VERSION "HINBNNNYYNNNYYNNNNNNNNNNNNYNNNYYYNNYNNNNNN/4//%%/4/'%**4NNN///"

NS_ :

BS_:

BU_: VirtualNMTMaster Sensor_3_ID28 Sensor_2_ID27 Sensor_1_ID23 Display_ID10

BO_ 1546 CSDO_010: 8 Vector__XXX
 SG_ ExpectedConfigurationTime11_0002 m117 : 32|32@1+ (1,0) [0|4294967295] ""  Display_ID10
 SG_ ExpectedConfigurationTime11_0003 m116 : 32|32@1+ (1,0) [0|4294967295] ""  Display_ID10
 SG_ ExpectedConfigurationTime11_0004 m115 : 32|32@1+ (1,0) [0|4294967295] ""  Display_ID10
 SG_ ExpectedConfigurationTime11_0005 m114 : 32|32@1+ (1,0) [0|4294967295] ""  Display_ID10
 SG_ ExpectedConfigurationTime11_0006 m113 : 32|32@1+ (1,0) [0|4294967295] ""  Display_ID10
 SG_ ExpectedConfigurationTime11_0007 m112 : 32|32@1+ (1,0) [0|4294967295] ""  Display_ID10
 SG_ ExpectedConfigurationTime11_0008 m111 : 32|32@1+ (1,0) [0|4294967295] ""  Display_ID10
 SG_ ExpectedConfigurationTime11_0009 m110 : 32|32@1+ (1,0) [0|4294967295] ""  Display_ID10
 SG_ ExpectedConfigurationTime10_0000 m109 : 32|32@1+ (1,0) [0|4294967295] ""  Display_ID10
 SG_ ExpectedConfigurationTime10_0001 m108 : 32|32@1+ (1,0) [0|4294967295] ""  Display_ID10
 SG_ ExpectedConfigurationTime10_0002 m107 : 32|32@1+ (1,0) [0|4294967295] ""  Display_ID10
 SG_ ExpectedConfigurationTime10_0003 m106 : 32|32@1+ (1,0) [0|4294967295] ""  Display_ID10
 SG_ ExpectedConfigurationTime10_0004 m105 : 32|32@1+ (1,0) [0|4294967295] ""  Display_ID10
 SG_ ExpectedConfigurationTime10_0005 m104 : 32|32@1+ (1,0) [0|4294967295] ""  Display_ID10
 SG_ ExpectedConfigurationTime10_0006 m103 : 32|32@1+ (1,0) [0|4294967295] ""  Display_ID10
 SG_ ExpectedConfigurationTime10_0007 m102 : 32|32@1+ (1,0) [0|4294967295] ""  Display_ID10
 SG_ ExpectedConfigurationTime10_0008 m101 : 32|32@1+ (1,0) [0|4294967295] ""  Display_ID10
 SG_ ExpectedConfigurationTime10_0009 m100 : 32|32@1+ (1,0) [0|4294967295] ""  Display_ID10
 SG_ ExpectedConfigurationTime99_0000 m99 : 32|32@1+ (1,0) [0|4294967295] ""  Display_ID10
 SG_ ExpectedConfigurationTime98_0000 m98 : 32|32@1+ (1,0) [0|4294967295] ""  Display_ID10
 SG_ ExpectedConfigurationTime97_0000 m97 : 32|32@1+ (1,0) [0|4294967295] ""  Display_ID10
 SG_ ExpectedConfigurationTime96_0000 m96 : 32|32@1+ (1,0) [0|4294967295] ""  Display_ID10
 SG_ ExpectedConfigurationTime95_0000 m95 : 32|32@1+ (1,0) [0|4294967295] ""  Display_ID10
 SG_ ExpectedConfigurationTime94_0000 m94 : 32|32@1+ (1,0) [0|4294967295] ""  Display_ID10
 SG_ ExpectedConfigurationTime93_0000 m93 : 32|32@1+ (1,0) [0|4294967295] ""  Display_ID10
 SG_ ExpectedConfigurationTime92_0000 m92 : 32|32@1+ (1,0) [0|4294967295] ""  Display_ID10
 SG_ ExpectedConfigurationTime91_0000 m91 : 32|32@1+ (1,0) [0|4294967295] ""  Display_ID10
 SG_ ExpectedConfigurationTime90_0000 m90 : 32|32@1+ (1,0) [0|4294967295] ""  Display_ID10
 SG_ ExpectedConfigurationTime89_0000 m89 : 32|32@1+ (1,0) [0|4294967295] ""  Display_ID10
 SG_ ExpectedConfigurationTime88_0000 m88 : 32|32@1+ (1,0) [0|4294967295] ""  Display_ID10
 SG_ ExpectedConfigurationTime87_0000 m87 : 32|32@1+ (1,0) [0|4294967295] ""  Display_ID10
 SG_ ExpectedConfigurationTime86_0000 m86 : 32|32@1+ (1,0) [0|4294967295] ""  Display_ID10
 SG_ ExpectedConfigurationTime85_0000 m85 : 32|32@1+ (1,0) [0|4294967295] ""  Display_ID10
 SG_ ExpectedConfigurationTime84_0000 m84 : 32|32@1+ (1,0) [0|4294967295] ""  Display_ID10
 SG_ ExpectedConfigurationTime83_0000 m83 : 32|32@1+ (1,0) [0|4294967295] ""  Display_ID10
 SG_ ExpectedConfigurationTime82_0000 m82 : 32|32@1+ (1,0) [0|4294967295] ""  Display_ID10
 SG_ ExpectedConfigurationTime81_0000 m81 : 32|32@1+ (1,0) [0|4294967295] ""  Display_ID10
 SG_ ExpectedConfigurationTime80_0000 m80 : 32|32@1+ (1,0) [0|4294967295] ""  Display_ID10
 SG_ ExpectedConfigurationTime79_0000 m79 : 32|32@1+ (1,0) [0|4294967295] ""  Display_ID10
 SG_ ExpectedConfigurationTime78_0000 m78 : 32|32@1+ (1,0) [0|4294967295] ""  Display_ID10
 SG_ ExpectedConfigurationTime77_0000 m77 : 32|32@1+ (1,0) [0|4294967295] ""  Display_ID10
 SG_ ExpectedConfigurationTime76_0000 m76 : 32|32@1+ (1,0) [0|4294967295] ""  Display_ID10
 SG_ ExpectedConfigurationTime75_0000 m75 : 32|32@1+ (1,0) [0|4294967295] ""  Display_ID10
 SG_ ExpectedConfigurationTime74_0000 m74 : 32|32@1+ (1,0) [0|4294967295] ""  Display_ID10
 SG_ ExpectedConfigurationTime73_0000 m73 : 32|32@1+ (1,0) [0|4294967295] ""  Display_ID10
 SG_ ExpectedConfigurationTime72_0000 m72 : 32|32@1+ (1,0) [0|4294967295] ""  Display_ID10
 SG_ ExpectedConfigurationTime71_0000 m71 : 32|32@1+ (1,0) [0|4294967295] ""  Display_ID10
 SG_ ExpectedConfigurationTime70_0000 m70 : 32|32@1+ (1,0) [0|4294967295] ""  Display_ID10
 SG_ ExpectedConfigurationTime69_0000 m69 : 32|32@1+ (1,0) [0|4294967295] ""  Display_ID10
 SG_ ExpectedConfigurationTime68_0000 m68 : 32|32@1+ (1,0) [0|4294967295] ""  Display_ID10
 SG_ ExpectedConfigurationTime67_0000 m67 : 32|32@1+ (1,0) [0|4294967295] ""  Display_ID10
 SG_ ExpectedConfigurationTime66_0000 m66 : 32|32@1+ (1,0) [0|4294967295] ""  Display_ID10
 SG_ ExpectedConfigurationTime65_0000 m65 : 32|32@1+ (1,0) [0|4294967295] ""  Display_ID10
 SG_ ExpectedConfigurationTime64_0000 m64 : 32|32@1+ (1,0) [0|4294967295] ""  Display_ID10
 SG_ ExpectedConfigurationTime63_0000 m63 : 32|32@1+ (1,0) [0|4294967295] ""  Display_ID10
 SG_ ExpectedConfigurationTime62_0000 m62 : 32|32@1+ (1,0) [0|4294967295] ""  Display_ID10
 SG_ ExpectedConfigurationTime61_0000 m61 : 32|32@1+ (1,0) [0|4294967295] ""  Display_ID10
 SG_ ExpectedConfigurationTime60_0000 m60 : 32|32@1+ (1,0) [0|4294967295] ""  Display_ID10
 SG_ ExpectedConfigurationTime59_0000 m59 : 32|32@1+ (1,0) [0|4294967295] ""  Display_ID10
 SG_ ExpectedConfigurationTime58_0000 m58 : 32|32@1+ (1,0) [0|4294967295] ""  Display_ID10
 SG_ ExpectedConfigurationTime57_0000 m57 : 32|32@1+ (1,0) [0|4294967295] ""  Display_ID10
 SG_ ExpectedConfigurationTime56_0000 m56 : 32|32@1+ (1,0) [0|4294967295] ""  Display_ID10
 SG_ ExpectedConfigurationTime55_0000 m55 : 32|32@1+ (1,0) [0|4294967295] ""  Display_ID10
 SG_ ExpectedConfigurationTime54_0000 m54 : 32|32@1+ (1,0) [0|4294967295] ""  Display_ID10
 SG_ ExpectedConfigurationTime53_0000 m53 : 32|32@1+ (1,0) [0|4294967295] ""  Display_ID10
 SG_ ExpectedConfigurationTime52_0000 m52 : 32|32@1+ (1,0) [0|4294967295] ""  Display_ID10
 SG_ ExpectedConfigurationTime51_0000 m51 : 32|32@1+ (1,0) [0|4294967295] ""  Display_ID10
 SG_ ExpectedConfigurationTime50_0000 m50 : 32|32@1+ (1,0) [0|4294967295] ""  Display_ID10
 SG_ ExpectedConfigurationTime49_0000 m49 : 32|32@1+ (1,0) [0|4294967295] ""  Display_ID10
 SG_ ExpectedConfigurationTime48_0000 m48 : 32|32@1+ (1,0) [0|4294967295] ""  Display_ID10
 SG_ ExpectedConfigurationTime47_0000 m47 : 32|32@1+ (1,0) [0|4294967295] ""  Display_ID10
 SG_ ExpectedConfigurationTime46_0000 m46 : 32|32@1+ (1,0) [0|4294967295] ""  Display_ID10
 SG_ ExpectedConfigurationTime45_0000 m45 : 32|32@1+ (1,0) [0|4294967295] ""  Display_ID10
 SG_ ExpectedConfigurationTime44_0000 m44 : 32|32@1+ (1,0) [0|4294967295] ""  Display_ID10
 SG_ ExpectedConfigurationTime43_0000 m43 : 32|32@1+ (1,0) [0|4294967295] ""  Display_ID10
 SG_ ExpectedConfigurationTime42_0000 m42 : 32|32@1+ (1,0) [0|4294967295] ""  Display_ID10
 SG_ ExpectedConfigurationTime41_0000 m41 : 32|32@1+ (1,0) [0|4294967295] ""  Display_ID10
 SG_ ExpectedConfigurationTime40_0000 m40 : 32|32@1+ (1,0) [0|4294967295] ""  Display_ID10
 SG_ ExpectedConfigurationTime39_0000 m39 : 32|32@1+ (1,0) [0|4294967295] ""  Display_ID10
 SG_ ExpectedConfigurationTime38_0000 m38 : 32|32@1+ (1,0) [0|4294967295] ""  Display_ID10
 SG_ ExpectedConfigurationTime37_0000 m37 : 32|32@1+ (1,0) [0|4294967295] ""  Display_ID10
 SG_ ExpectedConfigurationTime36_0000 m36 : 32|32@1+ (1,0) [0|4294967295] ""  Display_ID10
 SG_ ExpectedConfigurationTime35_0000 m35 : 32|32@1+ (1,0) [0|4294967295] ""  Display_ID10
 SG_ ExpectedConfigurationTime34_0000 m34 : 32|32@1+ (1,0) [0|4294967295] ""  Display_ID10
 SG_ ExpectedConfigurationTime33_0000 m33 : 32|32@1+ (1,0) [0|4294967295] ""  Display_ID10
 SG_ ExpectedConfigurationTime32_0000 m32 : 32|32@1+ (1,0) [0|4294967295] ""  Display_ID10
 SG_ ExpectedConfigurationTime31_0000 m31 : 32|32@1+ (1,0) [0|4294967295] ""  Display_ID10
 SG_ ExpectedConfigurationTime30_0000 m30 : 32|32@1+ (1,0) [0|4294967295] ""  Display_ID10
 SG_ ExpectedConfigurationTime29_0000 m29 : 32|32@1+ (1,0) [0|4294967295] ""  Display_ID10
 SG_ ExpectedConfigurationTime28_0000 m28 : 32|32@1+ (1,0) [0|4294967295] ""  Display_ID10
 SG_ ExpectedConfigurationTime27_0000 m27 : 32|32@1+ (1,0) [0|4294967295] ""  Display_ID10
 SG_ ExpectedConfigurationTime26_0000 m26 : 32|32@1+ (1,0) [0|4294967295] ""  Display_ID10
 SG_ ExpectedConfigurationTime25_0000 m25 : 32|32@1+ (1,0) [0|4294967295] ""  Display_ID10
 SG_ ExpectedConfigurationTime24_0000 m24 : 32|32@1+ (1,0) [0|4294967295] ""  Display_ID10
 SG_ ExpectedConfigurationTime23_0000 m23 : 32|32@1+ (1,0) [0|4294967295] ""  Display_ID10
 SG_ ExpectedConfigurationTime22_0000 m22 : 32|32@1+ (1,0) [0|4294967295] ""  Display_ID10
 SG_ ExpectedConfigurationTime21_0000 m21 : 32|32@1+ (1,0) [0|4294967295] ""  Display_ID10
 SG_ ExpectedConfigurationTime20_0000 m20 : 32|32@1+ (1,0) [0|4294967295] ""  Display_ID10
 SG_ ExpectedConfigurationTime19_0000 m19 : 32|32@1+ (1,0) [0|4294967295] ""  Display_ID10
 SG_ ExpectedConfigurationTime18_0000 m18 : 32|32@1+ (1,0) [0|4294967295] ""  Display_ID10
 SG_ ExpectedConfigurationTime17_0000 m17 : 32|32@1+ (1,0) [0|4294967295] ""  Display_ID10
 SG_ ExpectedConfigurationTime16_0000 m16 : 32|32@1+ (1,0) [0|4294967295] ""  Display_ID10
 SG_ ExpectedConfigurationTime15_0000 m15 : 32|32@1+ (1,0) [0|4294967295] ""  Display_ID10
 SG_ ExpectedConfigurationTime14_0000 m14 : 32|32@1+ (1,0) [0|4294967295] ""  Display_ID10
 SG_ ExpectedConfigurationTime13_0000 m13 : 32|32@1+ (1,0) [0|4294967295] ""  Display_ID10
 SG_ ExpectedConfigurationTime12_0008 m12 : 32|32@1+ (1,0) [0|4294967295] ""  Display_ID10
 SG_ ExpectedConfigurationTime11_0010 m11 : 32|32@1+ (1,0) [0|4294967295] ""  Display_ID10
 SG_ ExpectedConfigurationTime10_0010 m10 : 32|32@1+ (1,0) [0|4294967295] ""  Display_ID10
 SG_ ExpectedConfigurationTime9__0000 m9 : 32|32@1+ (1,0) [0|4294967295] ""  Display_ID10
 SG_ ExpectedConfigurationTime8__0000 m8 : 32|32@1+ (1,0) [0|4294967295] ""  Display_ID10
 SG_ ExpectedConfigurationTime7__0000 m7 : 32|32@1+ (1,0) [0|4294967295] ""  Display_ID10
 SG_ ExpectedConfigurationTime6__0000 m6 : 32|32@1+ (1,0) [0|4294967295] ""  Display_ID10
 SG_ ExpectedConfigurationTime5__0000 m5 : 32|32@1+ (1,0) [0|4294967295] ""  Display_ID10
 SG_ ExpectedConfigurationTime4__0000 m4 : 32|32@1+ (1,0) [0|4294967295] ""  Display_ID10
 SG_ ExpectedConfigurationTime3__0000 m3 : 32|32@1+ (1,0) [0|4294967295] ""  Display_ID10
 SG_ ExpectedConfigurationTime2__0000 m2 : 32|32@1+ (1,0) [0|4294967295] ""  Display_ID10
 SG_ ExpectedConfigurationTime1__0000 m1 : 32|32@1+ (1,0) [0|4294967295] ""  Display_ID10
 SG_ NrOfObjects_1F27_00 m0 : 32|8@1+ (1,0) [0|255] ""  Display_ID10
 SG_ SubIndex_1F27 m7975M : 24|8@1+ (1,0) [0|127] ""  Display_ID10
 SG_ ExpectedConfigurationDate12_0000 m127 : 32|32@1+ (1,0) [0|4294967295] ""  Display_ID10
 SG_ ExpectedConfigurationDate12_0001 m126 : 32|32@1+ (1,0) [0|4294967295] ""  Display_ID10
 SG_ ExpectedConfigurationDate12_0002 m125 : 32|32@1+ (1,0) [0|4294967295] ""  Display_ID10
 SG_ ExpectedConfigurationDate12_0003 m124 : 32|32@1+ (1,0) [0|4294967295] ""  Display_ID10
 SG_ ExpectedConfigurationDate12_0004 m123 : 32|32@1+ (1,0) [0|4294967295] ""  Display_ID10
 SG_ ExpectedConfigurationDate12_0005 m122 : 32|32@1+ (1,0) [0|4294967295] ""  Display_ID10
 SG_ ExpectedConfigurationDate12_0006 m121 : 32|32@1+ (1,0) [0|4294967295] ""  Display_ID10
 SG_ ExpectedConfigurationDate12_0007 m120 : 32|32@1+ (1,0) [0|4294967295] ""  Display_ID10
 SG_ ExpectedConfigurationDate11_0000 m119 : 32|32@1+ (1,0) [0|4294967295] ""  Display_ID10
 SG_ ExpectedConfigurationDate11_0001 m118 : 32|32@1+ (1,0) [0|4294967295] ""  Display_ID10
 SG_ ExpectedConfigurationDate11_0002 m117 : 32|32@1+ (1,0) [0|4294967295] ""  Display_ID10
 SG_ ExpectedConfigurationDate11_0003 m116 : 32|32@1+ (1,0) [0|4294967295] ""  Display_ID10
 SG_ ExpectedConfigurationDate11_0004 m115 : 32|32@1+ (1,0) [0|4294967295] ""  Display_ID10
 SG_ ExpectedConfigurationDate11_0005 m114 : 32|32@1+ (1,0) [0|4294967295] ""  Display_ID10
 SG_ ExpectedConfigurationDate11_0006 m113 : 32|32@1+ (1,0) [0|4294967295] ""  Display_ID10
 SG_ ExpectedConfigurationDate11_0007 m112 : 32|32@1+ (1,0) [0|4294967295] ""  Display_ID10
 SG_ ExpectedConfigurationDate11_0008 m111 : 32|32@1+ (1,0) [0|4294967295] ""  Display_ID10
 SG_ ExpectedConfigurationDate11_0009 m110 : 32|32@1+ (1,0) [0|4294967295] ""  Display_ID10
 SG_ ExpectedConfigurationDate10_0000 m109 : 32|32@1+ (1,0) [0|4294967295] ""  Display_ID10
 SG_ ExpectedConfigurationDate10_0001 m108 : 32|32@1+ (1,0) [0|4294967295] ""  Display_ID10
 SG_ ExpectedConfigurationDate10_0002 m107 : 32|32@1+ (1,0) [0|4294967295] ""  Display_ID10
 SG_ ExpectedConfigurationDate10_0003 m106 : 32|32@1+ (1,0) [0|4294967295] ""  Display_ID10
 SG_ ExpectedConfigurationDate10_0004 m105 : 32|32@1+ (1,0) [0|4294967295] ""  Display_ID10
 SG_ ExpectedConfigurationDate10_0005 m104 : 32|32@1+ (1,0) [0|4294967295] ""  Display_ID10
 SG_ ExpectedConfigurationDate10_0006 m103 : 32|32@1+ (1,0) [0|4294967295] ""  Display_ID10
 SG_ ExpectedConfigurationDate10_0007 m102 : 32|32@1+ (1,0) [0|4294967295] ""  Display_ID10
 SG_ ExpectedConfigurationDate10_0008 m101 : 32|32@1+ (1,0) [0|4294967295] ""  Display_ID10
 SG_ ExpectedConfigurationDate10_0009 m100 : 32|32@1+ (1,0) [0|4294967295] ""  Display_ID10
 SG_ ExpectedConfigurationDate99_0000 m99 : 32|32@1+ (1,0) [0|4294967295] ""  Display_ID10
 SG_ ExpectedConfigurationDate98_0000 m98 : 32|32@1+ (1,0) [0|4294967295] ""  Display_ID10
 SG_ ExpectedConfigurationDate97_0000 m97 : 32|32@1+ (1,0) [0|4294967295] ""  Display_ID10
 SG_ ExpectedConfigurationDate96_0000 m96 : 32|32@1+ (1,0) [0|4294967295] ""  Display_ID10
 SG_ ExpectedConfigurationDate95_0000 m95 : 32|32@1+ (1,0) [0|4294967295] ""  Display_ID10
 SG_ ExpectedConfigurationDate94_0000 m94 : 32|32@1+ (1,0) [0|4294967295] ""  Display_ID10
 SG_ ExpectedConfigurationDate93_0000 m93 : 32|32@1+ (1,0) [0|4294967295] ""  Display_ID10
 SG_ ExpectedConfigurationDate92_0000 m92 : 32|32@1+ (1,0) [0|4294967295] ""  Display_ID10
 SG_ ExpectedConfigurationDate91_0000 m91 : 32|32@1+ (1,0) [0|4294967295] ""  Display_ID10
 SG_ ExpectedConfigurationDate90_0000 m90 : 32|32@1+ (1,0) [0|4294967295] ""  Display_ID10
 SG_ ExpectedConfigurationDate89_0000 m89 : 32|32@1+ (1,0) [0|4294967295] ""  Display_ID10
 SG_ ExpectedConfigurationDate88_0000 m88 : 32|32@1+ (1,0) [0|4294967295] ""  Display_ID10
 SG_ ExpectedConfigurationDate87_0000 m87 : 32|32@1+ (1,0) [0|4294967295] ""  Display_ID10
 SG_ ExpectedConfigurationDate86_0000 m86 : 32|32@1+ (1,0) [0|4294967295] ""  Display_ID10
 SG_ ExpectedConfigurationDate85_0000 m85 : 32|32@1+ (1,0) [0|4294967295] ""  Display_ID10
 SG_ ExpectedConfigurationDate84_0000 m84 : 32|32@1+ (1,0) [0|4294967295] ""  Display_ID10
 SG_ ExpectedConfigurationDate83_0000 m83 : 32|32@1+ (1,0) [0|4294967295] ""  Display_ID10
 SG_ ExpectedConfigurationDate82_0000 m82 : 32|32@1+ (1,0) [0|4294967295] ""  Display_ID10
 SG_ ExpectedConfigurationDate81_0000 m81 : 32|32@1+ (1,0) [0|4294967295] ""  Display_ID10
 SG_ ExpectedConfigurationDate80_0000 m80 : 32|32@1+ (1,0) [0|4294967295] ""  Display_ID10
 SG_ ExpectedConfigurationDate79_0000 m79 : 32|32@1+ (1,0) [0|4294967295] ""  Display_ID10
 SG_ ExpectedConfigurationDate78_0000 m78 : 32|32@1+ (1,0) [0|4294967295] ""  Display_ID10
 SG_ ExpectedConfigurationDate77_0000 m77 : 32|32@1+ (1,0) [0|4294967295] ""  Display_ID10
 SG_ ExpectedConfigurationDate76_0000 m76 : 32|32@1+ (1,0) [0|4294967295] ""  Display_ID10
 SG_ ExpectedConfigurationDate75_0000 m75 : 32|32@1+ (1,0) [0|4294967295] ""  Display_ID10
 SG_ ExpectedConfigurationDate74_0000 m74 : 32|32@1+ (1,0) [0|4294967295] ""  Display_ID10
 SG_ ExpectedConfigurationDate73_0000 m73 : 32|32@1+ (1,0) [0|4294967295] ""  Display_ID10
 SG_ ExpectedConfigurationDate72_0000 m72 : 32|32@1+ (1,0) [0|4294967295] ""  Display_ID10
 SG_ ExpectedConfigurationDate71_0000 m71 : 32|32@1+ (1,0) [0|4294967295] ""  Display_ID10
 SG_ ExpectedConfigurationDate70_0000 m70 : 32|32@1+ (1,0) [0|4294967295] ""  Display_ID10
 SG_ ExpectedConfigurationDate69_0000 m69 : 32|32@1+ (1,0) [0|4294967295] ""  Display_ID10
 SG_ ExpectedConfigurationDate68_0000 m68 : 32|32@1+ (1,0) [0|4294967295] ""  Display_ID10
 SG_ ExpectedConfigurationDate67_0000 m67 : 32|32@1+ (1,0) [0|4294967295] ""  Display_ID10
 SG_ ExpectedConfigurationDate66_0000 m66 : 32|32@1+ (1,0) [0|4294967295] ""  Display_ID10
 SG_ ExpectedConfigurationDate65_0000 m65 : 32|32@1+ (1,0) [0|4294967295] ""  Display_ID10
 SG_ ExpectedConfigurationDate64_0000 m64 : 32|32@1+ (1,0) [0|4294967295] ""  Display_ID10
 SG_ ExpectedConfigurationDate63_0000 m63 : 32|32@1+ (1,0) [0|4294967295] ""  Display_ID10
 SG_ ExpectedConfigurationDate62_0000 m62 : 32|32@1+ (1,0) [0|4294967295] ""  Display_ID10
 SG_ ExpectedConfigurationDate61_0000 m61 : 32|32@1+ (1,0) [0|4294967295] ""  Display_ID10
 SG_ ExpectedConfigurationDate60_0000 m60 : 32|32@1+ (1,0) [0|4294967295] ""  Display_ID10
 SG_ ExpectedConfigurationDate59_0000 m59 : 32|32@1+ (1,0) [0|4294967295] ""  Display_ID10
 SG_ ExpectedConfigurationDate58_0000 m58 : 32|32@1+ (1,0) [0|4294967295] ""  Display_ID10
 SG_ ExpectedConfigurationDate57_0000 m57 : 32|32@1+ (1,0) [0|4294967295] ""  Display_ID10
 SG_ ExpectedConfigurationDate56_0000 m56 : 32|32@1+ (1,0) [0|4294967295] ""  Display_ID10
 SG_ ExpectedConfigurationDate55_0000 m55 : 32|32@1+ (1,0) [0|4294967295] ""  Display_ID10
 SG_ ExpectedConfigurationDate54_0000 m54 : 32|32@1+ (1,0) [0|4294967295] ""  Display_ID10
 SG_ ExpectedConfigurationDate53_0000 m53 : 32|32@1+ (1,0) [0|4294967295] ""  Display_ID10
 SG_ ExpectedConfigurationDate52_0000 m52 : 32|32@1+ (1,0) [0|4294967295] ""  Display_ID10
 SG_ ExpectedConfigurationDate51_0000 m51 : 32|32@1+ (1,0) [0|4294967295] ""  Display_ID10
 SG_ ExpectedConfigurationDate50_0000 m50 : 32|32@1+ (1,0) [0|4294967295] ""  Display_ID10
 SG_ ExpectedConfigurationDate49_0000 m49 : 32|32@1+ (1,0) [0|4294967295] ""  Display_ID10
 SG_ ExpectedConfigurationDate48_0000 m48 : 32|32@1+ (1,0) [0|4294967295] ""  Display_ID10
 SG_ ExpectedConfigurationDate47_0000 m47 : 32|32@1+ (1,0) [0|4294967295] ""  Display_ID10
 SG_ ExpectedConfigurationDate46_0000 m46 : 32|32@1+ (1,0) [0|4294967295] ""  Display_ID10
 SG_ ExpectedConfigurationDate45_0000 m45 : 32|32@1+ (1,0) [0|4294967295] ""  Display_ID10
 SG_ ExpectedConfigurationDate44_0000 m44 : 32|32@1+ (1,0) [0|4294967295] ""  Display_ID10
 SG_ ExpectedConfigurationDate43_0000 m43 : 32|32@1+ (1,0) [0|4294967295] ""  Display_ID10
 SG_ ExpectedConfigurationDate42_0000 m42 : 32|32@1+ (1,0) [0|4294967295] ""  Display_ID10
 SG_ ExpectedConfigurationDate41_0000 m41 : 32|32@1+ (1,0) [0|4294967295] ""  Display_ID10
 SG_ ExpectedConfigurationDate40_0000 m40 : 32|32@1+ (1,0) [0|4294967295] ""  Display_ID10
 SG_ ExpectedConfigurationDate39_0000 m39 : 32|32@1+ (1,0) [0|4294967295] ""  Display_ID10
 SG_ ExpectedConfigurationDate38_0000 m38 : 32|32@1+ (1,0) [0|4294967295] ""  Display_ID10
 SG_ ExpectedConfigurationDate37_0000 m37 : 32|32@1+ (1,0) [0|4294967295] ""  Display_ID10
 SG_ ExpectedConfigurationDate36_0000 m36 : 32|32@1+ (1,0) [0|4294967295] ""  Display_ID10
 SG_ ExpectedConfigurationDate35_0000 m35 : 32|32@1+ (1,0) [0|4294967295] ""  Display_ID10
 SG_ ExpectedConfigurationDate34_0000 m34 : 32|32@1+ (1,0) [0|4294967295] ""  Display_ID10
 SG_ ExpectedConfigurationDate33_0000 m33 : 32|32@1+ (1,0) [0|4294967295] ""  Display_ID10
 SG_ ExpectedConfigurationDate32_0000 m32 : 32|32@1+ (1,0) [0|4294967295] ""  Display_ID10
 SG_ ExpectedConfigurationDate31_0000 m31 : 32|32@1+ (1,0) [0|4294967295] ""  Display_ID10
 SG_ ExpectedConfigurationDate30_0000 m30 : 32|32@1+ (1,0) [0|4294967295] ""  Display_ID10
 SG_ ExpectedConfigurationDate29_0000 m29 : 32|32@1+ (1,0) [0|4294967295] ""  Display_ID10
 SG_ ExpectedConfigurationDate28_0000 m28 : 32|32@1+ (1,0) [0|4294967295] ""  Display_ID10
 SG_ ExpectedConfigurationDate27_0000 m27 : 32|32@1+ (1,0) [0|4294967295] ""  Display_ID10
 SG_ ExpectedConfigurationDate26_0000 m26 : 32|32@1+ (1,0) [0|4294967295] ""  Display_ID10
 SG_ ExpectedConfigurationDate25_0000 m25 : 32|32@1+ (1,0) [0|4294967295] ""  Display_ID10
 SG_ ExpectedConfigurationDate24_0000 m24 : 32|32@1+ (1,0) [0|4294967295] ""  Display_ID10
 SG_ ExpectedConfigurationDate23_0000 m23 : 32|32@1+ (1,0) [0|4294967295] ""  Display_ID10
 SG_ ExpectedConfigurationDate22_0000 m22 : 32|32@1+ (1,0) [0|4294967295] ""  Display_ID10
 SG_ ExpectedConfigurationDate21_0000 m21 : 32|32@1+ (1,0) [0|4294967295] ""  Display_ID10
 SG_ ExpectedConfigurationDate20_0000 m20 : 32|32@1+ (1,0) [0|4294967295] ""  Display_ID10
 SG_ ExpectedConfigurationDate19_0000 m19 : 32|32@1+ (1,0) [0|4294967295] ""  Display_ID10
 SG_ ExpectedConfigurationDate18_0000 m18 : 32|32@1+ (1,0) [0|4294967295] ""  Display_ID10
 SG_ ExpectedConfigurationDate17_0000 m17 : 32|32@1+ (1,0) [0|4294967295] ""  Display_ID10
 SG_ ExpectedConfigurationDate16_0000 m16 : 32|32@1+ (1,0) [0|4294967295] ""  Display_ID10
 SG_ ExpectedConfigurationDate15_0000 m15 : 32|32@1+ (1,0) [0|4294967295] ""  Display_ID10
 SG_ ExpectedConfigurationDate14_0000 m14 : 32|32@1+ (1,0) [0|4294967295] ""  Display_ID10
 SG_ ExpectedConfigurationDate13_0000 m13 : 32|32@1+ (1,0) [0|4294967295] ""  Display_ID10
 SG_ ExpectedConfigurationDate12_0008 m12 : 32|32@1+ (1,0) [0|4294967295] ""  Display_ID10
 SG_ ExpectedConfigurationDate11_0010 m11 : 32|32@1+ (1,0) [0|4294967295] ""  Display_ID10
 SG_ ExpectedConfigurationDate10_0010 m10 : 32|32@1+ (1,0) [0|4294967295] ""  Display_ID10
 SG_ ExpectedConfigurationDate9__0000 m9 : 32|32@1+ (1,0) [0|4294967295] ""  Display_ID10
 SG_ ExpectedConfigurationDate8__0000 m8 : 32|32@1+ (1,0) [0|4294967295] ""  Display_ID10
 SG_ ExpectedConfigurationDate7__0000 m7 : 32|32@1+ (1,0) [0|4294967295] ""  Display_ID10
 SG_ ExpectedConfigurationDate6__0000 m6 : 32|32@1+ (1,0) [0|4294967295] ""  Display_ID10
 SG_ ExpectedConfigurationDate5__0000 m5 : 32|32@1+ (1,0) [0|4294967295] ""  Display_ID10
 SG_ ExpectedConfigurationDate4__0000 m4 : 32|32@1+ (1,0) [0|4294967295] ""  Display_ID10
 SG_ ExpectedConfigurationDate3__0000 m3 : 32|32@1+ (1,0) [0|4294967295] ""  Display_ID10
 SG_ ExpectedConfigurationDate2__0000 m2 : 32|32@1+ (1,0) [0|4294967295] ""  Display_ID10
 SG_ ExpectedConfigurationDate1__0000 m1 : 32|32@1+ (1,0) [0|4294967295] ""  Display_ID10
 SG_ NrOfObjects_1F26_00 m0 : 32|8@1+ (1,0) [0|255] ""  Display_ID10
 SG_ SubIndex_1F26 m7974M : 24|8@1+ (1,0) [0|127] ""  Display_ID10
 SG_ Configure_Slaves128_1F25_80 m128 : 32|32@1+ (1,0) [0|4294967295] ""  Display_ID10
 SG_ Configure_Slaves127_1F25_7F m127 : 32|32@1+ (1,0) [0|4294967295] ""  Display_ID10
 SG_ Configure_Slaves126_1F25_7E m126 : 32|32@1+ (1,0) [0|4294967295] ""  Display_ID10
 SG_ Configure_Slaves125_1F25_7D m125 : 32|32@1+ (1,0) [0|4294967295] ""  Display_ID10
 SG_ Configure_Slaves124_1F25_7C m124 : 32|32@1+ (1,0) [0|4294967295] ""  Display_ID10
 SG_ Configure_Slaves123_1F25_7B m123 : 32|32@1+ (1,0) [0|4294967295] ""  Display_ID10
 SG_ Configure_Slaves122_1F25_7A m122 : 32|32@1+ (1,0) [0|4294967295] ""  Display_ID10
 SG_ Configure_Slaves121_1F25_79 m121 : 32|32@1+ (1,0) [0|4294967295] ""  Display_ID10
 SG_ Configure_Slaves120_1F25_78 m120 : 32|32@1+ (1,0) [0|4294967295] ""  Display_ID10
 SG_ Configure_Slaves119_1F25_77 m119 : 32|32@1+ (1,0) [0|4294967295] ""  Display_ID10
 SG_ Configure_Slaves118_1F25_76 m118 : 32|32@1+ (1,0) [0|4294967295] ""  Display_ID10
 SG_ Configure_Slaves117_1F25_75 m117 : 32|32@1+ (1,0) [0|4294967295] ""  Display_ID10
 SG_ Configure_Slaves116_1F25_74 m116 : 32|32@1+ (1,0) [0|4294967295] ""  Display_ID10
 SG_ Configure_Slaves115_1F25_73 m115 : 32|32@1+ (1,0) [0|4294967295] ""  Display_ID10
 SG_ Configure_Slaves114_1F25_72 m114 : 32|32@1+ (1,0) [0|4294967295] ""  Display_ID10
 SG_ Configure_Slaves113_1F25_71 m113 : 32|32@1+ (1,0) [0|4294967295] ""  Display_ID10
 SG_ Configure_Slaves112_1F25_70 m112 : 32|32@1+ (1,0) [0|4294967295] ""  Display_ID10
 SG_ Configure_Slaves111_1F25_6F m111 : 32|32@1+ (1,0) [0|4294967295] ""  Display_ID10
 SG_ Configure_Slaves110_1F25_6E m110 : 32|32@1+ (1,0) [0|4294967295] ""  Display_ID10
 SG_ Configure_Slaves109_1F25_6D m109 : 32|32@1+ (1,0) [0|4294967295] ""  Display_ID10
 SG_ Configure_Slaves108_1F25_6C m108 : 32|32@1+ (1,0) [0|4294967295] ""  Display_ID10
 SG_ Configure_Slaves107_1F25_6B m107 : 32|32@1+ (1,0) [0|4294967295] ""  Display_ID10
 SG_ Configure_Slaves106_1F25_6A m106 : 32|32@1+ (1,0) [0|4294967295] ""  Display_ID10
 SG_ Configure_Slaves105_1F25_69 m105 : 32|32@1+ (1,0) [0|4294967295] ""  Display_ID10
 SG_ Configure_Slaves104_1F25_68 m104 : 32|32@1+ (1,0) [0|4294967295] ""  Display_ID10
 SG_ Configure_Slaves103_1F25_67 m103 : 32|32@1+ (1,0) [0|4294967295] ""  Display_ID10
 SG_ Configure_Slaves102_1F25_66 m102 : 32|32@1+ (1,0) [0|4294967295] ""  Display_ID10
 SG_ Configure_Slaves101_1F25_65 m101 : 32|32@1+ (1,0) [0|4294967295] ""  Display_ID10
 SG_ Configure_Slaves100_1F25_64 m100 : 32|32@1+ (1,0) [0|4294967295] ""  Display_ID10
 SG_ Configure_Slaves99_1F25_63 m99 : 32|32@1+ (1,0) [0|4294967295] ""  Display_ID10
 SG_ Configure_Slaves98_1F25_62 m98 : 32|32@1+ (1,0) [0|4294967295] ""  Display_ID10
 SG_ Configure_Slaves97_1F25_61 m97 : 32|32@1+ (1,0) [0|4294967295] ""  Display_ID10
 SG_ Configure_Slaves96_1F25_60 m96 : 32|32@1+ (1,0) [0|4294967295] ""  Display_ID10
 SG_ Configure_Slaves95_1F25_5F m95 : 32|32@1+ (1,0) [0|4294967295] ""  Display_ID10
 SG_ Configure_Slaves94_1F25_5E m94 : 32|32@1+ (1,0) [0|4294967295] ""  Display_ID10
 SG_ Configure_Slaves93_1F25_5D m93 : 32|32@1+ (1,0) [0|4294967295] ""  Display_ID10
 SG_ Configure_Slaves92_1F25_5C m92 : 32|32@1+ (1,0) [0|4294967295] ""  Display_ID10
 SG_ Configure_Slaves91_1F25_5B m91 : 32|32@1+ (1,0) [0|4294967295] ""  Display_ID10
 SG_ Configure_Slaves90_1F25_5A m90 : 32|32@1+ (1,0) [0|4294967295] ""  Display_ID10
 SG_ Configure_Slaves89_1F25_59 m89 : 32|32@1+ (1,0) [0|4294967295] ""  Display_ID10
 SG_ Configure_Slaves88_1F25_58 m88 : 32|32@1+ (1,0) [0|4294967295] ""  Display_ID10
 SG_ Configure_Slaves87_1F25_57 m87 : 32|32@1+ (1,0) [0|4294967295] ""  Display_ID10
 SG_ Configure_Slaves86_1F25_56 m86 : 32|32@1+ (1,0) [0|4294967295] ""  Display_ID10
 SG_ Configure_Slaves85_1F25_55 m85 : 32|32@1+ (1,0) [0|4294967295] ""  Display_ID10
 SG_ Configure_Slaves84_1F25_54 m84 : 32|32@1+ (1,0) [0|4294967295] ""  Display_ID10
 SG_ Configure_Slaves83_1F25_53 m83 : 32|32@1+ (1,0) [0|4294967295] ""  Display_ID10
 SG_ Configure_Slaves82_1F25_52 m82 : 32|32@1+ (1,0) [0|4294967295] ""  Display_ID10
 SG_ Configure_Slaves81_1F25_51 m81 : 32|32@1+ (1,0) [0|4294967295] ""  Display_ID10
 SG_ Configure_Slaves80_1F25_50 m80 : 32|32@1+ (1,0) [0|4294967295] ""  Display_ID10
 SG_ Configure_Slaves79_1F25_4F m79 : 32|32@1+ (1,0) [0|4294967295] ""  Display_ID10
 SG_ Configure_Slaves78_1F25_4E m78 : 32|32@1+ (1,0) [0|4294967295] ""  Display_ID10
 SG_ Configure_Slaves77_1F25_4D m77 : 32|32@1+ (1,0) [0|4294967295] ""  Display_ID10
 SG_ Configure_Slaves76_1F25_4C m76 : 32|32@1+ (1,0) [0|4294967295] ""  Display_ID10
 SG_ Configure_Slaves75_1F25_4B m75 : 32|32@1+ (1,0) [0|4294967295] ""  Display_ID10
 SG_ Configure_Slaves74_1F25_4A m74 : 32|32@1+ (1,0) [0|4294967295] ""  Display_ID10
 SG_ Configure_Slaves73_1F25_49 m73 : 32|32@1+ (1,0) [0|4294967295] ""  Display_ID10
 SG_ Configure_Slaves72_1F25_48 m72 : 32|32@1+ (1,0) [0|4294967295] ""  Display_ID10
 SG_ Configure_Slaves71_1F25_47 m71 : 32|32@1+ (1,0) [0|4294967295] ""  Display_ID10
 SG_ Configure_Slaves70_1F25_46 m70 : 32|32@1+ (1,0) [0|4294967295] ""  Display_ID10
 SG_ Configure_Slaves69_1F25_45 m69 : 32|32@1+ (1,0) [0|4294967295] ""  Display_ID10
 SG_ Configure_Slaves68_1F25_44 m68 : 32|32@1+ (1,0) [0|4294967295] ""  Display_ID10
 SG_ Configure_Slaves67_1F25_43 m67 : 32|32@1+ (1,0) [0|4294967295] ""  Display_ID10
 SG_ Configure_Slaves66_1F25_42 m66 : 32|32@1+ (1,0) [0|4294967295] ""  Display_ID10
 SG_ Configure_Slaves65_1F25_41 m65 : 32|32@1+ (1,0) [0|4294967295] ""  Display_ID10
 SG_ Configure_Slaves64_1F25_40 m64 : 32|32@1+ (1,0) [0|4294967295] ""  Display_ID10
 SG_ Configure_Slaves63_1F25_3F m63 : 32|32@1+ (1,0) [0|4294967295] ""  Display_ID10
 SG_ Configure_Slaves62_1F25_3E m62 : 32|32@1+ (1,0) [0|4294967295] ""  Display_ID10
 SG_ Configure_Slaves61_1F25_3D m61 : 32|32@1+ (1,0) [0|4294967295] ""  Display_ID10
 SG_ Configure_Slaves60_1F25_3C m60 : 32|32@1+ (1,0) [0|4294967295] ""  Display_ID10
 SG_ Configure_Slaves59_1F25_3B m59 : 32|32@1+ (1,0) [0|4294967295] ""  Display_ID10
 SG_ Configure_Slaves58_1F25_3A m58 : 32|32@1+ (1,0) [0|4294967295] ""  Display_ID10
 SG_ Configure_Slaves57_1F25_39 m57 : 32|32@1+ (1,0) [0|4294967295] ""  Display_ID10
 SG_ Configure_Slaves56_1F25_38 m56 : 32|32@1+ (1,0) [0|4294967295] ""  Display_ID10
 SG_ Configure_Slaves55_1F25_37 m55 : 32|32@1+ (1,0) [0|4294967295] ""  Display_ID10
 SG_ Configure_Slaves54_1F25_36 m54 : 32|32@1+ (1,0) [0|4294967295] ""  Display_ID10
 SG_ Configure_Slaves53_1F25_35 m53 : 32|32@1+ (1,0) [0|4294967295] ""  Display_ID10
 SG_ Configure_Slaves52_1F25_34 m52 : 32|32@1+ (1,0) [0|4294967295] ""  Display_ID10
 SG_ Configure_Slaves51_1F25_33 m51 : 32|32@1+ (1,0) [0|4294967295] ""  Display_ID10
 SG_ Configure_Slaves50_1F25_32 m50 : 32|32@1+ (1,0) [0|4294967295] ""  Display_ID10
 SG_ Configure_Slaves49_1F25_31 m49 : 32|32@1+ (1,0) [0|4294967295] ""  Display_ID10
 SG_ Configure_Slaves48_1F25_30 m48 : 32|32@1+ (1,0) [0|4294967295] ""  Display_ID10
 SG_ Configure_Slaves47_1F25_2F m47 : 32|32@1+ (1,0) [0|4294967295] ""  Display_ID10
 SG_ Configure_Slaves46_1F25_2E m46 : 32|32@1+ (1,0) [0|4294967295] ""  Display_ID10
 SG_ Configure_Slaves45_1F25_2D m45 : 32|32@1+ (1,0) [0|4294967295] ""  Display_ID10
 SG_ Configure_Slaves44_1F25_2C m44 : 32|32@1+ (1,0) [0|4294967295] ""  Display_ID10
 SG_ Configure_Slaves43_1F25_2B m43 : 32|32@1+ (1,0) [0|4294967295] ""  Display_ID10
 SG_ Configure_Slaves42_1F25_2A m42 : 32|32@1+ (1,0) [0|4294967295] ""  Display_ID10
 SG_ Configure_Slaves41_1F25_29 m41 : 32|32@1+ (1,0) [0|4294967295] ""  Display_ID10
 SG_ Configure_Slaves40_1F25_28 m40 : 32|32@1+ (1,0) [0|4294967295] ""  Display_ID10
 SG_ Configure_Slaves39_1F25_27 m39 : 32|32@1+ (1,0) [0|4294967295] ""  Display_ID10
 SG_ Configure_Slaves38_1F25_26 m38 : 32|32@1+ (1,0) [0|4294967295] ""  Display_ID10
 SG_ Configure_Slaves37_1F25_25 m37 : 32|32@1+ (1,0) [0|4294967295] ""  Display_ID10
 SG_ Configure_Slaves36_1F25_24 m36 : 32|32@1+ (1,0) [0|4294967295] ""  Display_ID10
 SG_ Configure_Slaves35_1F25_23 m35 : 32|32@1+ (1,0) [0|4294967295] ""  Display_ID10
 SG_ Configure_Slaves34_1F25_22 m34 : 32|32@1+ (1,0) [0|4294967295] ""  Display_ID10
 SG_ Configure_Slaves33_1F25_21 m33 : 32|32@1+ (1,0) [0|4294967295] ""  Display_ID10
 SG_ Configure_Slaves32_1F25_20 m32 : 32|32@1+ (1,0) [0|4294967295] ""  Display_ID10
 SG_ Configure_Slaves31_1F25_1F m31 : 32|32@1+ (1,0) [0|4294967295] ""  Display_ID10
 SG_ Configure_Slaves30_1F25_1E m30 : 32|32@1+ (1,0) [0|4294967295] ""  Display_ID10
 SG_ Configure_Slaves29_1F25_1D m29 : 32|32@1+ (1,0) [0|4294967295] ""  Display_ID10
 SG_ Configure_Slaves28_1F25_1C m28 : 32|32@1+ (1,0) [0|4294967295] ""  Display_ID10
 SG_ Configure_Slaves27_1F25_1B m27 : 32|32@1+ (1,0) [0|4294967295] ""  Display_ID10
 SG_ Configure_Slaves26_1F25_1A m26 : 32|32@1+ (1,0) [0|4294967295] ""  Display_ID10
 SG_ Configure_Slaves25_1F25_19 m25 : 32|32@1+ (1,0) [0|4294967295] ""  Display_ID10
 SG_ Configure_Slaves24_1F25_18 m24 : 32|32@1+ (1,0) [0|4294967295] ""  Display_ID10
 SG_ Configure_Slaves23_1F25_17 m23 : 32|32@1+ (1,0) [0|4294967295] ""  Display_ID10
 SG_ Configure_Slaves22_1F25_16 m22 : 32|32@1+ (1,0) [0|4294967295] ""  Display_ID10
 SG_ Configure_Slaves21_1F25_15 m21 : 32|32@1+ (1,0) [0|4294967295] ""  Display_ID10
 SG_ Configure_Slaves20_1F25_14 m20 : 32|32@1+ (1,0) [0|4294967295] ""  Display_ID10
 SG_ Configure_Slaves19_1F25_13 m19 : 32|32@1+ (1,0) [0|4294967295] ""  Display_ID10
 SG_ Configure_Slaves18_1F25_12 m18 : 32|32@1+ (1,0) [0|4294967295] ""  Display_ID10
 SG_ Configure_Slaves17_1F25_11 m17 : 32|32@1+ (1,0) [0|4294967295] ""  Display_ID10
 SG_ Configure_Slaves16_1F25_10 m16 : 32|32@1+ (1,0) [0|4294967295] ""  Display_ID10
 SG_ Configure_Slaves15_1F25_0F m15 : 32|32@1+ (1,0) [0|4294967295] ""  Display_ID10
 SG_ Configure_Slaves14_1F25_0E m14 : 32|32@1+ (1,0) [0|4294967295] ""  Display_ID10
 SG_ Configure_Slaves13_1F25_0D m13 : 32|32@1+ (1,0) [0|4294967295] ""  Display_ID10
 SG_ Configure_Slaves12_1F25_0C m12 : 32|32@1+ (1,0) [0|4294967295] ""  Display_ID10
 SG_ Configure_Slaves11_1F25_0B m11 : 32|32@1+ (1,0) [0|4294967295] ""  Display_ID10
 SG_ Configure_Slaves10_1F25_0A m10 : 32|32@1+ (1,0) [0|4294967295] ""  Display_ID10
 SG_ Configure_Slaves9_1F25_09 m9 : 32|32@1+ (1,0) [0|4294967295] ""  Display_ID10
 SG_ Configure_Slaves8_1F25_08 m8 : 32|32@1+ (1,0) [0|4294967295] ""  Display_ID10
 SG_ Configure_Slaves7_1F25_07 m7 : 32|32@1+ (1,0) [0|4294967295] ""  Display_ID10
 SG_ Configure_Slaves6_1F25_06 m6 : 32|32@1+ (1,0) [0|4294967295] ""  Display_ID10
 SG_ Configure_Slaves5_1F25_05 m5 : 32|32@1+ (1,0) [0|4294967295] ""  Display_ID10
 SG_ Configure_Slaves4_1F25_04 m4 : 32|32@1+ (1,0) [0|4294967295] ""  Display_ID10
 SG_ Configure_Slaves3_1F25_03 m3 : 32|32@1+ (1,0) [0|4294967295] ""  Display_ID10
 SG_ Configure_Slaves2_1F25_02 m2 : 32|32@1+ (1,0) [0|4294967295] ""  Display_ID10
 SG_ Configure_Slaves1_1F25_01 m1 : 32|32@1+ (1,0) [0|4294967295] ""  Display_ID10
 SG_ NrOfObjects_1F25_00 m0 : 32|8@1+ (1,0) [0|255] ""  Display_ID10
 SG_ SubIndex_1F25 m7973M : 24|8@1+ (1,0) [0|128] ""  Display_ID10
 SG_ NrOfObjects_1F22_00 m0 : 32|8@1+ (1,0) [0|255] ""  Display_ID10
 SG_ SubIndex_1F22 m7970M : 24|8@1+ (1,0) [0|127] ""  Display_ID10
 SG_ Safety_configuration_checks_0001 m3 : 32|32@1+ (1,0) [0|4294967295] ""  Display_ID10
 SG_ Safety_configuration_checks_0002 m2 : 32|32@1+ (1,0) [0|4294967295] ""  Display_ID10
 SG_ Safety_Checksum_13FF_01 m1 : 32|16@1+ (1,0) [0|65535] ""  Display_ID10
 SG_ Safety_checksum_Number_of_e_0006 m0 : 32|8@1+ (1,0) [0|255] ""  Display_ID10
 SG_ SubIndex_13FF m5119M : 24|8@1+ (1,0) [0|3] ""  Display_ID10
 SG_ Configuration_valid_13FE m0 : 32|8@1+ (1,0) [0|255] ""  Display_ID10
 SG_ SubIndex_13FE m5118M : 24|8@1+ (1,0) [0|0] ""  Display_ID10
 SG_ SRDO3_mapping_inv_Byte1_1383_02 m2 : 32|32@1+ (1,0) [0|4294967295] ""  Display_ID10
 SG_ SRDO3_mapping_Byte1_1383_01 m1 : 32|32@1+ (1,0) [0|4294967295] ""  Display_ID10
 SG_ SRDO3_Number_of_mapped_obje_0000 m0 : 32|8@1+ (1,0) [0|255] ""  Display_ID10
 SG_ SubIndex_1383 m4995M : 24|8@1+ (1,0) [0|2] ""  Display_ID10
 SG_ SRDO2_mapping_inv_Byte1_1382_02 m2 : 32|32@1+ (1,0) [0|4294967295] ""  Display_ID10
 SG_ SRDO2_mapping_Byte1_1382_01 m1 : 32|32@1+ (1,0) [0|4294967295] ""  Display_ID10
 SG_ SRDO2_Number_of_mapped_obje_0000 m0 : 32|8@1+ (1,0) [0|255] ""  Display_ID10
 SG_ SubIndex_1382 m4994M : 24|8@1+ (1,0) [0|2] ""  Display_ID10
 SG_ SRDO1_mapping_inv_Byte1_1381_02 m2 : 32|32@1+ (1,0) [0|4294967295] ""  Display_ID10
 SG_ SRDO1_mapping_Byte1_1381_01 m1 : 32|32@1+ (1,0) [0|4294967295] ""  Display_ID10
 SG_ SRDO1_Number_of_mapped_obje_0006 m0 : 32|8@1+ (1,0) [0|255] ""  Display_ID10
 SG_ SubIndex_1381 m4993M : 24|8@1+ (1,0) [0|2] ""  Display_ID10
 SG_ SRDO3_communication_par_COB_0000 m6 : 32|32@1+ (1,0) [0|4294967295] ""  Display_ID10
 SG_ SRDO3_communication_par_COB_0001 m5 : 32|32@1+ (1,0) [0|4294967295] ""  Display_ID10
 SG_ SRDO3_communication_par_Tra_0000 m4 : 32|8@1+ (1,0) [254|254] ""  Display_ID10
 SG_ SRDO3_communication_srvt_ti_0000 m3 : 32|8@1+ (1,0) [0|255] ""  Display_ID10
 SG_ SRDO3_communication_par_sct_0000 m2 : 32|16@1+ (1,0) [10|65535] ""  Display_ID10
 SG_ SRDO3_communication_par_Inf_0000 m1 : 32|8@1+ (1,0) [0|2] ""  Display_ID10
 SG_ Highest_sub_index_supported_0031 m0 : 32|8@1+ (1,0) [0|255] ""  Display_ID10
 SG_ SubIndex_1303 m4867M : 24|8@1+ (1,0) [0|6] ""  Display_ID10
 SG_ SRDO2_communication_par_COB_0000 m6 : 32|32@1+ (1,0) [0|4294967295] ""  Display_ID10
 SG_ SRDO2_communication_par_COB_0001 m5 : 32|32@1+ (1,0) [0|4294967295] ""  Display_ID10
 SG_ SRDO2_communication_par_Tra_0000 m4 : 32|8@1+ (1,0) [254|254] ""  Display_ID10
 SG_ SRDO2_communication_srvt_ti_0000 m3 : 32|8@1+ (1,0) [0|255] ""  Display_ID10
 SG_ SRDO2_communication_par_sct_0000 m2 : 32|16@1+ (1,0) [10|65535] ""  Display_ID10
 SG_ SRDO2_communication_par_Inf_0000 m1 : 32|8@1+ (1,0) [0|2] ""  Display_ID10
 SG_ Highest_sub_index_supported_0032 m0 : 32|8@1+ (1,0) [0|255] ""  Display_ID10
 SG_ SubIndex_1302 m4866M : 24|8@1+ (1,0) [0|6] ""  Display_ID10
 SG_ SRDO1_communication_par_COB_0012 m6 : 32|32@1+ (1,0) [0|4294967295] ""  Display_ID10
 SG_ SRDO1_communication_par_COB_0013 m5 : 32|32@1+ (1,0) [0|4294967295] ""  Display_ID10
 SG_ SRDO1_communication_par_Tra_0006 m4 : 32|8@1+ (1,0) [254|254] ""  Display_ID10
 SG_ SRDO1_communication_srvt_ti_0000 m3 : 32|8@1+ (1,0) [0|255] ""  Display_ID10
 SG_ SRDO1_communication_par_sct_0000 m2 : 32|16@1+ (1,0) [10|65535] ""  Display_ID10
 SG_ SRDO1_communication_par_Inf_0006 m1 : 32|8@1+ (1,0) [0|2] ""  Display_ID10
 SG_ Highest_sub_index_supported_0033 m0 : 32|8@1+ (1,0) [0|255] ""  Display_ID10
 SG_ SubIndex_1301 m4865M : 24|8@1+ (1,0) [0|6] ""  Display_ID10
 SG_ Serial_number_1018_04 m4 : 32|32@1+ (1,0) [0|4294967295] ""  Display_ID10
 SG_ Revision_number_1018_03 m3 : 32|32@1+ (1,0) [0|4294967295] ""  Display_ID10
 SG_ Product_Code_1018_02 m2 : 32|32@1+ (1,0) [0|4294967295] ""  Display_ID10
 SG_ Vendor_Id_1018_01 m1 : 32|32@1+ (1,0) [0|4294967295] ""  Display_ID10
 SG_ Highest_sub_index_supported_0034 m0 : 32|8@1+ (1,0) [1|4] ""  Display_ID10
 SG_ SubIndex_1018 m4120M : 24|8@1+ (1,0) [0|4] ""  Display_ID10
 SG_ Producer_Heartbeat_Time_1017 m0 : 32|16@1+ (1,0) [0|65535] ""  Display_ID10
 SG_ SubIndex_1017 m4119M : 24|8@1+ (1,0) [0|0] ""  Display_ID10
 SG_ Consumer_Heartbeat_Time127__0000 m127 : 32|32@1+ (1,0) [0|4294967295] ""  Display_ID10
 SG_ Consumer_Heartbeat_Time126__0000 m126 : 32|32@1+ (1,0) [0|4294967295] ""  Display_ID10
 SG_ Consumer_Heartbeat_Time125__0000 m125 : 32|32@1+ (1,0) [0|4294967295] ""  Display_ID10
 SG_ Consumer_Heartbeat_Time124__0000 m124 : 32|32@1+ (1,0) [0|4294967295] ""  Display_ID10
 SG_ Consumer_Heartbeat_Time123__0000 m123 : 32|32@1+ (1,0) [0|4294967295] ""  Display_ID10
 SG_ Consumer_Heartbeat_Time122__0000 m122 : 32|32@1+ (1,0) [0|4294967295] ""  Display_ID10
 SG_ Consumer_Heartbeat_Time121__0000 m121 : 32|32@1+ (1,0) [0|4294967295] ""  Display_ID10
 SG_ Consumer_Heartbeat_Time120__0000 m120 : 32|32@1+ (1,0) [0|4294967295] ""  Display_ID10
 SG_ Consumer_Heartbeat_Time119__0000 m119 : 32|32@1+ (1,0) [0|4294967295] ""  Display_ID10
 SG_ Consumer_Heartbeat_Time118__0000 m118 : 32|32@1+ (1,0) [0|4294967295] ""  Display_ID10
 SG_ Consumer_Heartbeat_Time117__0000 m117 : 32|32@1+ (1,0) [0|4294967295] ""  Display_ID10
 SG_ Consumer_Heartbeat_Time116__0000 m116 : 32|32@1+ (1,0) [0|4294967295] ""  Display_ID10
 SG_ Consumer_Heartbeat_Time115__0000 m115 : 32|32@1+ (1,0) [0|4294967295] ""  Display_ID10
 SG_ Consumer_Heartbeat_Time114__0000 m114 : 32|32@1+ (1,0) [0|4294967295] ""  Display_ID10
 SG_ Consumer_Heartbeat_Time113__0000 m113 : 32|32@1+ (1,0) [0|4294967295] ""  Display_ID10
 SG_ Consumer_Heartbeat_Time112__0000 m112 : 32|32@1+ (1,0) [0|4294967295] ""  Display_ID10
 SG_ Consumer_Heartbeat_Time111__0000 m111 : 32|32@1+ (1,0) [0|4294967295] ""  Display_ID10
 SG_ Consumer_Heartbeat_Time110__0000 m110 : 32|32@1+ (1,0) [0|4294967295] ""  Display_ID10
 SG_ Consumer_Heartbeat_Time109__0000 m109 : 32|32@1+ (1,0) [0|4294967295] ""  Display_ID10
 SG_ Consumer_Heartbeat_Time108__0000 m108 : 32|32@1+ (1,0) [0|4294967295] ""  Display_ID10
 SG_ Consumer_Heartbeat_Time107__0000 m107 : 32|32@1+ (1,0) [0|4294967295] ""  Display_ID10
 SG_ Consumer_Heartbeat_Time106__0000 m106 : 32|32@1+ (1,0) [0|4294967295] ""  Display_ID10
 SG_ Consumer_Heartbeat_Time105__0000 m105 : 32|32@1+ (1,0) [0|4294967295] ""  Display_ID10
 SG_ Consumer_Heartbeat_Time104__0000 m104 : 32|32@1+ (1,0) [0|4294967295] ""  Display_ID10
 SG_ Consumer_Heartbeat_Time103__0000 m103 : 32|32@1+ (1,0) [0|4294967295] ""  Display_ID10
 SG_ Consumer_Heartbeat_Time102__0000 m102 : 32|32@1+ (1,0) [0|4294967295] ""  Display_ID10
 SG_ Consumer_Heartbeat_Time101__0000 m101 : 32|32@1+ (1,0) [0|4294967295] ""  Display_ID10
 SG_ Consumer_Heartbeat_Time100__0000 m100 : 32|32@1+ (1,0) [0|4294967295] ""  Display_ID10
 SG_ Consumer_Heartbeat_Time99_1_0000 m99 : 32|32@1+ (1,0) [0|4294967295] ""  Display_ID10
 SG_ Consumer_Heartbeat_Time98_1_0000 m98 : 32|32@1+ (1,0) [0|4294967295] ""  Display_ID10
 SG_ Consumer_Heartbeat_Time97_1_0000 m97 : 32|32@1+ (1,0) [0|4294967295] ""  Display_ID10
 SG_ Consumer_Heartbeat_Time96_1_0000 m96 : 32|32@1+ (1,0) [0|4294967295] ""  Display_ID10
 SG_ Consumer_Heartbeat_Time95_1_0000 m95 : 32|32@1+ (1,0) [0|4294967295] ""  Display_ID10
 SG_ Consumer_Heartbeat_Time94_1_0000 m94 : 32|32@1+ (1,0) [0|4294967295] ""  Display_ID10
 SG_ Consumer_Heartbeat_Time93_1_0000 m93 : 32|32@1+ (1,0) [0|4294967295] ""  Display_ID10
 SG_ Consumer_Heartbeat_Time92_1_0000 m92 : 32|32@1+ (1,0) [0|4294967295] ""  Display_ID10
 SG_ Consumer_Heartbeat_Time91_1_0000 m91 : 32|32@1+ (1,0) [0|4294967295] ""  Display_ID10
 SG_ Consumer_Heartbeat_Time90_1_0000 m90 : 32|32@1+ (1,0) [0|4294967295] ""  Display_ID10
 SG_ Consumer_Heartbeat_Time89_1_0000 m89 : 32|32@1+ (1,0) [0|4294967295] ""  Display_ID10
 SG_ Consumer_Heartbeat_Time88_1_0000 m88 : 32|32@1+ (1,0) [0|4294967295] ""  Display_ID10
 SG_ Consumer_Heartbeat_Time87_1_0000 m87 : 32|32@1+ (1,0) [0|4294967295] ""  Display_ID10
 SG_ Consumer_Heartbeat_Time86_1_0000 m86 : 32|32@1+ (1,0) [0|4294967295] ""  Display_ID10
 SG_ Consumer_Heartbeat_Time85_1_0000 m85 : 32|32@1+ (1,0) [0|4294967295] ""  Display_ID10
 SG_ Consumer_Heartbeat_Time84_1_0000 m84 : 32|32@1+ (1,0) [0|4294967295] ""  Display_ID10
 SG_ Consumer_Heartbeat_Time83_1_0000 m83 : 32|32@1+ (1,0) [0|4294967295] ""  Display_ID10
 SG_ Consumer_Heartbeat_Time82_1_0000 m82 : 32|32@1+ (1,0) [0|4294967295] ""  Display_ID10
 SG_ Consumer_Heartbeat_Time81_1_0000 m81 : 32|32@1+ (1,0) [0|4294967295] ""  Display_ID10
 SG_ Consumer_Heartbeat_Time80_1_0000 m80 : 32|32@1+ (1,0) [0|4294967295] ""  Display_ID10
 SG_ Consumer_Heartbeat_Time79_1_0000 m79 : 32|32@1+ (1,0) [0|4294967295] ""  Display_ID10
 SG_ Consumer_Heartbeat_Time78_1_0000 m78 : 32|32@1+ (1,0) [0|4294967295] ""  Display_ID10
 SG_ Consumer_Heartbeat_Time77_1_0000 m77 : 32|32@1+ (1,0) [0|4294967295] ""  Display_ID10
 SG_ Consumer_Heartbeat_Time76_1_0000 m76 : 32|32@1+ (1,0) [0|4294967295] ""  Display_ID10
 SG_ Consumer_Heartbeat_Time75_1_0000 m75 : 32|32@1+ (1,0) [0|4294967295] ""  Display_ID10
 SG_ Consumer_Heartbeat_Time74_1_0000 m74 : 32|32@1+ (1,0) [0|4294967295] ""  Display_ID10
 SG_ Consumer_Heartbeat_Time73_1_0000 m73 : 32|32@1+ (1,0) [0|4294967295] ""  Display_ID10
 SG_ Consumer_Heartbeat_Time72_1_0000 m72 : 32|32@1+ (1,0) [0|4294967295] ""  Display_ID10
 SG_ Consumer_Heartbeat_Time71_1_0000 m71 : 32|32@1+ (1,0) [0|4294967295] ""  Display_ID10
 SG_ Consumer_Heartbeat_Time70_1_0000 m70 : 32|32@1+ (1,0) [0|4294967295] ""  Display_ID10
 SG_ Consumer_Heartbeat_Time69_1_0000 m69 : 32|32@1+ (1,0) [0|4294967295] ""  Display_ID10
 SG_ Consumer_Heartbeat_Time68_1_0000 m68 : 32|32@1+ (1,0) [0|4294967295] ""  Display_ID10
 SG_ Consumer_Heartbeat_Time67_1_0000 m67 : 32|32@1+ (1,0) [0|4294967295] ""  Display_ID10
 SG_ Consumer_Heartbeat_Time66_1_0000 m66 : 32|32@1+ (1,0) [0|4294967295] ""  Display_ID10
 SG_ Consumer_Heartbeat_Time65_1_0000 m65 : 32|32@1+ (1,0) [0|4294967295] ""  Display_ID10
 SG_ Consumer_Heartbeat_Time64_1_0000 m64 : 32|32@1+ (1,0) [0|4294967295] ""  Display_ID10
 SG_ Consumer_Heartbeat_Time63_1_0000 m63 : 32|32@1+ (1,0) [0|4294967295] ""  Display_ID10
 SG_ Consumer_Heartbeat_Time62_1_0000 m62 : 32|32@1+ (1,0) [0|4294967295] ""  Display_ID10
 SG_ Consumer_Heartbeat_Time61_1_0000 m61 : 32|32@1+ (1,0) [0|4294967295] ""  Display_ID10
 SG_ Consumer_Heartbeat_Time60_1_0000 m60 : 32|32@1+ (1,0) [0|4294967295] ""  Display_ID10
 SG_ Consumer_Heartbeat_Time59_1_0000 m59 : 32|32@1+ (1,0) [0|4294967295] ""  Display_ID10
 SG_ Consumer_Heartbeat_Time58_1_0000 m58 : 32|32@1+ (1,0) [0|4294967295] ""  Display_ID10
 SG_ Consumer_Heartbeat_Time57_1_0000 m57 : 32|32@1+ (1,0) [0|4294967295] ""  Display_ID10
 SG_ Consumer_Heartbeat_Time56_1_0000 m56 : 32|32@1+ (1,0) [0|4294967295] ""  Display_ID10
 SG_ Consumer_Heartbeat_Time55_1_0000 m55 : 32|32@1+ (1,0) [0|4294967295] ""  Display_ID10
 SG_ Consumer_Heartbeat_Time54_1_0000 m54 : 32|32@1+ (1,0) [0|4294967295] ""  Display_ID10
 SG_ Consumer_Heartbeat_Time53_1_0000 m53 : 32|32@1+ (1,0) [0|4294967295] ""  Display_ID10
 SG_ Consumer_Heartbeat_Time52_1_0000 m52 : 32|32@1+ (1,0) [0|4294967295] ""  Display_ID10
 SG_ Consumer_Heartbeat_Time51_1_0000 m51 : 32|32@1+ (1,0) [0|4294967295] ""  Display_ID10
 SG_ Consumer_Heartbeat_Time50_1_0000 m50 : 32|32@1+ (1,0) [0|4294967295] ""  Display_ID10
 SG_ Consumer_Heartbeat_Time49_1_0000 m49 : 32|32@1+ (1,0) [0|4294967295] ""  Display_ID10
 SG_ Consumer_Heartbeat_Time48_1_0000 m48 : 32|32@1+ (1,0) [0|4294967295] ""  Display_ID10
 SG_ Consumer_Heartbeat_Time47_1_0000 m47 : 32|32@1+ (1,0) [0|4294967295] ""  Display_ID10
 SG_ Consumer_Heartbeat_Time46_1_0000 m46 : 32|32@1+ (1,0) [0|4294967295] ""  Display_ID10
 SG_ Consumer_Heartbeat_Time45_1_0000 m45 : 32|32@1+ (1,0) [0|4294967295] ""  Display_ID10
 SG_ Consumer_Heartbeat_Time44_1_0000 m44 : 32|32@1+ (1,0) [0|4294967295] ""  Display_ID10
 SG_ Consumer_Heartbeat_Time43_1_0000 m43 : 32|32@1+ (1,0) [0|4294967295] ""  Display_ID10
 SG_ Consumer_Heartbeat_Time42_1_0000 m42 : 32|32@1+ (1,0) [0|4294967295] ""  Display_ID10
 SG_ Consumer_Heartbeat_Time41_1_0000 m41 : 32|32@1+ (1,0) [0|4294967295] ""  Display_ID10
 SG_ Consumer_Heartbeat_Time40_1_0000 m40 : 32|32@1+ (1,0) [0|4294967295] ""  Display_ID10
 SG_ Consumer_Heartbeat_Time39_1_0000 m39 : 32|32@1+ (1,0) [0|4294967295] ""  Display_ID10
 SG_ Consumer_Heartbeat_Time38_1_0000 m38 : 32|32@1+ (1,0) [0|4294967295] ""  Display_ID10
 SG_ Consumer_Heartbeat_Time37_1_0000 m37 : 32|32@1+ (1,0) [0|4294967295] ""  Display_ID10
 SG_ Consumer_Heartbeat_Time36_1_0000 m36 : 32|32@1+ (1,0) [0|4294967295] ""  Display_ID10
 SG_ Consumer_Heartbeat_Time35_1_0000 m35 : 32|32@1+ (1,0) [0|4294967295] ""  Display_ID10
 SG_ Consumer_Heartbeat_Time34_1_0000 m34 : 32|32@1+ (1,0) [0|4294967295] ""  Display_ID10
 SG_ Consumer_Heartbeat_Time33_1_0000 m33 : 32|32@1+ (1,0) [0|4294967295] ""  Display_ID10
 SG_ Consumer_Heartbeat_Time32_1_0000 m32 : 32|32@1+ (1,0) [0|4294967295] ""  Display_ID10
 SG_ Consumer_Heartbeat_Time31_1_0000 m31 : 32|32@1+ (1,0) [0|4294967295] ""  Display_ID10
 SG_ Consumer_Heartbeat_Time30_1_0000 m30 : 32|32@1+ (1,0) [0|4294967295] ""  Display_ID10
 SG_ Consumer_Heartbeat_Time29_1_0000 m29 : 32|32@1+ (1,0) [0|4294967295] ""  Display_ID10
 SG_ Consumer_Heartbeat_Time28_1_0000 m28 : 32|32@1+ (1,0) [0|4294967295] ""  Display_ID10
 SG_ Consumer_Heartbeat_Time27_1_0000 m27 : 32|32@1+ (1,0) [0|4294967295] ""  Display_ID10
 SG_ Consumer_Heartbeat_Time26_1_0000 m26 : 32|32@1+ (1,0) [0|4294967295] ""  Display_ID10
 SG_ Consumer_Heartbeat_Time25_1_0000 m25 : 32|32@1+ (1,0) [0|4294967295] ""  Display_ID10
 SG_ Consumer_Heartbeat_Time24_1_0000 m24 : 32|32@1+ (1,0) [0|4294967295] ""  Display_ID10
 SG_ Consumer_Heartbeat_Time23_1_0000 m23 : 32|32@1+ (1,0) [0|4294967295] ""  Display_ID10
 SG_ Consumer_Heartbeat_Time22_1_0000 m22 : 32|32@1+ (1,0) [0|4294967295] ""  Display_ID10
 SG_ Consumer_Heartbeat_Time21_1_0000 m21 : 32|32@1+ (1,0) [0|4294967295] ""  Display_ID10
 SG_ Consumer_Heartbeat_Time20_1_0000 m20 : 32|32@1+ (1,0) [0|4294967295] ""  Display_ID10
 SG_ Consumer_Heartbeat_Time19_1_0000 m19 : 32|32@1+ (1,0) [0|4294967295] ""  Display_ID10
 SG_ Consumer_Heartbeat_Time18_1_0000 m18 : 32|32@1+ (1,0) [0|4294967295] ""  Display_ID10
 SG_ Consumer_Heartbeat_Time17_1_0000 m17 : 32|32@1+ (1,0) [0|4294967295] ""  Display_ID10
 SG_ Consumer_Heartbeat_Time16_1_0006 m16 : 32|32@1+ (1,0) [0|4294967295] ""  Display_ID10
 SG_ Consumer_Heartbeat_Time15_1_0006 m15 : 32|32@1+ (1,0) [0|4294967295] ""  Display_ID10
 SG_ Consumer_Heartbeat_Time14_1_0006 m14 : 32|32@1+ (1,0) [0|4294967295] ""  Display_ID10
 SG_ Consumer_Heartbeat_Time13_1_0006 m13 : 32|32@1+ (1,0) [0|4294967295] ""  Display_ID10
 SG_ Consumer_Heartbeat_Time12_1_0006 m12 : 32|32@1+ (1,0) [0|4294967295] ""  Display_ID10
 SG_ Consumer_Heartbeat_Time11_1_0006 m11 : 32|32@1+ (1,0) [0|4294967295] ""  Display_ID10
 SG_ Consumer_Heartbeat_Time10_1_0006 m10 : 32|32@1+ (1,0) [0|4294967295] ""  Display_ID10
 SG_ Consumer_Heartbeat_Time9_1016_09 m9 : 32|32@1+ (1,0) [0|4294967295] ""  Display_ID10
 SG_ Consumer_Heartbeat_Time8_1016_08 m8 : 32|32@1+ (1,0) [0|4294967295] ""  Display_ID10
 SG_ Consumer_Heartbeat_Time7_1016_07 m7 : 32|32@1+ (1,0) [0|4294967295] ""  Display_ID10
 SG_ Consumer_Heartbeat_Time6_1016_06 m6 : 32|32@1+ (1,0) [0|4294967295] ""  Display_ID10
 SG_ Consumer_Heartbeat_Time5_1016_05 m5 : 32|32@1+ (1,0) [0|4294967295] ""  Display_ID10
 SG_ Consumer_Heartbeat_Time4_1016_04 m4 : 32|32@1+ (1,0) [0|4294967295] ""  Display_ID10
 SG_ Consumer_Heartbeat_Time3_1016_03 m3 : 32|32@1+ (1,0) [0|4294967295] ""  Display_ID10
 SG_ Consumer_Heartbeat_Time2_1016_02 m2 : 32|32@1+ (1,0) [0|4294967295] ""  Display_ID10
 SG_ Consumer_Heartbeat_Time1_1016_01 m1 : 32|32@1+ (1,0) [0|4294967295] ""  Display_ID10
 SG_ NrOfObjects_1016_00 m0 : 32|8@1+ (1,0) [0|255] ""  Display_ID10
 SG_ SubIndex_1016 m4118M : 24|8@1+ (1,0) [0|127] ""  Display_ID10
 SG_ Restore_all_Default_Paramet_0006 m1 : 32|32@1+ (1,0) [0|4294967295] ""  Display_ID10
 SG_ Highest_sub_index_supported_0035 m0 : 32|8@1+ (1,0) [0|255] ""  Display_ID10
 SG_ SubIndex_1011 m4113M : 24|8@1+ (1,0) [0|1] ""  Display_ID10
 SG_ Save_all_Parameters_1010_01 m1 : 32|32@1+ (1,0) [0|4294967295] ""  Display_ID10
 SG_ Highest_sub_index_supported_0036 m0 : 32|8@1+ (1,0) [0|255] ""  Display_ID10
 SG_ SubIndex_1010 m4112M : 24|8@1+ (1,0) [0|1] ""  Display_ID10
 SG_ Life_Time_Factor_100D m0 : 32|8@1+ (1,0) [0|255] ""  Display_ID10
 SG_ SubIndex_100D m4109M : 24|8@1+ (1,0) [0|0] ""  Display_ID10
 SG_ Guard_Time_100C m0 : 32|16@1+ (1,0) [0|65535] ""  Display_ID10
 SG_ SubIndex_100C m4108M : 24|8@1+ (1,0) [0|0] ""  Display_ID10
 SG_ Sync_Window_Length_1007 m0 : 32|32@1+ (1,0) [0|4294967295] ""  Display_ID10
 SG_ SubIndex_1007 m4103M : 24|8@1+ (1,0) [0|0] ""  Display_ID10
 SG_ Communication_Cycle_Period_1006 m0 : 32|32@1+ (1,0) [0|4294967295] ""  Display_ID10
 SG_ SubIndex_1006 m4102M : 24|8@1+ (1,0) [0|0] ""  Display_ID10
 SG_ COB_ID_SYNC_1005 m0 : 32|32@1+ (1,0) [128|4294967295] ""  Display_ID10
 SG_ SubIndex_1005 m4101M : 24|8@1+ (1,0) [0|0] ""  Display_ID10
 SG_ Standard_error_field_1003_10 m16 : 32|32@1+ (1,0) [0|4294967295] ""  Display_ID10
 SG_ Standard_error_field_1003_0F m15 : 32|32@1+ (1,0) [0|4294967295] ""  Display_ID10
 SG_ Standard_error_field_1003_0E m14 : 32|32@1+ (1,0) [0|4294967295] ""  Display_ID10
 SG_ Standard_error_field_1003_0D m13 : 32|32@1+ (1,0) [0|4294967295] ""  Display_ID10
 SG_ Standard_error_field_1003_0C m12 : 32|32@1+ (1,0) [0|4294967295] ""  Display_ID10
 SG_ Standard_error_field_1003_0B m11 : 32|32@1+ (1,0) [0|4294967295] ""  Display_ID10
 SG_ Standard_error_field_1003_0A m10 : 32|32@1+ (1,0) [0|4294967295] ""  Display_ID10
 SG_ Standard_error_field_1003_09 m9 : 32|32@1+ (1,0) [0|4294967295] ""  Display_ID10
 SG_ Standard_error_field_1003_08 m8 : 32|32@1+ (1,0) [0|4294967295] ""  Display_ID10
 SG_ Standard_error_field_1003_07 m7 : 32|32@1+ (1,0) [0|4294967295] ""  Display_ID10
 SG_ Standard_error_field_1003_06 m6 : 32|32@1+ (1,0) [0|4294967295] ""  Display_ID10
 SG_ Standard_error_field_1003_05 m5 : 32|32@1+ (1,0) [0|4294967295] ""  Display_ID10
 SG_ Standard_error_field_1003_04 m4 : 32|32@1+ (1,0) [0|4294967295] ""  Display_ID10
 SG_ Standard_error_field_1003_03 m3 : 32|32@1+ (1,0) [0|4294967295] ""  Display_ID10
 SG_ Standard_error_field_1003_02 m2 : 32|32@1+ (1,0) [0|4294967295] ""  Display_ID10
 SG_ Standard_error_field_1003_01 m1 : 32|32@1+ (1,0) [0|4294967295] ""  Display_ID10
 SG_ Number_of_Errors_1003_00 m0 : 32|8@1+ (1,0) [0|255] ""  Display_ID10
 SG_ SubIndex_1003 m4099M : 24|8@1+ (1,0) [0|16] ""  Display_ID10
 SG_ Error_Register_1001 m0 : 32|8@1+ (1,0) [0|255] ""  Display_ID10
 SG_ SubIndex_1001 m4097M : 24|8@1+ (1,0) [0|0] ""  Display_ID10
 SG_ Device_Type_1000 m0 : 32|32@1+ (1,0) [0|4294967295] ""  Display_ID10
 SG_ SubIndex_1000 m4096M : 24|8@1+ (1,0) [0|0] ""  Display_ID10
 SG_ Index m1M : 8|16@1+ (1,0) [4096|42563] ""  Display_ID10
 SG_ TransferType m1M : 1|1@1+ (1,0) [0|1] ""  Display_ID10
 SG_ NotUsedBytes m1 : 2|2@1+ (1,0) [0|3] ""  Display_ID10
 SG_ SizeIndicator m1 : 0|1@1+ (1,0) [0|1] ""  Display_ID10
 SG_ CCS M : 5|3@1+ (1,0) [0|6] ""  Display_ID10

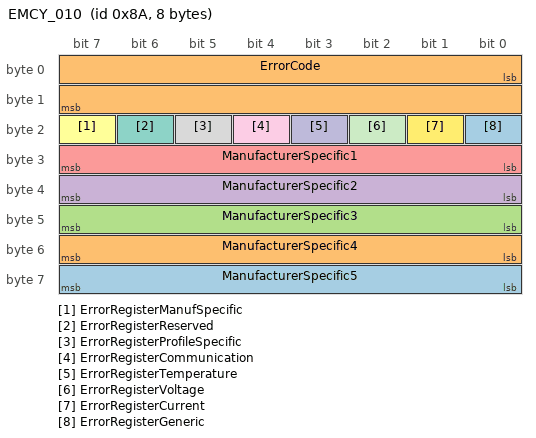
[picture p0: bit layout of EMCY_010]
BO_ 138 EMCY_010: 8 Display_ID10
 SG_ ManufacturerSpecific5 : 56|8@1+ (1,0) [0|0] "" Vector__XXX
 SG_ ManufacturerSpecific4 : 48|8@1+ (1,0) [0|0] "" Vector__XXX
 SG_ ManufacturerSpecific3 : 40|8@1+ (1,0) [0|0] "" Vector__XXX
 SG_ ManufacturerSpecific2 : 32|8@1+ (1,0) [0|0] "" Vector__XXX
 SG_ ManufacturerSpecific1 : 24|8@1+ (1,0) [0|0] "" Vector__XXX
 SG_ ErrorRegisterManufSpecific : 23|1@1+ (1,0) [0|0] "" Vector__XXX
 SG_ ErrorRegisterReserved : 22|1@1+ (1,0) [0|0] "" Vector__XXX
 SG_ ErrorRegisterProfileSpecific : 21|1@1+ (1,0) [0|0] "" Vector__XXX
 SG_ ErrorRegisterCommunication : 20|1@1+ (1,0) [0|0] "" Vector__XXX
 SG_ ErrorRegisterTemperature : 19|1@1+ (1,0) [0|0] "" Vector__XXX
 SG_ ErrorRegisterVoltage : 18|1@1+ (1,0) [0|0] "" Vector__XXX
 SG_ ErrorRegisterCurrent : 17|1@1+ (1,0) [0|0] "" Vector__XXX
 SG_ ErrorRegisterGeneric : 16|1@1+ (1,0) [0|0] "" Vector__XXX
 SG_ ErrorCode : 0|16@1+ (1,0) [0|0] "" Vector__XXX

BO_ 127 RED_IndicateActiveCANLine: 0 Vector__XXX

BO_ 118 FM_ForceReset: 0 Vector__XXX

BO_ 117 FM_ReqMasterCapable: 0 Vector__XXX

BO_ 116 FM_RspMasterCapable: 0 Vector__XXX

BO_ 115 FM_ReqPrioLevel: 0 Vector__XXX

BO_ 114 FM_TriggerTimeSlot: 0 Vector__XXX

BO_ 113 FM_MasterPrioLevel: 2 Vector__XXX
 SG_ FM_NodeID : 8|8@1+ (1,0) [0|0] "" Vector__XXX
 SG_ FM_PrioLevel : 0|8@1+ (1,0) [0|0] "" Vector__XXX

BO_ 256 TIME: 6 Vector__XXX
 SG_ days : 32|16@1+ (1,0) [0|65535] "days" Vector__XXX
 SG_ ms : 0|28@1+ (1,0) [0|86399999] "ms" Vector__XXX

BO_ 0 NMTZeroMsg: 2 VirtualNMTMaster
 SG_ Node_ID : 8|8@1+ (1,0) [0|0] "" Vector__XXX
 SG_ CS : 0|8@1+ (1,0) [0|0] "" Vector__XXX

BO_ 1760 DynSDOReq: 0 Vector__XXX

BO_ 2021 LSS_M: 8 Vector__XXX
 SG_ LSS_ID_Number m81 : 8|32@1+ (1,0) [0|0] "" Vector__XXX
 SG_ LSS_BitCheck m81 : 40|8@1+ (1,0) [0|0] "" Vector__XXX
 SG_ LSS_Sub m81 : 48|8@1+ (1,0) [0|0] "" Vector__XXX
 SG_ LSS_Next m81 : 56|8@1+ (1,0) [0|0] "" Vector__XXX
 SG_ LSS_SwitchDelay m21 : 8|16@1+ (1,0) [0|0] "" Vector__XXX
 SG_ LSS_CfgNodeID m17 : 8|8@1+ (1,0) [0|0] "" Vector__XXX
 SG_ LSS_IdentSerialHigh m75 : 8|32@1+ (1,0) [0|0] "" Vector__XXX
 SG_ LSS_IdentSerialLow m74 : 8|32@1+ (1,0) [0|0] "" Vector__XXX
 SG_ LSS_IdentRevisionHigh m73 : 8|32@1+ (1,0) [0|0] "" Vector__XXX
 SG_ LSS_IdentRevisionLow m72 : 8|32@1+ (1,0) [0|0] "" Vector__XXX
 SG_ LSS_IdentProductCode m71 : 8|32@1+ (1,0) [0|0] "" Vector__XXX
 SG_ LSS_IdentVendorId m70 : 8|32@1+ (1,0) [0|0] "" Vector__XXX
 SG_ LSS_TableIndex m19 : 16|8@1+ (1,0) [0|0] "" Vector__XXX
 SG_ LSS_TableSelector m19 : 8|8@1+ (1,0) [0|0] "" Vector__XXX
 SG_ LSS_SwitchSerial m67 : 8|32@1+ (1,0) [0|0] "" Vector__XXX
 SG_ LSS_SwitchRevision m66 : 8|32@1+ (1,0) [0|0] "" Vector__XXX
 SG_ LSS_SwitchProductCode m65 : 8|32@1+ (1,0) [0|0] "" Vector__XXX
 SG_ LSS_SwitchVendorId m64 : 8|32@1+ (1,0) [0|0] "" Vector__XXX
 SG_ LSS_Mode m4 : 8|8@1+ (1,0) [0|0] "" Vector__XXX
 SG_ LSS_M_CS M : 0|8@1+ (1,0) [0|0] "" Vector__XXX

BO_ 2020 LSS_S: 8 Vector__XXX
 SG_ LSS_NodeId m94 : 8|8@1+ (1,0) [0|0] "" Vector__XXX
 SG_ LSS_Serial m93 : 8|32@1+ (1,0) [0|0] "" Vector__XXX
 SG_ LSS_Revision m92 : 8|32@1+ (1,0) [0|0] "" Vector__XXX
 SG_ LSS_ProductId m91 : 8|32@1+ (1,0) [0|0] "" Vector__XXX
 SG_ LSS_VendorId m90 : 8|32@1+ (1,0) [0|0] "" Vector__XXX
 SG_ LSS_StoreCfg_SpecErr m23 : 16|8@1+ (1,0) [0|0] "" Vector__XXX
 SG_ LSS_StoreCfg_ErrCode m23 : 8|8@1+ (1,0) [0|0] "" Vector__XXX
 SG_ LSS_CfgBitTim_SpecErr m19 : 16|8@1+ (1,0) [0|0] "" Vector__XXX
 SG_ LSS_CfgBitTim_ErrCode m19 : 8|8@1+ (1,0) [0|0] "" Vector__XXX
 SG_ LSS_CfgNodeID_SpecErr m17 : 16|8@1+ (1,0) [0|0] "" Vector__XXX
 SG_ LSS_CfgNodeID_ErrCode m17 : 8|8@1+ (1,0) [0|0] "" Vector__XXX
 SG_ LSS_S_CS M : 0|8@1+ (1,0) [0|0] "" Vector__XXX

BO_ 1 GFC: 0 Vector__XXX

BA_DEF_ BO_  "GenMsgSendType" ENUM  "Cyclic","SendType1","SendType2","SendType3","SendType4","SendType5","SendType6","SendType7","SendType8","SendType9";
BA_DEF_ BO_  "GenMsgCycleTime" INT 0 0;
BA_DEF_ SG_  "GenSigStartValue" INT 0 0;
BA_DEF_ BO_  "CO_MsgCategory" INT 0 0;
BA_DEF_ SG_  "SystemSignalLongSymbol" STRING ;
BA_DEF_DEF_  "GenMsgSendType" "";
BA_DEF_DEF_  "GenMsgCycleTime" 0;
BA_DEF_DEF_  "GenSigStartValue" 0;
BA_DEF_DEF_  "CO_MsgCategory" 0;
BA_DEF_DEF_  "SystemSignalLongSymbol" "";
BA_ "CO_MsgCategory" BO_ 138 205;
BA_ "CO_MsgCategory" BO_ 256 115;
BA_ "CO_MsgCategory" BO_ 0 105;
BA_ "CO_MsgCategory" BO_ 2021 610;
BA_ "CO_MsgCategory" BO_ 2020 605;
BA_ "CO_MsgCategory" BO_ 1 705;
BA_ "SystemSignalLongSymbol" SG_ 1546 ExpectedConfigurationTime11_0002 "ExpectedConfigurationTime117_1F27_75";
BA_ "SystemSignalLongSymbol" SG_ 1546 ExpectedConfigurationTime11_0003 "ExpectedConfigurationTime116_1F27_74";
BA_ "SystemSignalLongSymbol" SG_ 1546 ExpectedConfigurationTime11_0004 "ExpectedConfigurationTime115_1F27_73";
BA_ "SystemSignalLongSymbol" SG_ 1546 ExpectedConfigurationTime11_0005 "ExpectedConfigurationTime114_1F27_72";
BA_ "SystemSignalLongSymbol" SG_ 1546 ExpectedConfigurationTime11_0006 "ExpectedConfigurationTime113_1F27_71";
BA_ "SystemSignalLongSymbol" SG_ 1546 ExpectedConfigurationTime11_0007 "ExpectedConfigurationTime112_1F27_70";
BA_ "SystemSignalLongSymbol" SG_ 1546 ExpectedConfigurationTime11_0008 "ExpectedConfigurationTime111_1F27_6F";
BA_ "SystemSignalLongSymbol" SG_ 1546 ExpectedConfigurationTime11_0009 "ExpectedConfigurationTime110_1F27_6E";
BA_ "SystemSignalLongSymbol" SG_ 1546 ExpectedConfigurationTime10_0000 "ExpectedConfigurationTime109_1F27_6D";
BA_ "SystemSignalLongSymbol" SG_ 1546 ExpectedConfigurationTime10_0001 "ExpectedConfigurationTime108_1F27_6C";
BA_ "SystemSignalLongSymbol" SG_ 1546 ExpectedConfigurationTime10_0002 "ExpectedConfigurationTime107_1F27_6B";
BA_ "SystemSignalLongSymbol" SG_ 1546 ExpectedConfigurationTime10_0003 "ExpectedConfigurationTime106_1F27_6A";
BA_ "SystemSignalLongSymbol" SG_ 1546 ExpectedConfigurationTime10_0004 "ExpectedConfigurationTime105_1F27_69";
BA_ "SystemSignalLongSymbol" SG_ 1546 ExpectedConfigurationTime10_0005 "ExpectedConfigurationTime104_1F27_68";
BA_ "SystemSignalLongSymbol" SG_ 1546 ExpectedConfigurationTime10_0006 "ExpectedConfigurationTime103_1F27_67";
BA_ "SystemSignalLongSymbol" SG_ 1546 ExpectedConfigurationTime10_0007 "ExpectedConfigurationTime102_1F27_66";
BA_ "SystemSignalLongSymbol" SG_ 1546 ExpectedConfigurationTime10_0008 "ExpectedConfigurationTime101_1F27_65";
BA_ "SystemSignalLongSymbol" SG_ 1546 ExpectedConfigurationTime10_0009 "ExpectedConfigurationTime100_1F27_64";
BA_ "SystemSignalLongSymbol" SG_ 1546 ExpectedConfigurationTime99_0000 "ExpectedConfigurationTime99_1F27_63";
BA_ "SystemSignalLongSymbol" SG_ 1546 ExpectedConfigurationTime98_0000 "ExpectedConfigurationTime98_1F27_62";
BA_ "SystemSignalLongSymbol" SG_ 1546 ExpectedConfigurationTime97_0000 "ExpectedConfigurationTime97_1F27_61";
BA_ "SystemSignalLongSymbol" SG_ 1546 ExpectedConfigurationTime96_0000 "ExpectedConfigurationTime96_1F27_60";
BA_ "SystemSignalLongSymbol" SG_ 1546 ExpectedConfigurationTime95_0000 "ExpectedConfigurationTime95_1F27_5F";
BA_ "SystemSignalLongSymbol" SG_ 1546 ExpectedConfigurationTime94_0000 "ExpectedConfigurationTime94_1F27_5E";
BA_ "SystemSignalLongSymbol" SG_ 1546 ExpectedConfigurationTime93_0000 "ExpectedConfigurationTime93_1F27_5D";
BA_ "SystemSignalLongSymbol" SG_ 1546 ExpectedConfigurationTime92_0000 "ExpectedConfigurationTime92_1F27_5C";
BA_ "SystemSignalLongSymbol" SG_ 1546 ExpectedConfigurationTime91_0000 "ExpectedConfigurationTime91_1F27_5B";
BA_ "SystemSignalLongSymbol" SG_ 1546 ExpectedConfigurationTime90_0000 "ExpectedConfigurationTime90_1F27_5A";
BA_ "SystemSignalLongSymbol" SG_ 1546 ExpectedConfigurationTime89_0000 "ExpectedConfigurationTime89_1F27_59";
BA_ "SystemSignalLongSymbol" SG_ 1546 ExpectedConfigurationTime88_0000 "ExpectedConfigurationTime88_1F27_58";
BA_ "SystemSignalLongSymbol" SG_ 1546 ExpectedConfigurationTime87_0000 "ExpectedConfigurationTime87_1F27_57";
BA_ "SystemSignalLongSymbol" SG_ 1546 ExpectedConfigurationTime86_0000 "ExpectedConfigurationTime86_1F27_56";
BA_ "SystemSignalLongSymbol" SG_ 1546 ExpectedConfigurationTime85_0000 "ExpectedConfigurationTime85_1F27_55";
BA_ "SystemSignalLongSymbol" SG_ 1546 ExpectedConfigurationTime84_0000 "ExpectedConfigurationTime84_1F27_54";
BA_ "SystemSignalLongSymbol" SG_ 1546 ExpectedConfigurationTime83_0000 "ExpectedConfigurationTime83_1F27_53";
BA_ "SystemSignalLongSymbol" SG_ 1546 ExpectedConfigurationTime82_0000 "ExpectedConfigurationTime82_1F27_52";
BA_ "SystemSignalLongSymbol" SG_ 1546 ExpectedConfigurationTime81_0000 "ExpectedConfigurationTime81_1F27_51";
BA_ "SystemSignalLongSymbol" SG_ 1546 ExpectedConfigurationTime80_0000 "ExpectedConfigurationTime80_1F27_50";
BA_ "SystemSignalLongSymbol" SG_ 1546 ExpectedConfigurationTime79_0000 "ExpectedConfigurationTime79_1F27_4F";
BA_ "SystemSignalLongSymbol" SG_ 1546 ExpectedConfigurationTime78_0000 "ExpectedConfigurationTime78_1F27_4E";
BA_ "SystemSignalLongSymbol" SG_ 1546 ExpectedConfigurationTime77_0000 "ExpectedConfigurationTime77_1F27_4D";
BA_ "SystemSignalLongSymbol" SG_ 1546 ExpectedConfigurationTime76_0000 "ExpectedConfigurationTime76_1F27_4C";
BA_ "SystemSignalLongSymbol" SG_ 1546 ExpectedConfigurationTime75_0000 "ExpectedConfigurationTime75_1F27_4B";
BA_ "SystemSignalLongSymbol" SG_ 1546 ExpectedConfigurationTime74_0000 "ExpectedConfigurationTime74_1F27_4A";
BA_ "SystemSignalLongSymbol" SG_ 1546 ExpectedConfigurationTime73_0000 "ExpectedConfigurationTime73_1F27_49";
BA_ "SystemSignalLongSymbol" SG_ 1546 ExpectedConfigurationTime72_0000 "ExpectedConfigurationTime72_1F27_48";
BA_ "SystemSignalLongSymbol" SG_ 1546 ExpectedConfigurationTime71_0000 "ExpectedConfigurationTime71_1F27_47";
BA_ "SystemSignalLongSymbol" SG_ 1546 ExpectedConfigurationTime70_0000 "ExpectedConfigurationTime70_1F27_46";
BA_ "SystemSignalLongSymbol" SG_ 1546 ExpectedConfigurationTime69_0000 "ExpectedConfigurationTime69_1F27_45";
BA_ "SystemSignalLongSymbol" SG_ 1546 ExpectedConfigurationTime68_0000 "ExpectedConfigurationTime68_1F27_44";
BA_ "SystemSignalLongSymbol" SG_ 1546 ExpectedConfigurationTime67_0000 "ExpectedConfigurationTime67_1F27_43";
BA_ "SystemSignalLongSymbol" SG_ 1546 ExpectedConfigurationTime66_0000 "ExpectedConfigurationTime66_1F27_42";
BA_ "SystemSignalLongSymbol" SG_ 1546 ExpectedConfigurationTime65_0000 "ExpectedConfigurationTime65_1F27_41";
BA_ "SystemSignalLongSymbol" SG_ 1546 ExpectedConfigurationTime64_0000 "ExpectedConfigurationTime64_1F27_40";
BA_ "SystemSignalLongSymbol" SG_ 1546 ExpectedConfigurationTime63_0000 "ExpectedConfigurationTime63_1F27_3F";
BA_ "SystemSignalLongSymbol" SG_ 1546 ExpectedConfigurationTime62_0000 "ExpectedConfigurationTime62_1F27_3E";
BA_ "SystemSignalLongSymbol" SG_ 1546 ExpectedConfigurationTime61_0000 "ExpectedConfigurationTime61_1F27_3D";
BA_ "SystemSignalLongSymbol" SG_ 1546 ExpectedConfigurationTime60_0000 "ExpectedConfigurationTime60_1F27_3C";
BA_ "SystemSignalLongSymbol" SG_ 1546 ExpectedConfigurationTime59_0000 "ExpectedConfigurationTime59_1F27_3B";
BA_ "SystemSignalLongSymbol" SG_ 1546 ExpectedConfigurationTime58_0000 "ExpectedConfigurationTime58_1F27_3A";
BA_ "SystemSignalLongSymbol" SG_ 1546 ExpectedConfigurationTime57_0000 "ExpectedConfigurationTime57_1F27_39";
BA_ "SystemSignalLongSymbol" SG_ 1546 ExpectedConfigurationTime56_0000 "ExpectedConfigurationTime56_1F27_38";
BA_ "SystemSignalLongSymbol" SG_ 1546 ExpectedConfigurationTime55_0000 "ExpectedConfigurationTime55_1F27_37";
BA_ "SystemSignalLongSymbol" SG_ 1546 ExpectedConfigurationTime54_0000 "ExpectedConfigurationTime54_1F27_36";
BA_ "SystemSignalLongSymbol" SG_ 1546 ExpectedConfigurationTime53_0000 "ExpectedConfigurationTime53_1F27_35";
BA_ "SystemSignalLongSymbol" SG_ 1546 ExpectedConfigurationTime52_0000 "ExpectedConfigurationTime52_1F27_34";
BA_ "SystemSignalLongSymbol" SG_ 1546 ExpectedConfigurationTime51_0000 "ExpectedConfigurationTime51_1F27_33";
BA_ "SystemSignalLongSymbol" SG_ 1546 ExpectedConfigurationTime50_0000 "ExpectedConfigurationTime50_1F27_32";
BA_ "SystemSignalLongSymbol" SG_ 1546 ExpectedConfigurationTime49_0000 "ExpectedConfigurationTime49_1F27_31";
BA_ "SystemSignalLongSymbol" SG_ 1546 ExpectedConfigurationTime48_0000 "ExpectedConfigurationTime48_1F27_30";
BA_ "SystemSignalLongSymbol" SG_ 1546 ExpectedConfigurationTime47_0000 "ExpectedConfigurationTime47_1F27_2F";
BA_ "SystemSignalLongSymbol" SG_ 1546 ExpectedConfigurationTime46_0000 "ExpectedConfigurationTime46_1F27_2E";
BA_ "SystemSignalLongSymbol" SG_ 1546 ExpectedConfigurationTime45_0000 "ExpectedConfigurationTime45_1F27_2D";
BA_ "SystemSignalLongSymbol" SG_ 1546 ExpectedConfigurationTime44_0000 "ExpectedConfigurationTime44_1F27_2C";
BA_ "SystemSignalLongSymbol" SG_ 1546 ExpectedConfigurationTime43_0000 "ExpectedConfigurationTime43_1F27_2B";
BA_ "SystemSignalLongSymbol" SG_ 1546 ExpectedConfigurationTime42_0000 "ExpectedConfigurationTime42_1F27_2A";
BA_ "SystemSignalLongSymbol" SG_ 1546 ExpectedConfigurationTime41_0000 "ExpectedConfigurationTime41_1F27_29";
BA_ "SystemSignalLongSymbol" SG_ 1546 ExpectedConfigurationTime40_0000 "ExpectedConfigurationTime40_1F27_28";
BA_ "SystemSignalLongSymbol" SG_ 1546 ExpectedConfigurationTime39_0000 "ExpectedConfigurationTime39_1F27_27";
BA_ "SystemSignalLongSymbol" SG_ 1546 ExpectedConfigurationTime38_0000 "ExpectedConfigurationTime38_1F27_26";
BA_ "SystemSignalLongSymbol" SG_ 1546 ExpectedConfigurationTime37_0000 "ExpectedConfigurationTime37_1F27_25";
BA_ "SystemSignalLongSymbol" SG_ 1546 ExpectedConfigurationTime36_0000 "ExpectedConfigurationTime36_1F27_24";
BA_ "SystemSignalLongSymbol" SG_ 1546 ExpectedConfigurationTime35_0000 "ExpectedConfigurationTime35_1F27_23";
BA_ "SystemSignalLongSymbol" SG_ 1546 ExpectedConfigurationTime34_0000 "ExpectedConfigurationTime34_1F27_22";
BA_ "SystemSignalLongSymbol" SG_ 1546 ExpectedConfigurationTime33_0000 "ExpectedConfigurationTime33_1F27_21";
BA_ "SystemSignalLongSymbol" SG_ 1546 ExpectedConfigurationTime32_0000 "ExpectedConfigurationTime32_1F27_20";
BA_ "SystemSignalLongSymbol" SG_ 1546 ExpectedConfigurationTime31_0000 "ExpectedConfigurationTime31_1F27_1F";
BA_ "SystemSignalLongSymbol" SG_ 1546 ExpectedConfigurationTime30_0000 "ExpectedConfigurationTime30_1F27_1E";
BA_ "SystemSignalLongSymbol" SG_ 1546 ExpectedConfigurationTime29_0000 "ExpectedConfigurationTime29_1F27_1D";
BA_ "SystemSignalLongSymbol" SG_ 1546 ExpectedConfigurationTime28_0000 "ExpectedConfigurationTime28_1F27_1C";
BA_ "SystemSignalLongSymbol" SG_ 1546 ExpectedConfigurationTime27_0000 "ExpectedConfigurationTime27_1F27_1B";
BA_ "SystemSignalLongSymbol" SG_ 1546 ExpectedConfigurationTime26_0000 "ExpectedConfigurationTime26_1F27_1A";
BA_ "SystemSignalLongSymbol" SG_ 1546 ExpectedConfigurationTime25_0000 "ExpectedConfigurationTime25_1F27_19";
BA_ "SystemSignalLongSymbol" SG_ 1546 ExpectedConfigurationTime24_0000 "ExpectedConfigurationTime24_1F27_18";
BA_ "SystemSignalLongSymbol" SG_ 1546 ExpectedConfigurationTime23_0000 "ExpectedConfigurationTime23_1F27_17";
BA_ "SystemSignalLongSymbol" SG_ 1546 ExpectedConfigurationTime22_0000 "ExpectedConfigurationTime22_1F27_16";
BA_ "SystemSignalLongSymbol" SG_ 1546 ExpectedConfigurationTime21_0000 "ExpectedConfigurationTime21_1F27_15";
BA_ "SystemSignalLongSymbol" SG_ 1546 ExpectedConfigurationTime20_0000 "ExpectedConfigurationTime20_1F27_14";
BA_ "SystemSignalLongSymbol" SG_ 1546 ExpectedConfigurationTime19_0000 "ExpectedConfigurationTime19_1F27_13";
BA_ "SystemSignalLongSymbol" SG_ 1546 ExpectedConfigurationTime18_0000 "ExpectedConfigurationTime18_1F27_12";
BA_ "SystemSignalLongSymbol" SG_ 1546 ExpectedConfigurationTime17_0000 "ExpectedConfigurationTime17_1F27_11";
BA_ "SystemSignalLongSymbol" SG_ 1546 ExpectedConfigurationTime16_0000 "ExpectedConfigurationTime16_1F27_10";
BA_ "SystemSignalLongSymbol" SG_ 1546 ExpectedConfigurationTime15_0000 "ExpectedConfigurationTime15_1F27_0F";
BA_ "SystemSignalLongSymbol" SG_ 1546 ExpectedConfigurationTime14_0000 "ExpectedConfigurationTime14_1F27_0E";
BA_ "SystemSignalLongSymbol" SG_ 1546 ExpectedConfigurationTime13_0000 "ExpectedConfigurationTime13_1F27_0D";
BA_ "SystemSignalLongSymbol" SG_ 1546 ExpectedConfigurationTime12_0008 "ExpectedConfigurationTime12_1F27_0C";
BA_ "SystemSignalLongSymbol" SG_ 1546 ExpectedConfigurationTime11_0010 "ExpectedConfigurationTime11_1F27_0B";
BA_ "SystemSignalLongSymbol" SG_ 1546 ExpectedConfigurationTime10_0010 "ExpectedConfigurationTime10_1F27_0A";
BA_ "SystemSignalLongSymbol" SG_ 1546 ExpectedConfigurationTime9__0000 "ExpectedConfigurationTime9_1F27_09";
BA_ "SystemSignalLongSymbol" SG_ 1546 ExpectedConfigurationTime8__0000 "ExpectedConfigurationTime8_1F27_08";
BA_ "SystemSignalLongSymbol" SG_ 1546 ExpectedConfigurationTime7__0000 "ExpectedConfigurationTime7_1F27_07";
BA_ "SystemSignalLongSymbol" SG_ 1546 ExpectedConfigurationTime6__0000 "ExpectedConfigurationTime6_1F27_06";
BA_ "SystemSignalLongSymbol" SG_ 1546 ExpectedConfigurationTime5__0000 "ExpectedConfigurationTime5_1F27_05";
BA_ "SystemSignalLongSymbol" SG_ 1546 ExpectedConfigurationTime4__0000 "ExpectedConfigurationTime4_1F27_04";
BA_ "SystemSignalLongSymbol" SG_ 1546 ExpectedConfigurationTime3__0000 "ExpectedConfigurationTime3_1F27_03";
BA_ "SystemSignalLongSymbol" SG_ 1546 ExpectedConfigurationTime2__0000 "ExpectedConfigurationTime2_1F27_02";
BA_ "SystemSignalLongSymbol" SG_ 1546 ExpectedConfigurationTime1__0000 "ExpectedConfigurationTime1_1F27_01";
BA_ "GenSigStartValue" SG_ 1546 NrOfObjects_1F27_00 127;
BA_ "SystemSignalLongSymbol" SG_ 1546 ExpectedConfigurationDate12_0000 "ExpectedConfigurationDate127_1F26_7F";
BA_ "SystemSignalLongSymbol" SG_ 1546 ExpectedConfigurationDate12_0001 "ExpectedConfigurationDate126_1F26_7E";
BA_ "SystemSignalLongSymbol" SG_ 1546 ExpectedConfigurationDate12_0002 "ExpectedConfigurationDate125_1F26_7D";
BA_ "SystemSignalLongSymbol" SG_ 1546 ExpectedConfigurationDate12_0003 "ExpectedConfigurationDate124_1F26_7C";
BA_ "SystemSignalLongSymbol" SG_ 1546 ExpectedConfigurationDate12_0004 "ExpectedConfigurationDate123_1F26_7B";
BA_ "SystemSignalLongSymbol" SG_ 1546 ExpectedConfigurationDate12_0005 "ExpectedConfigurationDate122_1F26_7A";
BA_ "SystemSignalLongSymbol" SG_ 1546 ExpectedConfigurationDate12_0006 "ExpectedConfigurationDate121_1F26_79";
BA_ "SystemSignalLongSymbol" SG_ 1546 ExpectedConfigurationDate12_0007 "ExpectedConfigurationDate120_1F26_78";
BA_ "SystemSignalLongSymbol" SG_ 1546 ExpectedConfigurationDate11_0000 "ExpectedConfigurationDate119_1F26_77";
BA_ "SystemSignalLongSymbol" SG_ 1546 ExpectedConfigurationDate11_0001 "ExpectedConfigurationDate118_1F26_76";
BA_ "SystemSignalLongSymbol" SG_ 1546 ExpectedConfigurationDate11_0002 "ExpectedConfigurationDate117_1F26_75";
BA_ "SystemSignalLongSymbol" SG_ 1546 ExpectedConfigurationDate11_0003 "ExpectedConfigurationDate116_1F26_74";
BA_ "SystemSignalLongSymbol" SG_ 1546 ExpectedConfigurationDate11_0004 "ExpectedConfigurationDate115_1F26_73";
BA_ "SystemSignalLongSymbol" SG_ 1546 ExpectedConfigurationDate11_0005 "ExpectedConfigurationDate114_1F26_72";
BA_ "SystemSignalLongSymbol" SG_ 1546 ExpectedConfigurationDate11_0006 "ExpectedConfigurationDate113_1F26_71";
BA_ "SystemSignalLongSymbol" SG_ 1546 ExpectedConfigurationDate11_0007 "ExpectedConfigurationDate112_1F26_70";
BA_ "SystemSignalLongSymbol" SG_ 1546 ExpectedConfigurationDate11_0008 "ExpectedConfigurationDate111_1F26_6F";
BA_ "SystemSignalLongSymbol" SG_ 1546 ExpectedConfigurationDate11_0009 "ExpectedConfigurationDate110_1F26_6E";
BA_ "SystemSignalLongSymbol" SG_ 1546 ExpectedConfigurationDate10_0000 "ExpectedConfigurationDate109_1F26_6D";
BA_ "SystemSignalLongSymbol" SG_ 1546 ExpectedConfigurationDate10_0001 "ExpectedConfigurationDate108_1F26_6C";
BA_ "SystemSignalLongSymbol" SG_ 1546 ExpectedConfigurationDate10_0002 "ExpectedConfigurationDate107_1F26_6B";
BA_ "SystemSignalLongSymbol" SG_ 1546 ExpectedConfigurationDate10_0003 "ExpectedConfigurationDate106_1F26_6A";
BA_ "SystemSignalLongSymbol" SG_ 1546 ExpectedConfigurationDate10_0004 "ExpectedConfigurationDate105_1F26_69";
BA_ "SystemSignalLongSymbol" SG_ 1546 ExpectedConfigurationDate10_0005 "ExpectedConfigurationDate104_1F26_68";
BA_ "SystemSignalLongSymbol" SG_ 1546 ExpectedConfigurationDate10_0006 "ExpectedConfigurationDate103_1F26_67";
BA_ "SystemSignalLongSymbol" SG_ 1546 ExpectedConfigurationDate10_0007 "ExpectedConfigurationDate102_1F26_66";
BA_ "SystemSignalLongSymbol" SG_ 1546 ExpectedConfigurationDate10_0008 "ExpectedConfigurationDate101_1F26_65";
BA_ "SystemSignalLongSymbol" SG_ 1546 ExpectedConfigurationDate10_0009 "ExpectedConfigurationDate100_1F26_64";
BA_ "SystemSignalLongSymbol" SG_ 1546 ExpectedConfigurationDate99_0000 "ExpectedConfigurationDate99_1F26_63";
BA_ "SystemSignalLongSymbol" SG_ 1546 ExpectedConfigurationDate98_0000 "ExpectedConfigurationDate98_1F26_62";
BA_ "SystemSignalLongSymbol" SG_ 1546 ExpectedConfigurationDate97_0000 "ExpectedConfigurationDate97_1F26_61";
BA_ "SystemSignalLongSymbol" SG_ 1546 ExpectedConfigurationDate96_0000 "ExpectedConfigurationDate96_1F26_60";
BA_ "SystemSignalLongSymbol" SG_ 1546 ExpectedConfigurationDate95_0000 "ExpectedConfigurationDate95_1F26_5F";
BA_ "SystemSignalLongSymbol" SG_ 1546 ExpectedConfigurationDate94_0000 "ExpectedConfigurationDate94_1F26_5E";
BA_ "SystemSignalLongSymbol" SG_ 1546 ExpectedConfigurationDate93_0000 "ExpectedConfigurationDate93_1F26_5D";
BA_ "SystemSignalLongSymbol" SG_ 1546 ExpectedConfigurationDate92_0000 "ExpectedConfigurationDate92_1F26_5C";
BA_ "SystemSignalLongSymbol" SG_ 1546 ExpectedConfigurationDate91_0000 "ExpectedConfigurationDate91_1F26_5B";
BA_ "SystemSignalLongSymbol" SG_ 1546 ExpectedConfigurationDate90_0000 "ExpectedConfigurationDate90_1F26_5A";
BA_ "SystemSignalLongSymbol" SG_ 1546 ExpectedConfigurationDate89_0000 "ExpectedConfigurationDate89_1F26_59";
BA_ "SystemSignalLongSymbol" SG_ 1546 ExpectedConfigurationDate88_0000 "ExpectedConfigurationDate88_1F26_58";
BA_ "SystemSignalLongSymbol" SG_ 1546 ExpectedConfigurationDate87_0000 "ExpectedConfigurationDate87_1F26_57";
BA_ "SystemSignalLongSymbol" SG_ 1546 ExpectedConfigurationDate86_0000 "ExpectedConfigurationDate86_1F26_56";
BA_ "SystemSignalLongSymbol" SG_ 1546 ExpectedConfigurationDate85_0000 "ExpectedConfigurationDate85_1F26_55";
BA_ "SystemSignalLongSymbol" SG_ 1546 ExpectedConfigurationDate84_0000 "ExpectedConfigurationDate84_1F26_54";
BA_ "SystemSignalLongSymbol" SG_ 1546 ExpectedConfigurationDate83_0000 "ExpectedConfigurationDate83_1F26_53";
BA_ "SystemSignalLongSymbol" SG_ 1546 ExpectedConfigurationDate82_0000 "ExpectedConfigurationDate82_1F26_52";
BA_ "SystemSignalLongSymbol" SG_ 1546 ExpectedConfigurationDate81_0000 "ExpectedConfigurationDate81_1F26_51";
BA_ "SystemSignalLongSymbol" SG_ 1546 ExpectedConfigurationDate80_0000 "ExpectedConfigurationDate80_1F26_50";
BA_ "SystemSignalLongSymbol" SG_ 1546 ExpectedConfigurationDate79_0000 "ExpectedConfigurationDate79_1F26_4F";
BA_ "SystemSignalLongSymbol" SG_ 1546 ExpectedConfigurationDate78_0000 "ExpectedConfigurationDate78_1F26_4E";
BA_ "SystemSignalLongSymbol" SG_ 1546 ExpectedConfigurationDate77_0000 "ExpectedConfigurationDate77_1F26_4D";
BA_ "SystemSignalLongSymbol" SG_ 1546 ExpectedConfigurationDate76_0000 "ExpectedConfigurationDate76_1F26_4C";
BA_ "SystemSignalLongSymbol" SG_ 1546 ExpectedConfigurationDate75_0000 "ExpectedConfigurationDate75_1F26_4B";
BA_ "SystemSignalLongSymbol" SG_ 1546 ExpectedConfigurationDate74_0000 "ExpectedConfigurationDate74_1F26_4A";
BA_ "SystemSignalLongSymbol" SG_ 1546 ExpectedConfigurationDate73_0000 "ExpectedConfigurationDate73_1F26_49";
BA_ "SystemSignalLongSymbol" SG_ 1546 ExpectedConfigurationDate72_0000 "ExpectedConfigurationDate72_1F26_48";
BA_ "SystemSignalLongSymbol" SG_ 1546 ExpectedConfigurationDate71_0000 "ExpectedConfigurationDate71_1F26_47";
BA_ "SystemSignalLongSymbol" SG_ 1546 ExpectedConfigurationDate70_0000 "ExpectedConfigurationDate70_1F26_46";
BA_ "SystemSignalLongSymbol" SG_ 1546 ExpectedConfigurationDate69_0000 "ExpectedConfigurationDate69_1F26_45";
BA_ "SystemSignalLongSymbol" SG_ 1546 ExpectedConfigurationDate68_0000 "ExpectedConfigurationDate68_1F26_44";
BA_ "SystemSignalLongSymbol" SG_ 1546 ExpectedConfigurationDate67_0000 "ExpectedConfigurationDate67_1F26_43";
BA_ "SystemSignalLongSymbol" SG_ 1546 ExpectedConfigurationDate66_0000 "ExpectedConfigurationDate66_1F26_42";
BA_ "SystemSignalLongSymbol" SG_ 1546 ExpectedConfigurationDate65_0000 "ExpectedConfigurationDate65_1F26_41";
BA_ "SystemSignalLongSymbol" SG_ 1546 ExpectedConfigurationDate64_0000 "ExpectedConfigurationDate64_1F26_40";
BA_ "SystemSignalLongSymbol" SG_ 1546 ExpectedConfigurationDate63_0000 "ExpectedConfigurationDate63_1F26_3F";
BA_ "SystemSignalLongSymbol" SG_ 1546 ExpectedConfigurationDate62_0000 "ExpectedConfigurationDate62_1F26_3E";
BA_ "SystemSignalLongSymbol" SG_ 1546 ExpectedConfigurationDate61_0000 "ExpectedConfigurationDate61_1F26_3D";
BA_ "SystemSignalLongSymbol" SG_ 1546 ExpectedConfigurationDate60_0000 "ExpectedConfigurationDate60_1F26_3C";
BA_ "SystemSignalLongSymbol" SG_ 1546 ExpectedConfigurationDate59_0000 "ExpectedConfigurationDate59_1F26_3B";
BA_ "SystemSignalLongSymbol" SG_ 1546 ExpectedConfigurationDate58_0000 "ExpectedConfigurationDate58_1F26_3A";
BA_ "SystemSignalLongSymbol" SG_ 1546 ExpectedConfigurationDate57_0000 "ExpectedConfigurationDate57_1F26_39";
BA_ "SystemSignalLongSymbol" SG_ 1546 ExpectedConfigurationDate56_0000 "ExpectedConfigurationDate56_1F26_38";
BA_ "SystemSignalLongSymbol" SG_ 1546 ExpectedConfigurationDate55_0000 "ExpectedConfigurationDate55_1F26_37";
BA_ "SystemSignalLongSymbol" SG_ 1546 ExpectedConfigurationDate54_0000 "ExpectedConfigurationDate54_1F26_36";
BA_ "SystemSignalLongSymbol" SG_ 1546 ExpectedConfigurationDate53_0000 "ExpectedConfigurationDate53_1F26_35";
BA_ "SystemSignalLongSymbol" SG_ 1546 ExpectedConfigurationDate52_0000 "ExpectedConfigurationDate52_1F26_34";
BA_ "SystemSignalLongSymbol" SG_ 1546 ExpectedConfigurationDate51_0000 "ExpectedConfigurationDate51_1F26_33";
BA_ "SystemSignalLongSymbol" SG_ 1546 ExpectedConfigurationDate50_0000 "ExpectedConfigurationDate50_1F26_32";
BA_ "SystemSignalLongSymbol" SG_ 1546 ExpectedConfigurationDate49_0000 "ExpectedConfigurationDate49_1F26_31";
BA_ "SystemSignalLongSymbol" SG_ 1546 ExpectedConfigurationDate48_0000 "ExpectedConfigurationDate48_1F26_30";
BA_ "SystemSignalLongSymbol" SG_ 1546 ExpectedConfigurationDate47_0000 "ExpectedConfigurationDate47_1F26_2F";
BA_ "SystemSignalLongSymbol" SG_ 1546 ExpectedConfigurationDate46_0000 "ExpectedConfigurationDate46_1F26_2E";
BA_ "SystemSignalLongSymbol" SG_ 1546 ExpectedConfigurationDate45_0000 "ExpectedConfigurationDate45_1F26_2D";
BA_ "SystemSignalLongSymbol" SG_ 1546 ExpectedConfigurationDate44_0000 "ExpectedConfigurationDate44_1F26_2C";
BA_ "SystemSignalLongSymbol" SG_ 1546 ExpectedConfigurationDate43_0000 "ExpectedConfigurationDate43_1F26_2B";
BA_ "SystemSignalLongSymbol" SG_ 1546 ExpectedConfigurationDate42_0000 "ExpectedConfigurationDate42_1F26_2A";
BA_ "SystemSignalLongSymbol" SG_ 1546 ExpectedConfigurationDate41_0000 "ExpectedConfigurationDate41_1F26_29";
BA_ "SystemSignalLongSymbol" SG_ 1546 ExpectedConfigurationDate40_0000 "ExpectedConfigurationDate40_1F26_28";
BA_ "SystemSignalLongSymbol" SG_ 1546 ExpectedConfigurationDate39_0000 "ExpectedConfigurationDate39_1F26_27";
BA_ "SystemSignalLongSymbol" SG_ 1546 ExpectedConfigurationDate38_0000 "ExpectedConfigurationDate38_1F26_26";
BA_ "SystemSignalLongSymbol" SG_ 1546 ExpectedConfigurationDate37_0000 "ExpectedConfigurationDate37_1F26_25";
BA_ "SystemSignalLongSymbol" SG_ 1546 ExpectedConfigurationDate36_0000 "ExpectedConfigurationDate36_1F26_24";
BA_ "SystemSignalLongSymbol" SG_ 1546 ExpectedConfigurationDate35_0000 "ExpectedConfigurationDate35_1F26_23";
BA_ "SystemSignalLongSymbol" SG_ 1546 ExpectedConfigurationDate34_0000 "ExpectedConfigurationDate34_1F26_22";
BA_ "SystemSignalLongSymbol" SG_ 1546 ExpectedConfigurationDate33_0000 "ExpectedConfigurationDate33_1F26_21";
BA_ "SystemSignalLongSymbol" SG_ 1546 ExpectedConfigurationDate32_0000 "ExpectedConfigurationDate32_1F26_20";
BA_ "SystemSignalLongSymbol" SG_ 1546 ExpectedConfigurationDate31_0000 "ExpectedConfigurationDate31_1F26_1F";
BA_ "SystemSignalLongSymbol" SG_ 1546 ExpectedConfigurationDate30_0000 "ExpectedConfigurationDate30_1F26_1E";
BA_ "SystemSignalLongSymbol" SG_ 1546 ExpectedConfigurationDate29_0000 "ExpectedConfigurationDate29_1F26_1D";
BA_ "SystemSignalLongSymbol" SG_ 1546 ExpectedConfigurationDate28_0000 "ExpectedConfigurationDate28_1F26_1C";
BA_ "SystemSignalLongSymbol" SG_ 1546 ExpectedConfigurationDate27_0000 "ExpectedConfigurationDate27_1F26_1B";
BA_ "SystemSignalLongSymbol" SG_ 1546 ExpectedConfigurationDate26_0000 "ExpectedConfigurationDate26_1F26_1A";
BA_ "SystemSignalLongSymbol" SG_ 1546 ExpectedConfigurationDate25_0000 "ExpectedConfigurationDate25_1F26_19";
BA_ "SystemSignalLongSymbol" SG_ 1546 ExpectedConfigurationDate24_0000 "ExpectedConfigurationDate24_1F26_18";
BA_ "SystemSignalLongSymbol" SG_ 1546 ExpectedConfigurationDate23_0000 "ExpectedConfigurationDate23_1F26_17";
BA_ "SystemSignalLongSymbol" SG_ 1546 ExpectedConfigurationDate22_0000 "ExpectedConfigurationDate22_1F26_16";
BA_ "SystemSignalLongSymbol" SG_ 1546 ExpectedConfigurationDate21_0000 "ExpectedConfigurationDate21_1F26_15";
BA_ "SystemSignalLongSymbol" SG_ 1546 ExpectedConfigurationDate20_0000 "ExpectedConfigurationDate20_1F26_14";
BA_ "SystemSignalLongSymbol" SG_ 1546 ExpectedConfigurationDate19_0000 "ExpectedConfigurationDate19_1F26_13";
BA_ "SystemSignalLongSymbol" SG_ 1546 ExpectedConfigurationDate18_0000 "ExpectedConfigurationDate18_1F26_12";
BA_ "SystemSignalLongSymbol" SG_ 1546 ExpectedConfigurationDate17_0000 "ExpectedConfigurationDate17_1F26_11";
BA_ "SystemSignalLongSymbol" SG_ 1546 ExpectedConfigurationDate16_0000 "ExpectedConfigurationDate16_1F26_10";
BA_ "SystemSignalLongSymbol" SG_ 1546 ExpectedConfigurationDate15_0000 "ExpectedConfigurationDate15_1F26_0F";
BA_ "SystemSignalLongSymbol" SG_ 1546 ExpectedConfigurationDate14_0000 "ExpectedConfigurationDate14_1F26_0E";
BA_ "SystemSignalLongSymbol" SG_ 1546 ExpectedConfigurationDate13_0000 "ExpectedConfigurationDate13_1F26_0D";
BA_ "SystemSignalLongSymbol" SG_ 1546 ExpectedConfigurationDate12_0008 "ExpectedConfigurationDate12_1F26_0C";
BA_ "SystemSignalLongSymbol" SG_ 1546 ExpectedConfigurationDate11_0010 "ExpectedConfigurationDate11_1F26_0B";
BA_ "SystemSignalLongSymbol" SG_ 1546 ExpectedConfigurationDate10_0010 "ExpectedConfigurationDate10_1F26_0A";
BA_ "SystemSignalLongSymbol" SG_ 1546 ExpectedConfigurationDate9__0000 "ExpectedConfigurationDate9_1F26_09";
BA_ "SystemSignalLongSymbol" SG_ 1546 ExpectedConfigurationDate8__0000 "ExpectedConfigurationDate8_1F26_08";
BA_ "SystemSignalLongSymbol" SG_ 1546 ExpectedConfigurationDate7__0000 "ExpectedConfigurationDate7_1F26_07";
BA_ "SystemSignalLongSymbol" SG_ 1546 ExpectedConfigurationDate6__0000 "ExpectedConfigurationDate6_1F26_06";
BA_ "SystemSignalLongSymbol" SG_ 1546 ExpectedConfigurationDate5__0000 "ExpectedConfigurationDate5_1F26_05";
BA_ "SystemSignalLongSymbol" SG_ 1546 ExpectedConfigurationDate4__0000 "ExpectedConfigurationDate4_1F26_04";
BA_ "SystemSignalLongSymbol" SG_ 1546 ExpectedConfigurationDate3__0000 "ExpectedConfigurationDate3_1F26_03";
BA_ "SystemSignalLongSymbol" SG_ 1546 ExpectedConfigurationDate2__0000 "ExpectedConfigurationDate2_1F26_02";
BA_ "SystemSignalLongSymbol" SG_ 1546 ExpectedConfigurationDate1__0000 "ExpectedConfigurationDate1_1F26_01";
BA_ "GenSigStartValue" SG_ 1546 NrOfObjects_1F26_00 127;
BA_ "GenSigStartValue" SG_ 1546 NrOfObjects_1F25_00 128;
BA_ "GenSigStartValue" SG_ 1546 NrOfObjects_1F22_00 127;
BA_ "GenSigStartValue" SG_ 1546 Safety_configuration_checks_0001 24831;
BA_ "SystemSignalLongSymbol" SG_ 1546 Safety_configuration_checks_0001 "Safety_configuration_checksum_sub3_13FF_03";
BA_ "GenSigStartValue" SG_ 1546 Safety_configuration_checks_0002 47557;
BA_ "SystemSignalLongSymbol" SG_ 1546 Safety_configuration_checks_0002 "Safety_configuration_checksum_sub2_13FF_02";
BA_ "GenSigStartValue" SG_ 1546 Safety_Checksum_13FF_01 21140;
BA_ "GenSigStartValue" SG_ 1546 Safety_checksum_Number_of_e_0006 3;
BA_ "SystemSignalLongSymbol" SG_ 1546 Safety_checksum_Number_of_e_0006 "Safety_checksum_Number_of_entries_13FF_00";
BA_ "GenSigStartValue" SG_ 1546 Configuration_valid_13FE 165;
BA_ "GenSigStartValue" SG_ 1546 SRDO3_mapping_inv_Byte1_1383_02 2789278496;
BA_ "GenSigStartValue" SG_ 1546 SRDO3_mapping_Byte1_1383_01 2789212960;
BA_ "GenSigStartValue" SG_ 1546 SRDO3_Number_of_mapped_obje_0000 2;
BA_ "SystemSignalLongSymbol" SG_ 1546 SRDO3_Number_of_mapped_obje_0000 "SRDO3_Number_of_mapped_objects_1383_00";
BA_ "GenSigStartValue" SG_ 1546 SRDO2_mapping_inv_Byte1_1382_02 2789278240;
BA_ "GenSigStartValue" SG_ 1546 SRDO2_mapping_Byte1_1382_01 2789212704;
BA_ "GenSigStartValue" SG_ 1546 SRDO2_Number_of_mapped_obje_0000 2;
BA_ "SystemSignalLongSymbol" SG_ 1546 SRDO2_Number_of_mapped_obje_0000 "SRDO2_Number_of_mapped_objects_1382_00";
BA_ "GenSigStartValue" SG_ 1546 SRDO1_mapping_inv_Byte1_1381_02 2789277984;
BA_ "GenSigStartValue" SG_ 1546 SRDO1_mapping_Byte1_1381_01 2789212448;
BA_ "GenSigStartValue" SG_ 1546 SRDO1_Number_of_mapped_obje_0006 2;
BA_ "SystemSignalLongSymbol" SG_ 1546 SRDO1_Number_of_mapped_obje_0006 "SRDO1_Number_of_mapped_objects_1381_00";
BA_ "GenSigStartValue" SG_ 1546 SRDO3_communication_par_COB_0000 262;
BA_ "SystemSignalLongSymbol" SG_ 1546 SRDO3_communication_par_COB_0000 "SRDO3_communication_par_COB_ID_2_1303_06";
BA_ "GenSigStartValue" SG_ 1546 SRDO3_communication_par_COB_0001 261;
BA_ "SystemSignalLongSymbol" SG_ 1546 SRDO3_communication_par_COB_0001 "SRDO3_communication_par_COB_ID_1_1303_05";
BA_ "GenSigStartValue" SG_ 1546 SRDO3_communication_par_Tra_0000 254;
BA_ "SystemSignalLongSymbol" SG_ 1546 SRDO3_communication_par_Tra_0000 "SRDO3_communication_par_Transmission_type_1303_04";
BA_ "GenSigStartValue" SG_ 1546 SRDO3_communication_srvt_ti_0000 20;
BA_ "SystemSignalLongSymbol" SG_ 1546 SRDO3_communication_srvt_ti_0000 "SRDO3_communication_srvt_time_1303_03";
BA_ "GenSigStartValue" SG_ 1546 SRDO3_communication_par_sct_0000 50;
BA_ "SystemSignalLongSymbol" SG_ 1546 SRDO3_communication_par_sct_0000 "SRDO3_communication_par_sct_time_1303_02";
BA_ "GenSigStartValue" SG_ 1546 SRDO3_communication_par_Inf_0000 2;
BA_ "SystemSignalLongSymbol" SG_ 1546 SRDO3_communication_par_Inf_0000 "SRDO3_communication_par_Information_direction_1303_01";
BA_ "GenSigStartValue" SG_ 1546 Highest_sub_index_supported_0031 6;
BA_ "SystemSignalLongSymbol" SG_ 1546 Highest_sub_index_supported_0031 "Highest_sub_index_supported_1303_00";
BA_ "GenSigStartValue" SG_ 1546 SRDO2_communication_par_COB_0000 260;
BA_ "SystemSignalLongSymbol" SG_ 1546 SRDO2_communication_par_COB_0000 "SRDO2_communication_par_COB_ID_2_1302_06";
BA_ "GenSigStartValue" SG_ 1546 SRDO2_communication_par_COB_0001 259;
BA_ "SystemSignalLongSymbol" SG_ 1546 SRDO2_communication_par_COB_0001 "SRDO2_communication_par_COB_ID_1_1302_05";
BA_ "GenSigStartValue" SG_ 1546 SRDO2_communication_par_Tra_0000 254;
BA_ "SystemSignalLongSymbol" SG_ 1546 SRDO2_communication_par_Tra_0000 "SRDO2_communication_par_Transmission_type_1302_04";
BA_ "GenSigStartValue" SG_ 1546 SRDO2_communication_srvt_ti_0000 20;
BA_ "SystemSignalLongSymbol" SG_ 1546 SRDO2_communication_srvt_ti_0000 "SRDO2_communication_srvt_time_1302_03";
BA_ "GenSigStartValue" SG_ 1546 SRDO2_communication_par_sct_0000 50;
BA_ "SystemSignalLongSymbol" SG_ 1546 SRDO2_communication_par_sct_0000 "SRDO2_communication_par_sct_time_1302_02";
BA_ "GenSigStartValue" SG_ 1546 SRDO2_communication_par_Inf_0000 2;
BA_ "SystemSignalLongSymbol" SG_ 1546 SRDO2_communication_par_Inf_0000 "SRDO2_communication_par_Information_direction_1302_01";
BA_ "GenSigStartValue" SG_ 1546 Highest_sub_index_supported_0032 6;
BA_ "SystemSignalLongSymbol" SG_ 1546 Highest_sub_index_supported_0032 "Highest_sub_index_supported_1302_00";
BA_ "GenSigStartValue" SG_ 1546 SRDO1_communication_par_COB_0012 258;
BA_ "SystemSignalLongSymbol" SG_ 1546 SRDO1_communication_par_COB_0012 "SRDO1_communication_par_COB_ID_2_1301_06";
BA_ "GenSigStartValue" SG_ 1546 SRDO1_communication_par_COB_0013 257;
BA_ "SystemSignalLongSymbol" SG_ 1546 SRDO1_communication_par_COB_0013 "SRDO1_communication_par_COB_ID_1_1301_05";
BA_ "GenSigStartValue" SG_ 1546 SRDO1_communication_par_Tra_0006 254;
BA_ "SystemSignalLongSymbol" SG_ 1546 SRDO1_communication_par_Tra_0006 "SRDO1_communication_par_Transmission_type_1301_04";
BA_ "GenSigStartValue" SG_ 1546 SRDO1_communication_srvt_ti_0000 20;
BA_ "SystemSignalLongSymbol" SG_ 1546 SRDO1_communication_srvt_ti_0000 "SRDO1_communication_srvt_time_1301_03";
BA_ "GenSigStartValue" SG_ 1546 SRDO1_communication_par_sct_0000 50;
BA_ "SystemSignalLongSymbol" SG_ 1546 SRDO1_communication_par_sct_0000 "SRDO1_communication_par_sct_time_1301_02";
BA_ "GenSigStartValue" SG_ 1546 SRDO1_communication_par_Inf_0006 2;
BA_ "SystemSignalLongSymbol" SG_ 1546 SRDO1_communication_par_Inf_0006 "SRDO1_communication_par_Information_direction_1301_01";
BA_ "GenSigStartValue" SG_ 1546 Highest_sub_index_supported_0033 6;
BA_ "SystemSignalLongSymbol" SG_ 1546 Highest_sub_index_supported_0033 "Highest_sub_index_supported_1301_00";
BA_ "GenSigStartValue" SG_ 1546 Revision_number_1018_03 256;
BA_ "GenSigStartValue" SG_ 1546 Product_Code_1018_02 4369;
BA_ "GenSigStartValue" SG_ 1546 Vendor_Id_1018_01 5;
BA_ "GenSigStartValue" SG_ 1546 Highest_sub_index_supported_0034 4;
BA_ "SystemSignalLongSymbol" SG_ 1546 Highest_sub_index_supported_0034 "Highest_sub_index_supported_1018_00";
BA_ "SystemSignalLongSymbol" SG_ 1546 Consumer_Heartbeat_Time127__0000 "Consumer_Heartbeat_Time127_1016_7F";
BA_ "SystemSignalLongSymbol" SG_ 1546 Consumer_Heartbeat_Time126__0000 "Consumer_Heartbeat_Time126_1016_7E";
BA_ "SystemSignalLongSymbol" SG_ 1546 Consumer_Heartbeat_Time125__0000 "Consumer_Heartbeat_Time125_1016_7D";
BA_ "SystemSignalLongSymbol" SG_ 1546 Consumer_Heartbeat_Time124__0000 "Consumer_Heartbeat_Time124_1016_7C";
BA_ "SystemSignalLongSymbol" SG_ 1546 Consumer_Heartbeat_Time123__0000 "Consumer_Heartbeat_Time123_1016_7B";
BA_ "SystemSignalLongSymbol" SG_ 1546 Consumer_Heartbeat_Time122__0000 "Consumer_Heartbeat_Time122_1016_7A";
BA_ "SystemSignalLongSymbol" SG_ 1546 Consumer_Heartbeat_Time121__0000 "Consumer_Heartbeat_Time121_1016_79";
BA_ "SystemSignalLongSymbol" SG_ 1546 Consumer_Heartbeat_Time120__0000 "Consumer_Heartbeat_Time120_1016_78";
BA_ "SystemSignalLongSymbol" SG_ 1546 Consumer_Heartbeat_Time119__0000 "Consumer_Heartbeat_Time119_1016_77";
BA_ "SystemSignalLongSymbol" SG_ 1546 Consumer_Heartbeat_Time118__0000 "Consumer_Heartbeat_Time118_1016_76";
BA_ "SystemSignalLongSymbol" SG_ 1546 Consumer_Heartbeat_Time117__0000 "Consumer_Heartbeat_Time117_1016_75";
BA_ "SystemSignalLongSymbol" SG_ 1546 Consumer_Heartbeat_Time116__0000 "Consumer_Heartbeat_Time116_1016_74";
BA_ "SystemSignalLongSymbol" SG_ 1546 Consumer_Heartbeat_Time115__0000 "Consumer_Heartbeat_Time115_1016_73";
BA_ "SystemSignalLongSymbol" SG_ 1546 Consumer_Heartbeat_Time114__0000 "Consumer_Heartbeat_Time114_1016_72";
BA_ "SystemSignalLongSymbol" SG_ 1546 Consumer_Heartbeat_Time113__0000 "Consumer_Heartbeat_Time113_1016_71";
BA_ "SystemSignalLongSymbol" SG_ 1546 Consumer_Heartbeat_Time112__0000 "Consumer_Heartbeat_Time112_1016_70";
BA_ "SystemSignalLongSymbol" SG_ 1546 Consumer_Heartbeat_Time111__0000 "Consumer_Heartbeat_Time111_1016_6F";
BA_ "SystemSignalLongSymbol" SG_ 1546 Consumer_Heartbeat_Time110__0000 "Consumer_Heartbeat_Time110_1016_6E";
BA_ "SystemSignalLongSymbol" SG_ 1546 Consumer_Heartbeat_Time109__0000 "Consumer_Heartbeat_Time109_1016_6D";
BA_ "SystemSignalLongSymbol" SG_ 1546 Consumer_Heartbeat_Time108__0000 "Consumer_Heartbeat_Time108_1016_6C";
BA_ "SystemSignalLongSymbol" SG_ 1546 Consumer_Heartbeat_Time107__0000 "Consumer_Heartbeat_Time107_1016_6B";
BA_ "SystemSignalLongSymbol" SG_ 1546 Consumer_Heartbeat_Time106__0000 "Consumer_Heartbeat_Time106_1016_6A";
BA_ "SystemSignalLongSymbol" SG_ 1546 Consumer_Heartbeat_Time105__0000 "Consumer_Heartbeat_Time105_1016_69";
BA_ "SystemSignalLongSymbol" SG_ 1546 Consumer_Heartbeat_Time104__0000 "Consumer_Heartbeat_Time104_1016_68";
BA_ "SystemSignalLongSymbol" SG_ 1546 Consumer_Heartbeat_Time103__0000 "Consumer_Heartbeat_Time103_1016_67";
BA_ "SystemSignalLongSymbol" SG_ 1546 Consumer_Heartbeat_Time102__0000 "Consumer_Heartbeat_Time102_1016_66";
BA_ "SystemSignalLongSymbol" SG_ 1546 Consumer_Heartbeat_Time101__0000 "Consumer_Heartbeat_Time101_1016_65";
BA_ "SystemSignalLongSymbol" SG_ 1546 Consumer_Heartbeat_Time100__0000 "Consumer_Heartbeat_Time100_1016_64";
BA_ "SystemSignalLongSymbol" SG_ 1546 Consumer_Heartbeat_Time99_1_0000 "Consumer_Heartbeat_Time99_1016_63";
BA_ "SystemSignalLongSymbol" SG_ 1546 Consumer_Heartbeat_Time98_1_0000 "Consumer_Heartbeat_Time98_1016_62";
BA_ "SystemSignalLongSymbol" SG_ 1546 Consumer_Heartbeat_Time97_1_0000 "Consumer_Heartbeat_Time97_1016_61";
BA_ "SystemSignalLongSymbol" SG_ 1546 Consumer_Heartbeat_Time96_1_0000 "Consumer_Heartbeat_Time96_1016_60";
BA_ "SystemSignalLongSymbol" SG_ 1546 Consumer_Heartbeat_Time95_1_0000 "Consumer_Heartbeat_Time95_1016_5F";
BA_ "SystemSignalLongSymbol" SG_ 1546 Consumer_Heartbeat_Time94_1_0000 "Consumer_Heartbeat_Time94_1016_5E";
BA_ "SystemSignalLongSymbol" SG_ 1546 Consumer_Heartbeat_Time93_1_0000 "Consumer_Heartbeat_Time93_1016_5D";
BA_ "SystemSignalLongSymbol" SG_ 1546 Consumer_Heartbeat_Time92_1_0000 "Consumer_Heartbeat_Time92_1016_5C";
BA_ "SystemSignalLongSymbol" SG_ 1546 Consumer_Heartbeat_Time91_1_0000 "Consumer_Heartbeat_Time91_1016_5B";
BA_ "SystemSignalLongSymbol" SG_ 1546 Consumer_Heartbeat_Time90_1_0000 "Consumer_Heartbeat_Time90_1016_5A";
BA_ "SystemSignalLongSymbol" SG_ 1546 Consumer_Heartbeat_Time89_1_0000 "Consumer_Heartbeat_Time89_1016_59";
BA_ "SystemSignalLongSymbol" SG_ 1546 Consumer_Heartbeat_Time88_1_0000 "Consumer_Heartbeat_Time88_1016_58";
BA_ "SystemSignalLongSymbol" SG_ 1546 Consumer_Heartbeat_Time87_1_0000 "Consumer_Heartbeat_Time87_1016_57";
BA_ "SystemSignalLongSymbol" SG_ 1546 Consumer_Heartbeat_Time86_1_0000 "Consumer_Heartbeat_Time86_1016_56";
BA_ "SystemSignalLongSymbol" SG_ 1546 Consumer_Heartbeat_Time85_1_0000 "Consumer_Heartbeat_Time85_1016_55";
BA_ "SystemSignalLongSymbol" SG_ 1546 Consumer_Heartbeat_Time84_1_0000 "Consumer_Heartbeat_Time84_1016_54";
BA_ "SystemSignalLongSymbol" SG_ 1546 Consumer_Heartbeat_Time83_1_0000 "Consumer_Heartbeat_Time83_1016_53";
BA_ "SystemSignalLongSymbol" SG_ 1546 Consumer_Heartbeat_Time82_1_0000 "Consumer_Heartbeat_Time82_1016_52";
BA_ "SystemSignalLongSymbol" SG_ 1546 Consumer_Heartbeat_Time81_1_0000 "Consumer_Heartbeat_Time81_1016_51";
BA_ "SystemSignalLongSymbol" SG_ 1546 Consumer_Heartbeat_Time80_1_0000 "Consumer_Heartbeat_Time80_1016_50";
BA_ "SystemSignalLongSymbol" SG_ 1546 Consumer_Heartbeat_Time79_1_0000 "Consumer_Heartbeat_Time79_1016_4F";
BA_ "SystemSignalLongSymbol" SG_ 1546 Consumer_Heartbeat_Time78_1_0000 "Consumer_Heartbeat_Time78_1016_4E";
BA_ "SystemSignalLongSymbol" SG_ 1546 Consumer_Heartbeat_Time77_1_0000 "Consumer_Heartbeat_Time77_1016_4D";
BA_ "SystemSignalLongSymbol" SG_ 1546 Consumer_Heartbeat_Time76_1_0000 "Consumer_Heartbeat_Time76_1016_4C";
BA_ "SystemSignalLongSymbol" SG_ 1546 Consumer_Heartbeat_Time75_1_0000 "Consumer_Heartbeat_Time75_1016_4B";
BA_ "SystemSignalLongSymbol" SG_ 1546 Consumer_Heartbeat_Time74_1_0000 "Consumer_Heartbeat_Time74_1016_4A";
BA_ "SystemSignalLongSymbol" SG_ 1546 Consumer_Heartbeat_Time73_1_0000 "Consumer_Heartbeat_Time73_1016_49";
BA_ "SystemSignalLongSymbol" SG_ 1546 Consumer_Heartbeat_Time72_1_0000 "Consumer_Heartbeat_Time72_1016_48";
BA_ "SystemSignalLongSymbol" SG_ 1546 Consumer_Heartbeat_Time71_1_0000 "Consumer_Heartbeat_Time71_1016_47";
BA_ "SystemSignalLongSymbol" SG_ 1546 Consumer_Heartbeat_Time70_1_0000 "Consumer_Heartbeat_Time70_1016_46";
BA_ "SystemSignalLongSymbol" SG_ 1546 Consumer_Heartbeat_Time69_1_0000 "Consumer_Heartbeat_Time69_1016_45";
BA_ "SystemSignalLongSymbol" SG_ 1546 Consumer_Heartbeat_Time68_1_0000 "Consumer_Heartbeat_Time68_1016_44";
BA_ "SystemSignalLongSymbol" SG_ 1546 Consumer_Heartbeat_Time67_1_0000 "Consumer_Heartbeat_Time67_1016_43";
BA_ "SystemSignalLongSymbol" SG_ 1546 Consumer_Heartbeat_Time66_1_0000 "Consumer_Heartbeat_Time66_1016_42";
BA_ "SystemSignalLongSymbol" SG_ 1546 Consumer_Heartbeat_Time65_1_0000 "Consumer_Heartbeat_Time65_1016_41";
BA_ "SystemSignalLongSymbol" SG_ 1546 Consumer_Heartbeat_Time64_1_0000 "Consumer_Heartbeat_Time64_1016_40";
BA_ "SystemSignalLongSymbol" SG_ 1546 Consumer_Heartbeat_Time63_1_0000 "Consumer_Heartbeat_Time63_1016_3F";
BA_ "SystemSignalLongSymbol" SG_ 1546 Consumer_Heartbeat_Time62_1_0000 "Consumer_Heartbeat_Time62_1016_3E";
BA_ "SystemSignalLongSymbol" SG_ 1546 Consumer_Heartbeat_Time61_1_0000 "Consumer_Heartbeat_Time61_1016_3D";
BA_ "SystemSignalLongSymbol" SG_ 1546 Consumer_Heartbeat_Time60_1_0000 "Consumer_Heartbeat_Time60_1016_3C";
BA_ "SystemSignalLongSymbol" SG_ 1546 Consumer_Heartbeat_Time59_1_0000 "Consumer_Heartbeat_Time59_1016_3B";
BA_ "SystemSignalLongSymbol" SG_ 1546 Consumer_Heartbeat_Time58_1_0000 "Consumer_Heartbeat_Time58_1016_3A";
BA_ "SystemSignalLongSymbol" SG_ 1546 Consumer_Heartbeat_Time57_1_0000 "Consumer_Heartbeat_Time57_1016_39";
BA_ "SystemSignalLongSymbol" SG_ 1546 Consumer_Heartbeat_Time56_1_0000 "Consumer_Heartbeat_Time56_1016_38";
BA_ "SystemSignalLongSymbol" SG_ 1546 Consumer_Heartbeat_Time55_1_0000 "Consumer_Heartbeat_Time55_1016_37";
BA_ "SystemSignalLongSymbol" SG_ 1546 Consumer_Heartbeat_Time54_1_0000 "Consumer_Heartbeat_Time54_1016_36";
BA_ "SystemSignalLongSymbol" SG_ 1546 Consumer_Heartbeat_Time53_1_0000 "Consumer_Heartbeat_Time53_1016_35";
BA_ "SystemSignalLongSymbol" SG_ 1546 Consumer_Heartbeat_Time52_1_0000 "Consumer_Heartbeat_Time52_1016_34";
BA_ "SystemSignalLongSymbol" SG_ 1546 Consumer_Heartbeat_Time51_1_0000 "Consumer_Heartbeat_Time51_1016_33";
BA_ "SystemSignalLongSymbol" SG_ 1546 Consumer_Heartbeat_Time50_1_0000 "Consumer_Heartbeat_Time50_1016_32";
BA_ "SystemSignalLongSymbol" SG_ 1546 Consumer_Heartbeat_Time49_1_0000 "Consumer_Heartbeat_Time49_1016_31";
BA_ "SystemSignalLongSymbol" SG_ 1546 Consumer_Heartbeat_Time48_1_0000 "Consumer_Heartbeat_Time48_1016_30";
BA_ "SystemSignalLongSymbol" SG_ 1546 Consumer_Heartbeat_Time47_1_0000 "Consumer_Heartbeat_Time47_1016_2F";
BA_ "SystemSignalLongSymbol" SG_ 1546 Consumer_Heartbeat_Time46_1_0000 "Consumer_Heartbeat_Time46_1016_2E";
BA_ "SystemSignalLongSymbol" SG_ 1546 Consumer_Heartbeat_Time45_1_0000 "Consumer_Heartbeat_Time45_1016_2D";
BA_ "SystemSignalLongSymbol" SG_ 1546 Consumer_Heartbeat_Time44_1_0000 "Consumer_Heartbeat_Time44_1016_2C";
BA_ "SystemSignalLongSymbol" SG_ 1546 Consumer_Heartbeat_Time43_1_0000 "Consumer_Heartbeat_Time43_1016_2B";
BA_ "SystemSignalLongSymbol" SG_ 1546 Consumer_Heartbeat_Time42_1_0000 "Consumer_Heartbeat_Time42_1016_2A";
BA_ "SystemSignalLongSymbol" SG_ 1546 Consumer_Heartbeat_Time41_1_0000 "Consumer_Heartbeat_Time41_1016_29";
BA_ "SystemSignalLongSymbol" SG_ 1546 Consumer_Heartbeat_Time40_1_0000 "Consumer_Heartbeat_Time40_1016_28";
BA_ "SystemSignalLongSymbol" SG_ 1546 Consumer_Heartbeat_Time39_1_0000 "Consumer_Heartbeat_Time39_1016_27";
BA_ "SystemSignalLongSymbol" SG_ 1546 Consumer_Heartbeat_Time38_1_0000 "Consumer_Heartbeat_Time38_1016_26";
BA_ "SystemSignalLongSymbol" SG_ 1546 Consumer_Heartbeat_Time37_1_0000 "Consumer_Heartbeat_Time37_1016_25";
BA_ "SystemSignalLongSymbol" SG_ 1546 Consumer_Heartbeat_Time36_1_0000 "Consumer_Heartbeat_Time36_1016_24";
BA_ "SystemSignalLongSymbol" SG_ 1546 Consumer_Heartbeat_Time35_1_0000 "Consumer_Heartbeat_Time35_1016_23";
BA_ "SystemSignalLongSymbol" SG_ 1546 Consumer_Heartbeat_Time34_1_0000 "Consumer_Heartbeat_Time34_1016_22";
BA_ "SystemSignalLongSymbol" SG_ 1546 Consumer_Heartbeat_Time33_1_0000 "Consumer_Heartbeat_Time33_1016_21";
BA_ "SystemSignalLongSymbol" SG_ 1546 Consumer_Heartbeat_Time32_1_0000 "Consumer_Heartbeat_Time32_1016_20";
BA_ "SystemSignalLongSymbol" SG_ 1546 Consumer_Heartbeat_Time31_1_0000 "Consumer_Heartbeat_Time31_1016_1F";
BA_ "SystemSignalLongSymbol" SG_ 1546 Consumer_Heartbeat_Time30_1_0000 "Consumer_Heartbeat_Time30_1016_1E";
BA_ "SystemSignalLongSymbol" SG_ 1546 Consumer_Heartbeat_Time29_1_0000 "Consumer_Heartbeat_Time29_1016_1D";
BA_ "SystemSignalLongSymbol" SG_ 1546 Consumer_Heartbeat_Time28_1_0000 "Consumer_Heartbeat_Time28_1016_1C";
BA_ "SystemSignalLongSymbol" SG_ 1546 Consumer_Heartbeat_Time27_1_0000 "Consumer_Heartbeat_Time27_1016_1B";
BA_ "SystemSignalLongSymbol" SG_ 1546 Consumer_Heartbeat_Time26_1_0000 "Consumer_Heartbeat_Time26_1016_1A";
BA_ "SystemSignalLongSymbol" SG_ 1546 Consumer_Heartbeat_Time25_1_0000 "Consumer_Heartbeat_Time25_1016_19";
BA_ "SystemSignalLongSymbol" SG_ 1546 Consumer_Heartbeat_Time24_1_0000 "Consumer_Heartbeat_Time24_1016_18";
BA_ "SystemSignalLongSymbol" SG_ 1546 Consumer_Heartbeat_Time23_1_0000 "Consumer_Heartbeat_Time23_1016_17";
BA_ "SystemSignalLongSymbol" SG_ 1546 Consumer_Heartbeat_Time22_1_0000 "Consumer_Heartbeat_Time22_1016_16";
BA_ "SystemSignalLongSymbol" SG_ 1546 Consumer_Heartbeat_Time21_1_0000 "Consumer_Heartbeat_Time21_1016_15";
BA_ "SystemSignalLongSymbol" SG_ 1546 Consumer_Heartbeat_Time20_1_0000 "Consumer_Heartbeat_Time20_1016_14";
BA_ "SystemSignalLongSymbol" SG_ 1546 Consumer_Heartbeat_Time19_1_0000 "Consumer_Heartbeat_Time19_1016_13";
BA_ "SystemSignalLongSymbol" SG_ 1546 Consumer_Heartbeat_Time18_1_0000 "Consumer_Heartbeat_Time18_1016_12";
BA_ "SystemSignalLongSymbol" SG_ 1546 Consumer_Heartbeat_Time17_1_0000 "Consumer_Heartbeat_Time17_1016_11";
BA_ "SystemSignalLongSymbol" SG_ 1546 Consumer_Heartbeat_Time16_1_0006 "Consumer_Heartbeat_Time16_1016_10";
BA_ "SystemSignalLongSymbol" SG_ 1546 Consumer_Heartbeat_Time15_1_0006 "Consumer_Heartbeat_Time15_1016_0F";
BA_ "SystemSignalLongSymbol" SG_ 1546 Consumer_Heartbeat_Time14_1_0006 "Consumer_Heartbeat_Time14_1016_0E";
BA_ "SystemSignalLongSymbol" SG_ 1546 Consumer_Heartbeat_Time13_1_0006 "Consumer_Heartbeat_Time13_1016_0D";
BA_ "SystemSignalLongSymbol" SG_ 1546 Consumer_Heartbeat_Time12_1_0006 "Consumer_Heartbeat_Time12_1016_0C";
BA_ "SystemSignalLongSymbol" SG_ 1546 Consumer_Heartbeat_Time11_1_0006 "Consumer_Heartbeat_Time11_1016_0B";
BA_ "SystemSignalLongSymbol" SG_ 1546 Consumer_Heartbeat_Time10_1_0006 "Consumer_Heartbeat_Time10_1016_0A";
BA_ "GenSigStartValue" SG_ 1546 Consumer_Heartbeat_Time3_1016_03 1836008;
BA_ "GenSigStartValue" SG_ 1546 Consumer_Heartbeat_Time2_1016_02 1770472;
BA_ "GenSigStartValue" SG_ 1546 Consumer_Heartbeat_Time1_1016_01 1508328;
BA_ "GenSigStartValue" SG_ 1546 NrOfObjects_1016_00 127;
BA_ "SystemSignalLongSymbol" SG_ 1546 Restore_all_Default_Paramet_0006 "Restore_all_Default_Parameters_1011_01";
BA_ "GenSigStartValue" SG_ 1546 Highest_sub_index_supported_0035 1;
BA_ "SystemSignalLongSymbol" SG_ 1546 Highest_sub_index_supported_0035 "Highest_sub_index_supported_1011_00";
BA_ "GenSigStartValue" SG_ 1546 Highest_sub_index_supported_0036 1;
BA_ "SystemSignalLongSymbol" SG_ 1546 Highest_sub_index_supported_0036 "Highest_sub_index_supported_1010_00";
BA_ "GenSigStartValue" SG_ 1546 Sync_Window_Length_1007 50000;
BA_ "GenSigStartValue" SG_ 1546 Communication_Cycle_Period_1006 100000;
BA_ "GenSigStartValue" SG_ 1546 COB_ID_SYNC_1005 3221225600;
BA_ "GenSigStartValue" SG_ 1546 Device_Type_1000 405;
BA_ "GenSigStartValue" SG_ 1546 Index 4096;
VAL_ 1546 SubIndex_1F27 127 "ExpectedConfigurationTime127" 126 "ExpectedConfigurationTime126" 125 "ExpectedConfigurationTime125" 124 "ExpectedConfigurationTime124" 123 "ExpectedConfigurationTime123" 122 "ExpectedConfigurationTime122" 121 "ExpectedConfigurationTime121" 120 "ExpectedConfigurationTime120" 119 "ExpectedConfigurationTime119" 118 "ExpectedConfigurationTime118" 117 "ExpectedConfigurationTime117" 116 "ExpectedConfigurationTime116" 115 "ExpectedConfigurationTime115" 114 "ExpectedConfigurationTime114" 113 "ExpectedConfigurationTime113" 112 "ExpectedConfigurationTime112" 111 "ExpectedConfigurationTime111" 110 "ExpectedConfigurationTime110" 109 "ExpectedConfigurationTime109" 108 "ExpectedConfigurationTime108" 107 "ExpectedConfigurationTime107" 106 "ExpectedConfigurationTime106" 105 "ExpectedConfigurationTime105" 104 "ExpectedConfigurationTime104" 103 "ExpectedConfigurationTime103" 102 "ExpectedConfigurationTime102" 101 "ExpectedConfigurationTime101" 100 "ExpectedConfigurationTime100" 99 "ExpectedConfigurationTime99" 98 "ExpectedConfigurationTime98" 97 "ExpectedConfigurationTime97" 96 "ExpectedConfigurationTime96" 95 "ExpectedConfigurationTime95" 94 "ExpectedConfigurationTime94" 93 "ExpectedConfigurationTime93" 92 "ExpectedConfigurationTime92" 91 "ExpectedConfigurationTime91" 90 "ExpectedConfigurationTime90" 89 "ExpectedConfigurationTime89" 88 "ExpectedConfigurationTime88" 87 "ExpectedConfigurationTime87" 86 "ExpectedConfigurationTime86" 85 "ExpectedConfigurationTime85" 84 "ExpectedConfigurationTime84" 83 "ExpectedConfigurationTime83" 82 "ExpectedConfigurationTime82" 81 "ExpectedConfigurationTime81" 80 "ExpectedConfigurationTime80" 79 "ExpectedConfigurationTime79" 78 "ExpectedConfigurationTime78" 77 "ExpectedConfigurationTime77" 76 "ExpectedConfigurationTime76" 75 "ExpectedConfigurationTime75" 74 "ExpectedConfigurationTime74" 73 "ExpectedConfigurationTime73" 72 "ExpectedConfigurationTime72" 71 "ExpectedConfigurationTime71" 70 "ExpectedConfigurationTime70" 69 "ExpectedConfigurationTime69" 68 "ExpectedConfigurationTime68" 67 "ExpectedConfigurationTime67" 66 "ExpectedConfigurationTime66" 65 "ExpectedConfigurationTime65" 64 "ExpectedConfigurationTime64" 63 "ExpectedConfigurationTime63" 62 "ExpectedConfigurationTime62" 61 "ExpectedConfigurationTime61" 60 "ExpectedConfigurationTime60" 59 "ExpectedConfigurationTime59" 58 "ExpectedConfigurationTime58" 57 "ExpectedConfigurationTime57" 56 "ExpectedConfigurationTime56" 55 "ExpectedConfigurationTime55" 54 "ExpectedConfigurationTime54" 53 "ExpectedConfigurationTime53" 52 "ExpectedConfigurationTime52" 51 "ExpectedConfigurationTime51" 50 "ExpectedConfigurationTime50" 49 "ExpectedConfigurationTime49" 48 "ExpectedConfigurationTime48" 47 "ExpectedConfigurationTime47" 46 "ExpectedConfigurationTime46" 45 "ExpectedConfigurationTime45" 44 "ExpectedConfigurationTime44" 43 "ExpectedConfigurationTime43" 42 "ExpectedConfigurationTime42" 41 "ExpectedConfigurationTime41" 40 "ExpectedConfigurationTime40" 39 "ExpectedConfigurationTime39" 38 "ExpectedConfigurationTime38" 37 "ExpectedConfigurationTime37" 36 "ExpectedConfigurationTime36" 35 "ExpectedConfigurationTime35" 34 "ExpectedConfigurationTime34" 33 "ExpectedConfigurationTime33" 32 "ExpectedConfigurationTime32" 31 "ExpectedConfigurationTime31" 30 "ExpectedConfigurationTime30" 29 "ExpectedConfigurationTime29" 28 "ExpectedConfigurationTime28" 27 "ExpectedConfigurationTime27" 26 "ExpectedConfigurationTime26" 25 "ExpectedConfigurationTime25" 24 "ExpectedConfigurationTime24" 23 "ExpectedConfigurationTime23" 22 "ExpectedConfigurationTime22" 21 "ExpectedConfigurationTime21" 20 "ExpectedConfigurationTime20" 19 "ExpectedConfigurationTime19" 18 "ExpectedConfigurationTime18" 17 "ExpectedConfigurationTime17" 16 "ExpectedConfigurationTime16" 15 "ExpectedConfigurationTime15" 14 "ExpectedConfigurationTime14" 13 "ExpectedConfigurationTime13" 12 "ExpectedConfigurationTime12" 11 "ExpectedConfigurationTime11" 10 "ExpectedConfigurationTime10" 9 "ExpectedConfigurationTime9" 8 "ExpectedConfigurationTime8" 7 "ExpectedConfigurationTime7" 6 "ExpectedConfigurationTime6" 5 "ExpectedConfigurationTime5" 4 "ExpectedConfigurationTime4" 3 "ExpectedConfigurationTime3" 2 "ExpectedConfigurationTime2" 1 "ExpectedConfigurationTime1" 0 "NrOfObjects" ;
VAL_ 1546 SubIndex_1F26 127 "ExpectedConfigurationDate127" 126 "ExpectedConfigurationDate126" 125 "ExpectedConfigurationDate125" 124 "ExpectedConfigurationDate124" 123 "ExpectedConfigurationDate123" 122 "ExpectedConfigurationDate122" 121 "ExpectedConfigurationDate121" 120 "ExpectedConfigurationDate120" 119 "ExpectedConfigurationDate119" 118 "ExpectedConfigurationDate118" 117 "ExpectedConfigurationDate117" 116 "ExpectedConfigurationDate116" 115 "ExpectedConfigurationDate115" 114 "ExpectedConfigurationDate114" 113 "ExpectedConfigurationDate113" 112 "ExpectedConfigurationDate112" 111 "ExpectedConfigurationDate111" 110 "ExpectedConfigurationDate110" 109 "ExpectedConfigurationDate109" 108 "ExpectedConfigurationDate108" 107 "ExpectedConfigurationDate107" 106 "ExpectedConfigurationDate106" 105 "ExpectedConfigurationDate105" 104 "ExpectedConfigurationDate104" 103 "ExpectedConfigurationDate103" 102 "ExpectedConfigurationDate102" 101 "ExpectedConfigurationDate101" 100 "ExpectedConfigurationDate100" 99 "ExpectedConfigurationDate99" 98 "ExpectedConfigurationDate98" 97 "ExpectedConfigurationDate97" 96 "ExpectedConfigurationDate96" 95 "ExpectedConfigurationDate95" 94 "ExpectedConfigurationDate94" 93 "ExpectedConfigurationDate93" 92 "ExpectedConfigurationDate92" 91 "ExpectedConfigurationDate91" 90 "ExpectedConfigurationDate90" 89 "ExpectedConfigurationDate89" 88 "ExpectedConfigurationDate88" 87 "ExpectedConfigurationDate87" 86 "ExpectedConfigurationDate86" 85 "ExpectedConfigurationDate85" 84 "ExpectedConfigurationDate84" 83 "ExpectedConfigurationDate83" 82 "ExpectedConfigurationDate82" 81 "ExpectedConfigurationDate81" 80 "ExpectedConfigurationDate80" 79 "ExpectedConfigurationDate79" 78 "ExpectedConfigurationDate78" 77 "ExpectedConfigurationDate77" 76 "ExpectedConfigurationDate76" 75 "ExpectedConfigurationDate75" 74 "ExpectedConfigurationDate74" 73 "ExpectedConfigurationDate73" 72 "ExpectedConfigurationDate72" 71 "ExpectedConfigurationDate71" 70 "ExpectedConfigurationDate70" 69 "ExpectedConfigurationDate69" 68 "ExpectedConfigurationDate68" 67 "ExpectedConfigurationDate67" 66 "ExpectedConfigurationDate66" 65 "ExpectedConfigurationDate65" 64 "ExpectedConfigurationDate64" 63 "ExpectedConfigurationDate63" 62 "ExpectedConfigurationDate62" 61 "ExpectedConfigurationDate61" 60 "ExpectedConfigurationDate60" 59 "ExpectedConfigurationDate59" 58 "ExpectedConfigurationDate58" 57 "ExpectedConfigurationDate57" 56 "ExpectedConfigurationDate56" 55 "ExpectedConfigurationDate55" 54 "ExpectedConfigurationDate54" 53 "ExpectedConfigurationDate53" 52 "ExpectedConfigurationDate52" 51 "ExpectedConfigurationDate51" 50 "ExpectedConfigurationDate50" 49 "ExpectedConfigurationDate49" 48 "ExpectedConfigurationDate48" 47 "ExpectedConfigurationDate47" 46 "ExpectedConfigurationDate46" 45 "ExpectedConfigurationDate45" 44 "ExpectedConfigurationDate44" 43 "ExpectedConfigurationDate43" 42 "ExpectedConfigurationDate42" 41 "ExpectedConfigurationDate41" 40 "ExpectedConfigurationDate40" 39 "ExpectedConfigurationDate39" 38 "ExpectedConfigurationDate38" 37 "ExpectedConfigurationDate37" 36 "ExpectedConfigurationDate36" 35 "ExpectedConfigurationDate35" 34 "ExpectedConfigurationDate34" 33 "ExpectedConfigurationDate33" 32 "ExpectedConfigurationDate32" 31 "ExpectedConfigurationDate31" 30 "ExpectedConfigurationDate30" 29 "ExpectedConfigurationDate29" 28 "ExpectedConfigurationDate28" 27 "ExpectedConfigurationDate27" 26 "ExpectedConfigurationDate26" 25 "ExpectedConfigurationDate25" 24 "ExpectedConfigurationDate24" 23 "ExpectedConfigurationDate23" 22 "ExpectedConfigurationDate22" 21 "ExpectedConfigurationDate21" 20 "ExpectedConfigurationDate20" 19 "ExpectedConfigurationDate19" 18 "ExpectedConfigurationDate18" 17 "ExpectedConfigurationDate17" 16 "ExpectedConfigurationDate16" 15 "ExpectedConfigurationDate15" 14 "ExpectedConfigurationDate14" 13 "ExpectedConfigurationDate13" 12 "ExpectedConfigurationDate12" 11 "ExpectedConfigurationDate11" 10 "ExpectedConfigurationDate10" 9 "ExpectedConfigurationDate9" 8 "ExpectedConfigurationDate8" 7 "ExpectedConfigurationDate7" 6 "ExpectedConfigurationDate6" 5 "ExpectedConfigurationDate5" 4 "ExpectedConfigurationDate4" 3 "ExpectedConfigurationDate3" 2 "ExpectedConfigurationDate2" 1 "ExpectedConfigurationDate1" 0 "NrOfObjects" ;
VAL_ 1546 SubIndex_1F25 128 "Configure Slaves128" 127 "Configure Slaves127" 126 "Configure Slaves126" 125 "Configure Slaves125" 124 "Configure Slaves124" 123 "Configure Slaves123" 122 "Configure Slaves122" 121 "Configure Slaves121" 120 "Configure Slaves120" 119 "Configure Slaves119" 118 "Configure Slaves118" 117 "Configure Slaves117" 116 "Configure Slaves116" 115 "Configure Slaves115" 114 "Configure Slaves114" 113 "Configure Slaves113" 112 "Configure Slaves112" 111 "Configure Slaves111" 110 "Configure Slaves110" 109 "Configure Slaves109" 108 "Configure Slaves108" 107 "Configure Slaves107" 106 "Configure Slaves106" 105 "Configure Slaves105" 104 "Configure Slaves104" 103 "Configure Slaves103" 102 "Configure Slaves102" 101 "Configure Slaves101" 100 "Configure Slaves100" 99 "Configure Slaves99" 98 "Configure Slaves98" 97 "Configure Slaves97" 96 "Configure Slaves96" 95 "Configure Slaves95" 94 "Configure Slaves94" 93 "Configure Slaves93" 92 "Configure Slaves92" 91 "Configure Slaves91" 90 "Configure Slaves90" 89 "Configure Slaves89" 88 "Configure Slaves88" 87 "Configure Slaves87" 86 "Configure Slaves86" 85 "Configure Slaves85" 84 "Configure Slaves84" 83 "Configure Slaves83" 82 "Configure Slaves82" 81 "Configure Slaves81" 80 "Configure Slaves80" 79 "Configure Slaves79" 78 "Configure Slaves78" 77 "Configure Slaves77" 76 "Configure Slaves76" 75 "Configure Slaves75" 74 "Configure Slaves74" 73 "Configure Slaves73" 72 "Configure Slaves72" 71 "Configure Slaves71" 70 "Configure Slaves70" 69 "Configure Slaves69" 68 "Configure Slaves68" 67 "Configure Slaves67" 66 "Configure Slaves66" 65 "Configure Slaves65" 64 "Configure Slaves64" 63 "Configure Slaves63" 62 "Configure Slaves62" 61 "Configure Slaves61" 60 "Configure Slaves60" 59 "Configure Slaves59" 58 "Configure Slaves58" 57 "Configure Slaves57" 56 "Configure Slaves56" 55 "Configure Slaves55" 54 "Configure Slaves54" 53 "Configure Slaves53" 52 "Configure Slaves52" 51 "Configure Slaves51" 50 "Configure Slaves50" 49 "Configure Slaves49" 48 "Configure Slaves48" 47 "Configure Slaves47" 46 "Configure Slaves46" 45 "Configure Slaves45" 44 "Configure Slaves44" 43 "Configure Slaves43" 42 "Configure Slaves42" 41 "Configure Slaves41" 40 "Configure Slaves40" 39 "Configure Slaves39" 38 "Configure Slaves38" 37 "Configure Slaves37" 36 "Configure Slaves36" 35 "Configure Slaves35" 34 "Configure Slaves34" 33 "Configure Slaves33" 32 "Configure Slaves32" 31 "Configure Slaves31" 30 "Configure Slaves30" 29 "Configure Slaves29" 28 "Configure Slaves28" 27 "Configure Slaves27" 26 "Configure Slaves26" 25 "Configure Slaves25" 24 "Configure Slaves24" 23 "Configure Slaves23" 22 "Configure Slaves22" 21 "Configure Slaves21" 20 "Configure Slaves20" 19 "Configure Slaves19" 18 "Configure Slaves18" 17 "Configure Slaves17" 16 "Configure Slaves16" 15 "Configure Slaves15" 14 "Configure Slaves14" 13 "Configure Slaves13" 12 "Configure Slaves12" 11 "Configure Slaves11" 10 "Configure Slaves10" 9 "Configure Slaves9" 8 "Configure Slaves8" 7 "Configure Slaves7" 6 "Configure Slaves6" 5 "Configure Slaves5" 4 "Configure Slaves4" 3 "Configure Slaves3" 2 "Configure Slaves2" 1 "Configure Slaves1" 0 "NrOfObjects" ;
VAL_ 1546 SubIndex_1F22 0 "NrOfObjects" ;
VAL_ 1546 SubIndex_13FF 3 "Safety_configuration_checksum_sub3" 2 "Safety_configuration_checksum_sub2" 1 "Safety_Checksum" 0 "Safety_checksum_Number_of_entries" ;
VAL_ 1546 SubIndex_13FE 0 "Configuration_valid" ;
VAL_ 1546 SubIndex_1383 2 "SRDO3_mapping_inv_Byte1" 1 "SRDO3_mapping_Byte1" 0 "SRDO3_Number_of_mapped_objects" ;
VAL_ 1546 SubIndex_1382 2 "SRDO2_mapping_inv_Byte1" 1 "SRDO2_mapping_Byte1" 0 "SRDO2_Number_of_mapped_objects" ;
VAL_ 1546 SubIndex_1381 2 "SRDO1_mapping_inv_Byte1" 1 "SRDO1_mapping_Byte1" 0 "SRDO1_Number_of_mapped_objects" ;
VAL_ 1546 SubIndex_1303 6 "SRDO3_communication_par_COB_ID_2" 5 "SRDO3_communication_par_COB_ID_1" 4 "SRDO3_communication_par_Transmission_type" 3 "SRDO3_communication_srvt_time" 2 "SRDO3_communication_par_sct_time" 1 "SRDO3_communication_par_Information_direction" 0 "Highest sub-index supported" ;
VAL_ 1546 SubIndex_1302 6 "SRDO2_communication_par_COB_ID_2" 5 "SRDO2_communication_par_COB_ID_1" 4 "SRDO2_communication_par_Transmission_type" 3 "SRDO2_communication_srvt_time" 2 "SRDO2_communication_par_sct_time" 1 "SRDO2_communication_par_Information_direction" 0 "Highest sub-index supported" ;
VAL_ 1546 SubIndex_1301 6 "SRDO1_communication_par_COB_ID_2" 5 "SRDO1_communication_par_COB_ID_1" 4 "SRDO1_communication_par_Transmission_type" 3 "SRDO1_communication_srvt_time" 2 "SRDO1_communication_par_sct_time" 1 "SRDO1_communication_par_Information_direction" 0 "Highest sub-index supported" ;
VAL_ 1546 SubIndex_1018 4 "Serial number" 3 "Revision number" 2 "Product Code" 1 "Vendor Id" 0 "Highest sub-index supported" ;
VAL_ 1546 SubIndex_1017 0 "Producer Heartbeat Time" ;
VAL_ 1546 SubIndex_1016 127 "Consumer Heartbeat Time127" 126 "Consumer Heartbeat Time126" 125 "Consumer Heartbeat Time125" 124 "Consumer Heartbeat Time124" 123 "Consumer Heartbeat Time123" 122 "Consumer Heartbeat Time122" 121 "Consumer Heartbeat Time121" 120 "Consumer Heartbeat Time120" 119 "Consumer Heartbeat Time119" 118 "Consumer Heartbeat Time118" 117 "Consumer Heartbeat Time117" 116 "Consumer Heartbeat Time116" 115 "Consumer Heartbeat Time115" 114 "Consumer Heartbeat Time114" 113 "Consumer Heartbeat Time113" 112 "Consumer Heartbeat Time112" 111 "Consumer Heartbeat Time111" 110 "Consumer Heartbeat Time110" 109 "Consumer Heartbeat Time109" 108 "Consumer Heartbeat Time108" 107 "Consumer Heartbeat Time107" 106 "Consumer Heartbeat Time106" 105 "Consumer Heartbeat Time105" 104 "Consumer Heartbeat Time104" 103 "Consumer Heartbeat Time103" 102 "Consumer Heartbeat Time102" 101 "Consumer Heartbeat Time101" 100 "Consumer Heartbeat Time100" 99 "Consumer Heartbeat Time99" 98 "Consumer Heartbeat Time98" 97 "Consumer Heartbeat Time97" 96 "Consumer Heartbeat Time96" 95 "Consumer Heartbeat Time95" 94 "Consumer Heartbeat Time94" 93 "Consumer Heartbeat Time93" 92 "Consumer Heartbeat Time92" 91 "Consumer Heartbeat Time91" 90 "Consumer Heartbeat Time90" 89 "Consumer Heartbeat Time89" 88 "Consumer Heartbeat Time88" 87 "Consumer Heartbeat Time87" 86 "Consumer Heartbeat Time86" 85 "Consumer Heartbeat Time85" 84 "Consumer Heartbeat Time84" 83 "Consumer Heartbeat Time83" 82 "Consumer Heartbeat Time82" 81 "Consumer Heartbeat Time81" 80 "Consumer Heartbeat Time80" 79 "Consumer Heartbeat Time79" 78 "Consumer Heartbeat Time78" 77 "Consumer Heartbeat Time77" 76 "Consumer Heartbeat Time76" 75 "Consumer Heartbeat Time75" 74 "Consumer Heartbeat Time74" 73 "Consumer Heartbeat Time73" 72 "Consumer Heartbeat Time72" 71 "Consumer Heartbeat Time71" 70 "Consumer Heartbeat Time70" 69 "Consumer Heartbeat Time69" 68 "Consumer Heartbeat Time68" 67 "Consumer Heartbeat Time67" 66 "Consumer Heartbeat Time66" 65 "Consumer Heartbeat Time65" 64 "Consumer Heartbeat Time64" 63 "Consumer Heartbeat Time63" 62 "Consumer Heartbeat Time62" 61 "Consumer Heartbeat Time61" 60 "Consumer Heartbeat Time60" 59 "Consumer Heartbeat Time59" 58 "Consumer Heartbeat Time58" 57 "Consumer Heartbeat Time57" 56 "Consumer Heartbeat Time56" 55 "Consumer Heartbeat Time55" 54 "Consumer Heartbeat Time54" 53 "Consumer Heartbeat Time53" 52 "Consumer Heartbeat Time52" 51 "Consumer Heartbeat Time51" 50 "Consumer Heartbeat Time50" 49 "Consumer Heartbeat Time49" 48 "Consumer Heartbeat Time48" 47 "Consumer Heartbeat Time47" 46 "Consumer Heartbeat Time46" 45 "Consumer Heartbeat Time45" 44 "Consumer Heartbeat Time44" 43 "Consumer Heartbeat Time43" 42 "Consumer Heartbeat Time42" 41 "Consumer Heartbeat Time41" 40 "Consumer Heartbeat Time40" 39 "Consumer Heartbeat Time39" 38 "Consumer Heartbeat Time38" 37 "Consumer Heartbeat Time37" 36 "Consumer Heartbeat Time36" 35 "Consumer Heartbeat Time35" 34 "Consumer Heartbeat Time34" 33 "Consumer Heartbeat Time33" 32 "Consumer Heartbeat Time32" 31 "Consumer Heartbeat Time31" 30 "Consumer Heartbeat Time30" 29 "Consumer Heartbeat Time29" 28 "Consumer Heartbeat Time28" 27 "Consumer Heartbeat Time27" 26 "Consumer Heartbeat Time26" 25 "Consumer Heartbeat Time25" 24 "Consumer Heartbeat Time24" 23 "Consumer Heartbeat Time23" 22 "Consumer Heartbeat Time22" 21 "Consumer Heartbeat Time21" 20 "Consumer Heartbeat Time20" 19 "Consumer Heartbeat Time19" 18 "Consumer Heartbeat Time18" 17 "Consumer Heartbeat Time17" 16 "Consumer Heartbeat Time16" 15 "Consumer Heartbeat Time15" 14 "Consumer Heartbeat Time14" 13 "Consumer Heartbeat Time13" 12 "Consumer Heartbeat Time12" 11 "Consumer Heartbeat Time11" 10 "Consumer Heartbeat Time10" 9 "Consumer Heartbeat Time9" 8 "Consumer Heartbeat Time8" 7 "Consumer Heartbeat Time7" 6 "Consumer Heartbeat Time6" 5 "Consumer Heartbeat Time5" 4 "Consumer Heartbeat Time4" 3 "Consumer Heartbeat Time3" 2 "Consumer Heartbeat Time2" 1 "Consumer Heartbeat Time1" 0 "NrOfObjects" ;
VAL_ 1546 SubIndex_1011 1 "Restore all Default Parameters" 0 "Highest sub-index supported" ;
VAL_ 1546 SubIndex_1010 1 "Save all Parameters" 0 "Highest sub-index supported" ;
VAL_ 1546 SubIndex_100D 0 "Life Time Factor" ;
VAL_ 1546 SubIndex_100C 0 "Guard Time" ;
VAL_ 1546 SubIndex_1007 0 "Sync_Window Length" ;
VAL_ 1546 SubIndex_1006 0 "Communication Cycle Period" ;
VAL_ 1546 SubIndex_1005 0 "COB-ID SYNC" ;
VAL_ 1546 SubIndex_1003 16 "Standard error field" 15 "Standard error field" 14 "Standard error field" 13 "Standard error field" 12 "Standard error field" 11 "Standard error field" 10 "Standard error field" 9 "Standard error field" 8 "Standard error field" 7 "Standard error field" 6 "Standard error field" 5 "Standard error field" 4 "Standard error field" 3 "Standard error field" 2 "Standard error field" 1 "Standard error field" 0 "Number of Errors" ;
VAL_ 1546 SubIndex_1001 0 "Error Register" ;
VAL_ 1546 SubIndex_1000 0 "Device Type" ;
VAL_ 1546 Index 42563 "Int16Array" 42562 "Int16Array" 42561 "NetVarArrayInverted" 42560 "NetVarArray" 8073 "BootTime" 8072 "SerialNumber" 8071 "RevisionNumber" 8070 "ProductCode" 8069 "VendorIdentification" 8068 "DeviceTypeIdentification" 8067 "RequestGuarding" 8066 "RequestNMT" 8065 "Slave Assignment" 8064 "NMTStartup" 7975 "ExpectedConfigurationTime" 7974 "ExpectedConfigurationDate" 7973 "Configure Slaves" 7970 "Concise DCF" 5119 "Safety_configuration_checksum" 5118 "Configuration_valid" 4995 "Safety_SRDO3_mapping_parameter" 4994 "Safety_SRDO2_mapping_parameter" 4993 "Safety_SRDO1_mapping_parameter" 4867 "Safety_SRDO3_communication_parameter" 4866 "Safety_SRDO2_communication_parameter" 4865 "Safety_SRDO1_communication_parameter" 4120 "Identity Object" 4119 "Producer Heartbeat Time" 4118 "Consumer Heartbeat Time" 4113 "Restore Default Parameters" 4112 "Store Parameter Field" 4109 "Life Time Factor" 4108 "Guard Time" 4103 "Sync_Window Length" 4102 "Communication Cycle Period" 4101 "COB-ID SYNC" 4099 "Pre-defined Error Field" 4097 "Error Register" 4096 "Device Type" ;
VAL_ 1546 TransferType 1 "Expedited transfer" 0 "Normal transfer" ;
VAL_ 1546 SizeIndicator 1 "Size is indicated" 0 "Size is not indicated" ;
VAL_ 1546 CCS 2 "Upload" 1 "Download" ;
VAL_ 138 ErrorCode 33360 "RPDO timeout" 33344 "Unexpected SYNC data length" 33328 "DAM MPDO not processed, destination object not available" 33312 "PDO length exceeded" 33296 "PDO not processed due to length error" 33104 "Transmit COB-ID collision" 33088 "Recovered from bus off state" 33072 "Life guard error or heartbeat error" 33056 "CAN in error passive mode" 33040 "CAN overrun (objects lost)" ;
VAL_ 0 Node_ID 28 "Sensor_3_ID28" 27 "Sensor_2_ID27" 23 "Sensor_1_ID23" 10 "Display_ID10" 0 "All" ;
VAL_ 0 CS 130 "Reset Communication" 129 "Reset Node" 128 "Enter Pre-Operational" 2 "Stop" 1 "Start" ;
VAL_ 2021 LSS_TableIndex 8 "10" 7 "20" 6 "50" 5 "100" 4 "125" 3 "250" 2 "500" 1 "800" 0 "1000" ;
VAL_ 2021 LSS_TableSelector 0 "Std_CiA_Table" ;
VAL_ 2021 LSS_Mode 1 "Configuration" 0 "Operation" ;
VAL_ 2021 LSS_M_CS 94 "InquireNodeID" 93 "InquireSerial" 92 "InquireRevision" 91 "InquireProduct" 90 "InquireVendor" 81 "FastScan" 23 "StoreConfiguration" 21 "ActivateBitTiming" 19 "ConfigureBitTiming" 17 "ConfigureNodeID" 76 "IdentifyNonConfSlave" 75 "IdentifySerialHigh" 74 "IdentifySerialLow" 73 "IdentifyRevisionHigh" 72 "IdentifyRevisionLow" 71 "IdentifyProduct" 70 "IdentifyVendor" 67 "SwitchModeSelectSerial" 66 "SwitchModeSelectRevision" 65 "SwitchModeSelectProduct" 64 "SwitchModeSelectVendor" 4 "SwitchModeGlobal" ;
VAL_ 2020 LSS_StoreCfg_ErrCode 255 "Impl_spec_error" 2 "Storage_media_access_error" 1 "Not_supported" 0 "Success" ;
VAL_ 2020 LSS_CfgBitTim_ErrCode 255 "Impl_spec_error" 1 "Not_supported" 0 "Success" ;
VAL_ 2020 LSS_CfgNodeID_ErrCode 255 "Impl_spec_error" 1 "NodeID_Out_Of_Range" 0 "Success" ;
VAL_ 2020 LSS_S_CS 94 "InquireNodeID" 93 "InquireSerial" 92 "InquireRevision" 91 "InquireProduct" 90 "InquireVendor" 76 "IdentifyNonConfSlave" 79 "IdentifySlave" 23 "StoreConfiguration" 19 "ConfigureBitTiming" 17 "ConfigureNodeID" 68 "SwitchModeSelectConfirm" ;
SG_MUL_VAL_ 1546 ExpectedConfigurationTime11_0002 SubIndex_1F27 117-117;
SG_MUL_VAL_ 1546 ExpectedConfigurationTime11_0003 SubIndex_1F27 116-116;
SG_MUL_VAL_ 1546 ExpectedConfigurationTime11_0004 SubIndex_1F27 115-115;
SG_MUL_VAL_ 1546 ExpectedConfigurationTime11_0005 SubIndex_1F27 114-114;
SG_MUL_VAL_ 1546 ExpectedConfigurationTime11_0006 SubIndex_1F27 113-113;
SG_MUL_VAL_ 1546 ExpectedConfigurationTime11_0007 SubIndex_1F27 112-112;
SG_MUL_VAL_ 1546 ExpectedConfigurationTime11_0008 SubIndex_1F27 111-111;
SG_MUL_VAL_ 1546 ExpectedConfigurationTime11_0009 SubIndex_1F27 110-110;
SG_MUL_VAL_ 1546 ExpectedConfigurationTime10_0000 SubIndex_1F27 109-109;
SG_MUL_VAL_ 1546 ExpectedConfigurationTime10_0001 SubIndex_1F27 108-108;
SG_MUL_VAL_ 1546 ExpectedConfigurationTime10_0002 SubIndex_1F27 107-107;
SG_MUL_VAL_ 1546 ExpectedConfigurationTime10_0003 SubIndex_1F27 106-106;
SG_MUL_VAL_ 1546 ExpectedConfigurationTime10_0004 SubIndex_1F27 105-105;
SG_MUL_VAL_ 1546 ExpectedConfigurationTime10_0005 SubIndex_1F27 104-104;
SG_MUL_VAL_ 1546 ExpectedConfigurationTime10_0006 SubIndex_1F27 103-103;
SG_MUL_VAL_ 1546 ExpectedConfigurationTime10_0007 SubIndex_1F27 102-102;
SG_MUL_VAL_ 1546 ExpectedConfigurationTime10_0008 SubIndex_1F27 101-101;
SG_MUL_VAL_ 1546 ExpectedConfigurationTime10_0009 SubIndex_1F27 100-100;
SG_MUL_VAL_ 1546 ExpectedConfigurationTime99_0000 SubIndex_1F27 99-99;
SG_MUL_VAL_ 1546 ExpectedConfigurationTime98_0000 SubIndex_1F27 98-98;
SG_MUL_VAL_ 1546 ExpectedConfigurationTime97_0000 SubIndex_1F27 97-97;
SG_MUL_VAL_ 1546 ExpectedConfigurationTime96_0000 SubIndex_1F27 96-96;
SG_MUL_VAL_ 1546 ExpectedConfigurationTime95_0000 SubIndex_1F27 95-95;
SG_MUL_VAL_ 1546 ExpectedConfigurationTime94_0000 SubIndex_1F27 94-94;
SG_MUL_VAL_ 1546 ExpectedConfigurationTime93_0000 SubIndex_1F27 93-93;
SG_MUL_VAL_ 1546 ExpectedConfigurationTime92_0000 SubIndex_1F27 92-92;
SG_MUL_VAL_ 1546 ExpectedConfigurationTime91_0000 SubIndex_1F27 91-91;
SG_MUL_VAL_ 1546 ExpectedConfigurationTime90_0000 SubIndex_1F27 90-90;
SG_MUL_VAL_ 1546 ExpectedConfigurationTime89_0000 SubIndex_1F27 89-89;
SG_MUL_VAL_ 1546 ExpectedConfigurationTime88_0000 SubIndex_1F27 88-88;
SG_MUL_VAL_ 1546 ExpectedConfigurationTime87_0000 SubIndex_1F27 87-87;
SG_MUL_VAL_ 1546 ExpectedConfigurationTime86_0000 SubIndex_1F27 86-86;
SG_MUL_VAL_ 1546 ExpectedConfigurationTime85_0000 SubIndex_1F27 85-85;
SG_MUL_VAL_ 1546 ExpectedConfigurationTime84_0000 SubIndex_1F27 84-84;
SG_MUL_VAL_ 1546 ExpectedConfigurationTime83_0000 SubIndex_1F27 83-83;
SG_MUL_VAL_ 1546 ExpectedConfigurationTime82_0000 SubIndex_1F27 82-82;
SG_MUL_VAL_ 1546 ExpectedConfigurationTime81_0000 SubIndex_1F27 81-81;
SG_MUL_VAL_ 1546 ExpectedConfigurationTime80_0000 SubIndex_1F27 80-80;
SG_MUL_VAL_ 1546 ExpectedConfigurationTime79_0000 SubIndex_1F27 79-79;
SG_MUL_VAL_ 1546 ExpectedConfigurationTime78_0000 SubIndex_1F27 78-78;
SG_MUL_VAL_ 1546 ExpectedConfigurationTime77_0000 SubIndex_1F27 77-77;
SG_MUL_VAL_ 1546 ExpectedConfigurationTime76_0000 SubIndex_1F27 76-76;
SG_MUL_VAL_ 1546 ExpectedConfigurationTime75_0000 SubIndex_1F27 75-75;
SG_MUL_VAL_ 1546 ExpectedConfigurationTime74_0000 SubIndex_1F27 74-74;
SG_MUL_VAL_ 1546 ExpectedConfigurationTime73_0000 SubIndex_1F27 73-73;
SG_MUL_VAL_ 1546 ExpectedConfigurationTime72_0000 SubIndex_1F27 72-72;
SG_MUL_VAL_ 1546 ExpectedConfigurationTime71_0000 SubIndex_1F27 71-71;
SG_MUL_VAL_ 1546 ExpectedConfigurationTime70_0000 SubIndex_1F27 70-70;
SG_MUL_VAL_ 1546 ExpectedConfigurationTime69_0000 SubIndex_1F27 69-69;
SG_MUL_VAL_ 1546 ExpectedConfigurationTime68_0000 SubIndex_1F27 68-68;
SG_MUL_VAL_ 1546 ExpectedConfigurationTime67_0000 SubIndex_1F27 67-67;
SG_MUL_VAL_ 1546 ExpectedConfigurationTime66_0000 SubIndex_1F27 66-66;
SG_MUL_VAL_ 1546 ExpectedConfigurationTime65_0000 SubIndex_1F27 65-65;
SG_MUL_VAL_ 1546 ExpectedConfigurationTime64_0000 SubIndex_1F27 64-64;
SG_MUL_VAL_ 1546 ExpectedConfigurationTime63_0000 SubIndex_1F27 63-63;
SG_MUL_VAL_ 1546 ExpectedConfigurationTime62_0000 SubIndex_1F27 62-62;
SG_MUL_VAL_ 1546 ExpectedConfigurationTime61_0000 SubIndex_1F27 61-61;
SG_MUL_VAL_ 1546 ExpectedConfigurationTime60_0000 SubIndex_1F27 60-60;
SG_MUL_VAL_ 1546 ExpectedConfigurationTime59_0000 SubIndex_1F27 59-59;
SG_MUL_VAL_ 1546 ExpectedConfigurationTime58_0000 SubIndex_1F27 58-58;
SG_MUL_VAL_ 1546 ExpectedConfigurationTime57_0000 SubIndex_1F27 57-57;
SG_MUL_VAL_ 1546 ExpectedConfigurationTime56_0000 SubIndex_1F27 56-56;
SG_MUL_VAL_ 1546 ExpectedConfigurationTime55_0000 SubIndex_1F27 55-55;
SG_MUL_VAL_ 1546 ExpectedConfigurationTime54_0000 SubIndex_1F27 54-54;
SG_MUL_VAL_ 1546 ExpectedConfigurationTime53_0000 SubIndex_1F27 53-53;
SG_MUL_VAL_ 1546 ExpectedConfigurationTime52_0000 SubIndex_1F27 52-52;
SG_MUL_VAL_ 1546 ExpectedConfigurationTime51_0000 SubIndex_1F27 51-51;
SG_MUL_VAL_ 1546 ExpectedConfigurationTime50_0000 SubIndex_1F27 50-50;
SG_MUL_VAL_ 1546 ExpectedConfigurationTime49_0000 SubIndex_1F27 49-49;
SG_MUL_VAL_ 1546 ExpectedConfigurationTime48_0000 SubIndex_1F27 48-48;
SG_MUL_VAL_ 1546 ExpectedConfigurationTime47_0000 SubIndex_1F27 47-47;
SG_MUL_VAL_ 1546 ExpectedConfigurationTime46_0000 SubIndex_1F27 46-46;
SG_MUL_VAL_ 1546 ExpectedConfigurationTime45_0000 SubIndex_1F27 45-45;
SG_MUL_VAL_ 1546 ExpectedConfigurationTime44_0000 SubIndex_1F27 44-44;
SG_MUL_VAL_ 1546 ExpectedConfigurationTime43_0000 SubIndex_1F27 43-43;
SG_MUL_VAL_ 1546 ExpectedConfigurationTime42_0000 SubIndex_1F27 42-42;
SG_MUL_VAL_ 1546 ExpectedConfigurationTime41_0000 SubIndex_1F27 41-41;
SG_MUL_VAL_ 1546 ExpectedConfigurationTime40_0000 SubIndex_1F27 40-40;
SG_MUL_VAL_ 1546 ExpectedConfigurationTime39_0000 SubIndex_1F27 39-39;
SG_MUL_VAL_ 1546 ExpectedConfigurationTime38_0000 SubIndex_1F27 38-38;
SG_MUL_VAL_ 1546 ExpectedConfigurationTime37_0000 SubIndex_1F27 37-37;
SG_MUL_VAL_ 1546 ExpectedConfigurationTime36_0000 SubIndex_1F27 36-36;
SG_MUL_VAL_ 1546 ExpectedConfigurationTime35_0000 SubIndex_1F27 35-35;
SG_MUL_VAL_ 1546 ExpectedConfigurationTime34_0000 SubIndex_1F27 34-34;
SG_MUL_VAL_ 1546 ExpectedConfigurationTime33_0000 SubIndex_1F27 33-33;
SG_MUL_VAL_ 1546 ExpectedConfigurationTime32_0000 SubIndex_1F27 32-32;
SG_MUL_VAL_ 1546 ExpectedConfigurationTime31_0000 SubIndex_1F27 31-31;
SG_MUL_VAL_ 1546 ExpectedConfigurationTime30_0000 SubIndex_1F27 30-30;
SG_MUL_VAL_ 1546 ExpectedConfigurationTime29_0000 SubIndex_1F27 29-29;
SG_MUL_VAL_ 1546 ExpectedConfigurationTime28_0000 SubIndex_1F27 28-28;
SG_MUL_VAL_ 1546 ExpectedConfigurationTime27_0000 SubIndex_1F27 27-27;
SG_MUL_VAL_ 1546 ExpectedConfigurationTime26_0000 SubIndex_1F27 26-26;
SG_MUL_VAL_ 1546 ExpectedConfigurationTime25_0000 SubIndex_1F27 25-25;
SG_MUL_VAL_ 1546 ExpectedConfigurationTime24_0000 SubIndex_1F27 24-24;
SG_MUL_VAL_ 1546 ExpectedConfigurationTime23_0000 SubIndex_1F27 23-23;
SG_MUL_VAL_ 1546 ExpectedConfigurationTime22_0000 SubIndex_1F27 22-22;
SG_MUL_VAL_ 1546 ExpectedConfigurationTime21_0000 SubIndex_1F27 21-21;
SG_MUL_VAL_ 1546 ExpectedConfigurationTime20_0000 SubIndex_1F27 20-20;
SG_MUL_VAL_ 1546 ExpectedConfigurationTime19_0000 SubIndex_1F27 19-19;
SG_MUL_VAL_ 1546 ExpectedConfigurationTime18_0000 SubIndex_1F27 18-18;
SG_MUL_VAL_ 1546 ExpectedConfigurationTime17_0000 SubIndex_1F27 17-17;
SG_MUL_VAL_ 1546 ExpectedConfigurationTime16_0000 SubIndex_1F27 16-16;
SG_MUL_VAL_ 1546 ExpectedConfigurationTime15_0000 SubIndex_1F27 15-15;
SG_MUL_VAL_ 1546 ExpectedConfigurationTime14_0000 SubIndex_1F27 14-14;
SG_MUL_VAL_ 1546 ExpectedConfigurationTime13_0000 SubIndex_1F27 13-13;
SG_MUL_VAL_ 1546 ExpectedConfigurationTime12_0008 SubIndex_1F27 12-12;
SG_MUL_VAL_ 1546 ExpectedConfigurationTime11_0010 SubIndex_1F27 11-11;
SG_MUL_VAL_ 1546 ExpectedConfigurationTime10_0010 SubIndex_1F27 10-10;
SG_MUL_VAL_ 1546 ExpectedConfigurationTime9__0000 SubIndex_1F27 9-9;
SG_MUL_VAL_ 1546 ExpectedConfigurationTime8__0000 SubIndex_1F27 8-8;
SG_MUL_VAL_ 1546 ExpectedConfigurationTime7__0000 SubIndex_1F27 7-7;
SG_MUL_VAL_ 1546 ExpectedConfigurationTime6__0000 SubIndex_1F27 6-6;
SG_MUL_VAL_ 1546 ExpectedConfigurationTime5__0000 SubIndex_1F27 5-5;
SG_MUL_VAL_ 1546 ExpectedConfigurationTime4__0000 SubIndex_1F27 4-4;
SG_MUL_VAL_ 1546 ExpectedConfigurationTime3__0000 SubIndex_1F27 3-3;
SG_MUL_VAL_ 1546 ExpectedConfigurationTime2__0000 SubIndex_1F27 2-2;
SG_MUL_VAL_ 1546 ExpectedConfigurationTime1__0000 SubIndex_1F27 1-1;
SG_MUL_VAL_ 1546 NrOfObjects_1F27_00 SubIndex_1F27 0-0;
SG_MUL_VAL_ 1546 SubIndex_1F27 Index 7975-7975;
SG_MUL_VAL_ 1546 ExpectedConfigurationDate12_0000 SubIndex_1F26 127-127;
SG_MUL_VAL_ 1546 ExpectedConfigurationDate12_0001 SubIndex_1F26 126-126;
SG_MUL_VAL_ 1546 ExpectedConfigurationDate12_0002 SubIndex_1F26 125-125;
SG_MUL_VAL_ 1546 ExpectedConfigurationDate12_0003 SubIndex_1F26 124-124;
SG_MUL_VAL_ 1546 ExpectedConfigurationDate12_0004 SubIndex_1F26 123-123;
SG_MUL_VAL_ 1546 ExpectedConfigurationDate12_0005 SubIndex_1F26 122-122;
SG_MUL_VAL_ 1546 ExpectedConfigurationDate12_0006 SubIndex_1F26 121-121;
SG_MUL_VAL_ 1546 ExpectedConfigurationDate12_0007 SubIndex_1F26 120-120;
SG_MUL_VAL_ 1546 ExpectedConfigurationDate11_0000 SubIndex_1F26 119-119;
SG_MUL_VAL_ 1546 ExpectedConfigurationDate11_0001 SubIndex_1F26 118-118;
SG_MUL_VAL_ 1546 ExpectedConfigurationDate11_0002 SubIndex_1F26 117-117;
SG_MUL_VAL_ 1546 ExpectedConfigurationDate11_0003 SubIndex_1F26 116-116;
SG_MUL_VAL_ 1546 ExpectedConfigurationDate11_0004 SubIndex_1F26 115-115;
SG_MUL_VAL_ 1546 ExpectedConfigurationDate11_0005 SubIndex_1F26 114-114;
SG_MUL_VAL_ 1546 ExpectedConfigurationDate11_0006 SubIndex_1F26 113-113;
SG_MUL_VAL_ 1546 ExpectedConfigurationDate11_0007 SubIndex_1F26 112-112;
SG_MUL_VAL_ 1546 ExpectedConfigurationDate11_0008 SubIndex_1F26 111-111;
SG_MUL_VAL_ 1546 ExpectedConfigurationDate11_0009 SubIndex_1F26 110-110;
SG_MUL_VAL_ 1546 ExpectedConfigurationDate10_0000 SubIndex_1F26 109-109;
SG_MUL_VAL_ 1546 ExpectedConfigurationDate10_0001 SubIndex_1F26 108-108;
SG_MUL_VAL_ 1546 ExpectedConfigurationDate10_0002 SubIndex_1F26 107-107;
SG_MUL_VAL_ 1546 ExpectedConfigurationDate10_0003 SubIndex_1F26 106-106;
SG_MUL_VAL_ 1546 ExpectedConfigurationDate10_0004 SubIndex_1F26 105-105;
SG_MUL_VAL_ 1546 ExpectedConfigurationDate10_0005 SubIndex_1F26 104-104;
SG_MUL_VAL_ 1546 ExpectedConfigurationDate10_0006 SubIndex_1F26 103-103;
SG_MUL_VAL_ 1546 ExpectedConfigurationDate10_0007 SubIndex_1F26 102-102;
SG_MUL_VAL_ 1546 ExpectedConfigurationDate10_0008 SubIndex_1F26 101-101;
SG_MUL_VAL_ 1546 ExpectedConfigurationDate10_0009 SubIndex_1F26 100-100;
SG_MUL_VAL_ 1546 ExpectedConfigurationDate99_0000 SubIndex_1F26 99-99;
SG_MUL_VAL_ 1546 ExpectedConfigurationDate98_0000 SubIndex_1F26 98-98;
SG_MUL_VAL_ 1546 ExpectedConfigurationDate97_0000 SubIndex_1F26 97-97;
SG_MUL_VAL_ 1546 ExpectedConfigurationDate96_0000 SubIndex_1F26 96-96;
SG_MUL_VAL_ 1546 ExpectedConfigurationDate95_0000 SubIndex_1F26 95-95;
SG_MUL_VAL_ 1546 ExpectedConfigurationDate94_0000 SubIndex_1F26 94-94;
SG_MUL_VAL_ 1546 ExpectedConfigurationDate93_0000 SubIndex_1F26 93-93;
SG_MUL_VAL_ 1546 ExpectedConfigurationDate92_0000 SubIndex_1F26 92-92;
SG_MUL_VAL_ 1546 ExpectedConfigurationDate91_0000 SubIndex_1F26 91-91;
SG_MUL_VAL_ 1546 ExpectedConfigurationDate90_0000 SubIndex_1F26 90-90;
SG_MUL_VAL_ 1546 ExpectedConfigurationDate89_0000 SubIndex_1F26 89-89;
SG_MUL_VAL_ 1546 ExpectedConfigurationDate88_0000 SubIndex_1F26 88-88;
SG_MUL_VAL_ 1546 ExpectedConfigurationDate87_0000 SubIndex_1F26 87-87;
SG_MUL_VAL_ 1546 ExpectedConfigurationDate86_0000 SubIndex_1F26 86-86;
SG_MUL_VAL_ 1546 ExpectedConfigurationDate85_0000 SubIndex_1F26 85-85;
SG_MUL_VAL_ 1546 ExpectedConfigurationDate84_0000 SubIndex_1F26 84-84;
SG_MUL_VAL_ 1546 ExpectedConfigurationDate83_0000 SubIndex_1F26 83-83;
SG_MUL_VAL_ 1546 ExpectedConfigurationDate82_0000 SubIndex_1F26 82-82;
SG_MUL_VAL_ 1546 ExpectedConfigurationDate81_0000 SubIndex_1F26 81-81;
SG_MUL_VAL_ 1546 ExpectedConfigurationDate80_0000 SubIndex_1F26 80-80;
SG_MUL_VAL_ 1546 ExpectedConfigurationDate79_0000 SubIndex_1F26 79-79;
SG_MUL_VAL_ 1546 ExpectedConfigurationDate78_0000 SubIndex_1F26 78-78;
SG_MUL_VAL_ 1546 ExpectedConfigurationDate77_0000 SubIndex_1F26 77-77;
SG_MUL_VAL_ 1546 ExpectedConfigurationDate76_0000 SubIndex_1F26 76-76;
SG_MUL_VAL_ 1546 ExpectedConfigurationDate75_0000 SubIndex_1F26 75-75;
SG_MUL_VAL_ 1546 ExpectedConfigurationDate74_0000 SubIndex_1F26 74-74;
SG_MUL_VAL_ 1546 ExpectedConfigurationDate73_0000 SubIndex_1F26 73-73;
SG_MUL_VAL_ 1546 ExpectedConfigurationDate72_0000 SubIndex_1F26 72-72;
SG_MUL_VAL_ 1546 ExpectedConfigurationDate71_0000 SubIndex_1F26 71-71;
SG_MUL_VAL_ 1546 ExpectedConfigurationDate70_0000 SubIndex_1F26 70-70;
SG_MUL_VAL_ 1546 ExpectedConfigurationDate69_0000 SubIndex_1F26 69-69;
SG_MUL_VAL_ 1546 ExpectedConfigurationDate68_0000 SubIndex_1F26 68-68;
SG_MUL_VAL_ 1546 ExpectedConfigurationDate67_0000 SubIndex_1F26 67-67;
SG_MUL_VAL_ 1546 ExpectedConfigurationDate66_0000 SubIndex_1F26 66-66;
SG_MUL_VAL_ 1546 ExpectedConfigurationDate65_0000 SubIndex_1F26 65-65;
SG_MUL_VAL_ 1546 ExpectedConfigurationDate64_0000 SubIndex_1F26 64-64;
SG_MUL_VAL_ 1546 ExpectedConfigurationDate63_0000 SubIndex_1F26 63-63;
SG_MUL_VAL_ 1546 ExpectedConfigurationDate62_0000 SubIndex_1F26 62-62;
SG_MUL_VAL_ 1546 ExpectedConfigurationDate61_0000 SubIndex_1F26 61-61;
SG_MUL_VAL_ 1546 ExpectedConfigurationDate60_0000 SubIndex_1F26 60-60;
SG_MUL_VAL_ 1546 ExpectedConfigurationDate59_0000 SubIndex_1F26 59-59;
SG_MUL_VAL_ 1546 ExpectedConfigurationDate58_0000 SubIndex_1F26 58-58;
SG_MUL_VAL_ 1546 ExpectedConfigurationDate57_0000 SubIndex_1F26 57-57;
SG_MUL_VAL_ 1546 ExpectedConfigurationDate56_0000 SubIndex_1F26 56-56;
SG_MUL_VAL_ 1546 ExpectedConfigurationDate55_0000 SubIndex_1F26 55-55;
SG_MUL_VAL_ 1546 ExpectedConfigurationDate54_0000 SubIndex_1F26 54-54;
SG_MUL_VAL_ 1546 ExpectedConfigurationDate53_0000 SubIndex_1F26 53-53;
SG_MUL_VAL_ 1546 ExpectedConfigurationDate52_0000 SubIndex_1F26 52-52;
SG_MUL_VAL_ 1546 ExpectedConfigurationDate51_0000 SubIndex_1F26 51-51;
SG_MUL_VAL_ 1546 ExpectedConfigurationDate50_0000 SubIndex_1F26 50-50;
SG_MUL_VAL_ 1546 ExpectedConfigurationDate49_0000 SubIndex_1F26 49-49;
SG_MUL_VAL_ 1546 ExpectedConfigurationDate48_0000 SubIndex_1F26 48-48;
SG_MUL_VAL_ 1546 ExpectedConfigurationDate47_0000 SubIndex_1F26 47-47;
SG_MUL_VAL_ 1546 ExpectedConfigurationDate46_0000 SubIndex_1F26 46-46;
SG_MUL_VAL_ 1546 ExpectedConfigurationDate45_0000 SubIndex_1F26 45-45;
SG_MUL_VAL_ 1546 ExpectedConfigurationDate44_0000 SubIndex_1F26 44-44;
SG_MUL_VAL_ 1546 ExpectedConfigurationDate43_0000 SubIndex_1F26 43-43;
SG_MUL_VAL_ 1546 ExpectedConfigurationDate42_0000 SubIndex_1F26 42-42;
SG_MUL_VAL_ 1546 ExpectedConfigurationDate41_0000 SubIndex_1F26 41-41;
SG_MUL_VAL_ 1546 ExpectedConfigurationDate40_0000 SubIndex_1F26 40-40;
SG_MUL_VAL_ 1546 ExpectedConfigurationDate39_0000 SubIndex_1F26 39-39;
SG_MUL_VAL_ 1546 ExpectedConfigurationDate38_0000 SubIndex_1F26 38-38;
SG_MUL_VAL_ 1546 ExpectedConfigurationDate37_0000 SubIndex_1F26 37-37;
SG_MUL_VAL_ 1546 ExpectedConfigurationDate36_0000 SubIndex_1F26 36-36;
SG_MUL_VAL_ 1546 ExpectedConfigurationDate35_0000 SubIndex_1F26 35-35;
SG_MUL_VAL_ 1546 ExpectedConfigurationDate34_0000 SubIndex_1F26 34-34;
SG_MUL_VAL_ 1546 ExpectedConfigurationDate33_0000 SubIndex_1F26 33-33;
SG_MUL_VAL_ 1546 ExpectedConfigurationDate32_0000 SubIndex_1F26 32-32;
SG_MUL_VAL_ 1546 ExpectedConfigurationDate31_0000 SubIndex_1F26 31-31;
SG_MUL_VAL_ 1546 ExpectedConfigurationDate30_0000 SubIndex_1F26 30-30;
SG_MUL_VAL_ 1546 ExpectedConfigurationDate29_0000 SubIndex_1F26 29-29;
SG_MUL_VAL_ 1546 ExpectedConfigurationDate28_0000 SubIndex_1F26 28-28;
SG_MUL_VAL_ 1546 ExpectedConfigurationDate27_0000 SubIndex_1F26 27-27;
SG_MUL_VAL_ 1546 ExpectedConfigurationDate26_0000 SubIndex_1F26 26-26;
SG_MUL_VAL_ 1546 ExpectedConfigurationDate25_0000 SubIndex_1F26 25-25;
SG_MUL_VAL_ 1546 ExpectedConfigurationDate24_0000 SubIndex_1F26 24-24;
SG_MUL_VAL_ 1546 ExpectedConfigurationDate23_0000 SubIndex_1F26 23-23;
SG_MUL_VAL_ 1546 ExpectedConfigurationDate22_0000 SubIndex_1F26 22-22;
SG_MUL_VAL_ 1546 ExpectedConfigurationDate21_0000 SubIndex_1F26 21-21;
SG_MUL_VAL_ 1546 ExpectedConfigurationDate20_0000 SubIndex_1F26 20-20;
SG_MUL_VAL_ 1546 ExpectedConfigurationDate19_0000 SubIndex_1F26 19-19;
SG_MUL_VAL_ 1546 ExpectedConfigurationDate18_0000 SubIndex_1F26 18-18;
SG_MUL_VAL_ 1546 ExpectedConfigurationDate17_0000 SubIndex_1F26 17-17;
SG_MUL_VAL_ 1546 ExpectedConfigurationDate16_0000 SubIndex_1F26 16-16;
SG_MUL_VAL_ 1546 ExpectedConfigurationDate15_0000 SubIndex_1F26 15-15;
SG_MUL_VAL_ 1546 ExpectedConfigurationDate14_0000 SubIndex_1F26 14-14;
SG_MUL_VAL_ 1546 ExpectedConfigurationDate13_0000 SubIndex_1F26 13-13;
SG_MUL_VAL_ 1546 ExpectedConfigurationDate12_0008 SubIndex_1F26 12-12;
SG_MUL_VAL_ 1546 ExpectedConfigurationDate11_0010 SubIndex_1F26 11-11;
SG_MUL_VAL_ 1546 ExpectedConfigurationDate10_0010 SubIndex_1F26 10-10;
SG_MUL_VAL_ 1546 ExpectedConfigurationDate9__0000 SubIndex_1F26 9-9;
SG_MUL_VAL_ 1546 ExpectedConfigurationDate8__0000 SubIndex_1F26 8-8;
SG_MUL_VAL_ 1546 ExpectedConfigurationDate7__0000 SubIndex_1F26 7-7;
SG_MUL_VAL_ 1546 ExpectedConfigurationDate6__0000 SubIndex_1F26 6-6;
SG_MUL_VAL_ 1546 ExpectedConfigurationDate5__0000 SubIndex_1F26 5-5;
SG_MUL_VAL_ 1546 ExpectedConfigurationDate4__0000 SubIndex_1F26 4-4;
SG_MUL_VAL_ 1546 ExpectedConfigurationDate3__0000 SubIndex_1F26 3-3;
SG_MUL_VAL_ 1546 ExpectedConfigurationDate2__0000 SubIndex_1F26 2-2;
SG_MUL_VAL_ 1546 ExpectedConfigurationDate1__0000 SubIndex_1F26 1-1;
SG_MUL_VAL_ 1546 NrOfObjects_1F26_00 SubIndex_1F26 0-0;
SG_MUL_VAL_ 1546 SubIndex_1F26 Index 7974-7974;
SG_MUL_VAL_ 1546 Configure_Slaves128_1F25_80 SubIndex_1F25 128-128;
SG_MUL_VAL_ 1546 Configure_Slaves127_1F25_7F SubIndex_1F25 127-127;
SG_MUL_VAL_ 1546 Configure_Slaves126_1F25_7E SubIndex_1F25 126-126;
SG_MUL_VAL_ 1546 Configure_Slaves125_1F25_7D SubIndex_1F25 125-125;
SG_MUL_VAL_ 1546 Configure_Slaves124_1F25_7C SubIndex_1F25 124-124;
SG_MUL_VAL_ 1546 Configure_Slaves123_1F25_7B SubIndex_1F25 123-123;
SG_MUL_VAL_ 1546 Configure_Slaves122_1F25_7A SubIndex_1F25 122-122;
SG_MUL_VAL_ 1546 Configure_Slaves121_1F25_79 SubIndex_1F25 121-121;
SG_MUL_VAL_ 1546 Configure_Slaves120_1F25_78 SubIndex_1F25 120-120;
SG_MUL_VAL_ 1546 Configure_Slaves119_1F25_77 SubIndex_1F25 119-119;
SG_MUL_VAL_ 1546 Configure_Slaves118_1F25_76 SubIndex_1F25 118-118;
SG_MUL_VAL_ 1546 Configure_Slaves117_1F25_75 SubIndex_1F25 117-117;
SG_MUL_VAL_ 1546 Configure_Slaves116_1F25_74 SubIndex_1F25 116-116;
SG_MUL_VAL_ 1546 Configure_Slaves115_1F25_73 SubIndex_1F25 115-115;
SG_MUL_VAL_ 1546 Configure_Slaves114_1F25_72 SubIndex_1F25 114-114;
SG_MUL_VAL_ 1546 Configure_Slaves113_1F25_71 SubIndex_1F25 113-113;
SG_MUL_VAL_ 1546 Configure_Slaves112_1F25_70 SubIndex_1F25 112-112;
SG_MUL_VAL_ 1546 Configure_Slaves111_1F25_6F SubIndex_1F25 111-111;
SG_MUL_VAL_ 1546 Configure_Slaves110_1F25_6E SubIndex_1F25 110-110;
SG_MUL_VAL_ 1546 Configure_Slaves109_1F25_6D SubIndex_1F25 109-109;
SG_MUL_VAL_ 1546 Configure_Slaves108_1F25_6C SubIndex_1F25 108-108;
SG_MUL_VAL_ 1546 Configure_Slaves107_1F25_6B SubIndex_1F25 107-107;
SG_MUL_VAL_ 1546 Configure_Slaves106_1F25_6A SubIndex_1F25 106-106;
SG_MUL_VAL_ 1546 Configure_Slaves105_1F25_69 SubIndex_1F25 105-105;
SG_MUL_VAL_ 1546 Configure_Slaves104_1F25_68 SubIndex_1F25 104-104;
SG_MUL_VAL_ 1546 Configure_Slaves103_1F25_67 SubIndex_1F25 103-103;
SG_MUL_VAL_ 1546 Configure_Slaves102_1F25_66 SubIndex_1F25 102-102;
SG_MUL_VAL_ 1546 Configure_Slaves101_1F25_65 SubIndex_1F25 101-101;
SG_MUL_VAL_ 1546 Configure_Slaves100_1F25_64 SubIndex_1F25 100-100;
SG_MUL_VAL_ 1546 Configure_Slaves99_1F25_63 SubIndex_1F25 99-99;
SG_MUL_VAL_ 1546 Configure_Slaves98_1F25_62 SubIndex_1F25 98-98;
SG_MUL_VAL_ 1546 Configure_Slaves97_1F25_61 SubIndex_1F25 97-97;
SG_MUL_VAL_ 1546 Configure_Slaves96_1F25_60 SubIndex_1F25 96-96;
SG_MUL_VAL_ 1546 Configure_Slaves95_1F25_5F SubIndex_1F25 95-95;
SG_MUL_VAL_ 1546 Configure_Slaves94_1F25_5E SubIndex_1F25 94-94;
SG_MUL_VAL_ 1546 Configure_Slaves93_1F25_5D SubIndex_1F25 93-93;
SG_MUL_VAL_ 1546 Configure_Slaves92_1F25_5C SubIndex_1F25 92-92;
SG_MUL_VAL_ 1546 Configure_Slaves91_1F25_5B SubIndex_1F25 91-91;
SG_MUL_VAL_ 1546 Configure_Slaves90_1F25_5A SubIndex_1F25 90-90;
SG_MUL_VAL_ 1546 Configure_Slaves89_1F25_59 SubIndex_1F25 89-89;
SG_MUL_VAL_ 1546 Configure_Slaves88_1F25_58 SubIndex_1F25 88-88;
SG_MUL_VAL_ 1546 Configure_Slaves87_1F25_57 SubIndex_1F25 87-87;
SG_MUL_VAL_ 1546 Configure_Slaves86_1F25_56 SubIndex_1F25 86-86;
SG_MUL_VAL_ 1546 Configure_Slaves85_1F25_55 SubIndex_1F25 85-85;
SG_MUL_VAL_ 1546 Configure_Slaves84_1F25_54 SubIndex_1F25 84-84;
SG_MUL_VAL_ 1546 Configure_Slaves83_1F25_53 SubIndex_1F25 83-83;
SG_MUL_VAL_ 1546 Configure_Slaves82_1F25_52 SubIndex_1F25 82-82;
SG_MUL_VAL_ 1546 Configure_Slaves81_1F25_51 SubIndex_1F25 81-81;
SG_MUL_VAL_ 1546 Configure_Slaves80_1F25_50 SubIndex_1F25 80-80;
SG_MUL_VAL_ 1546 Configure_Slaves79_1F25_4F SubIndex_1F25 79-79;
SG_MUL_VAL_ 1546 Configure_Slaves78_1F25_4E SubIndex_1F25 78-78;
SG_MUL_VAL_ 1546 Configure_Slaves77_1F25_4D SubIndex_1F25 77-77;
SG_MUL_VAL_ 1546 Configure_Slaves76_1F25_4C SubIndex_1F25 76-76;
SG_MUL_VAL_ 1546 Configure_Slaves75_1F25_4B SubIndex_1F25 75-75;
SG_MUL_VAL_ 1546 Configure_Slaves74_1F25_4A SubIndex_1F25 74-74;
SG_MUL_VAL_ 1546 Configure_Slaves73_1F25_49 SubIndex_1F25 73-73;
SG_MUL_VAL_ 1546 Configure_Slaves72_1F25_48 SubIndex_1F25 72-72;
SG_MUL_VAL_ 1546 Configure_Slaves71_1F25_47 SubIndex_1F25 71-71;
SG_MUL_VAL_ 1546 Configure_Slaves70_1F25_46 SubIndex_1F25 70-70;
SG_MUL_VAL_ 1546 Configure_Slaves69_1F25_45 SubIndex_1F25 69-69;
SG_MUL_VAL_ 1546 Configure_Slaves68_1F25_44 SubIndex_1F25 68-68;
SG_MUL_VAL_ 1546 Configure_Slaves67_1F25_43 SubIndex_1F25 67-67;
SG_MUL_VAL_ 1546 Configure_Slaves66_1F25_42 SubIndex_1F25 66-66;
SG_MUL_VAL_ 1546 Configure_Slaves65_1F25_41 SubIndex_1F25 65-65;
SG_MUL_VAL_ 1546 Configure_Slaves64_1F25_40 SubIndex_1F25 64-64;
SG_MUL_VAL_ 1546 Configure_Slaves63_1F25_3F SubIndex_1F25 63-63;
SG_MUL_VAL_ 1546 Configure_Slaves62_1F25_3E SubIndex_1F25 62-62;
SG_MUL_VAL_ 1546 Configure_Slaves61_1F25_3D SubIndex_1F25 61-61;
SG_MUL_VAL_ 1546 Configure_Slaves60_1F25_3C SubIndex_1F25 60-60;
SG_MUL_VAL_ 1546 Configure_Slaves59_1F25_3B SubIndex_1F25 59-59;
SG_MUL_VAL_ 1546 Configure_Slaves58_1F25_3A SubIndex_1F25 58-58;
SG_MUL_VAL_ 1546 Configure_Slaves57_1F25_39 SubIndex_1F25 57-57;
SG_MUL_VAL_ 1546 Configure_Slaves56_1F25_38 SubIndex_1F25 56-56;
SG_MUL_VAL_ 1546 Configure_Slaves55_1F25_37 SubIndex_1F25 55-55;
SG_MUL_VAL_ 1546 Configure_Slaves54_1F25_36 SubIndex_1F25 54-54;
SG_MUL_VAL_ 1546 Configure_Slaves53_1F25_35 SubIndex_1F25 53-53;
SG_MUL_VAL_ 1546 Configure_Slaves52_1F25_34 SubIndex_1F25 52-52;
SG_MUL_VAL_ 1546 Configure_Slaves51_1F25_33 SubIndex_1F25 51-51;
SG_MUL_VAL_ 1546 Configure_Slaves50_1F25_32 SubIndex_1F25 50-50;
SG_MUL_VAL_ 1546 Configure_Slaves49_1F25_31 SubIndex_1F25 49-49;
SG_MUL_VAL_ 1546 Configure_Slaves48_1F25_30 SubIndex_1F25 48-48;
SG_MUL_VAL_ 1546 Configure_Slaves47_1F25_2F SubIndex_1F25 47-47;
SG_MUL_VAL_ 1546 Configure_Slaves46_1F25_2E SubIndex_1F25 46-46;
SG_MUL_VAL_ 1546 Configure_Slaves45_1F25_2D SubIndex_1F25 45-45;
SG_MUL_VAL_ 1546 Configure_Slaves44_1F25_2C SubIndex_1F25 44-44;
SG_MUL_VAL_ 1546 Configure_Slaves43_1F25_2B SubIndex_1F25 43-43;
SG_MUL_VAL_ 1546 Configure_Slaves42_1F25_2A SubIndex_1F25 42-42;
SG_MUL_VAL_ 1546 Configure_Slaves41_1F25_29 SubIndex_1F25 41-41;
SG_MUL_VAL_ 1546 Configure_Slaves40_1F25_28 SubIndex_1F25 40-40;
SG_MUL_VAL_ 1546 Configure_Slaves39_1F25_27 SubIndex_1F25 39-39;
SG_MUL_VAL_ 1546 Configure_Slaves38_1F25_26 SubIndex_1F25 38-38;
SG_MUL_VAL_ 1546 Configure_Slaves37_1F25_25 SubIndex_1F25 37-37;
SG_MUL_VAL_ 1546 Configure_Slaves36_1F25_24 SubIndex_1F25 36-36;
SG_MUL_VAL_ 1546 Configure_Slaves35_1F25_23 SubIndex_1F25 35-35;
SG_MUL_VAL_ 1546 Configure_Slaves34_1F25_22 SubIndex_1F25 34-34;
SG_MUL_VAL_ 1546 Configure_Slaves33_1F25_21 SubIndex_1F25 33-33;
SG_MUL_VAL_ 1546 Configure_Slaves32_1F25_20 SubIndex_1F25 32-32;
SG_MUL_VAL_ 1546 Configure_Slaves31_1F25_1F SubIndex_1F25 31-31;
SG_MUL_VAL_ 1546 Configure_Slaves30_1F25_1E SubIndex_1F25 30-30;
SG_MUL_VAL_ 1546 Configure_Slaves29_1F25_1D SubIndex_1F25 29-29;
SG_MUL_VAL_ 1546 Configure_Slaves28_1F25_1C SubIndex_1F25 28-28;
SG_MUL_VAL_ 1546 Configure_Slaves27_1F25_1B SubIndex_1F25 27-27;
SG_MUL_VAL_ 1546 Configure_Slaves26_1F25_1A SubIndex_1F25 26-26;
SG_MUL_VAL_ 1546 Configure_Slaves25_1F25_19 SubIndex_1F25 25-25;
SG_MUL_VAL_ 1546 Configure_Slaves24_1F25_18 SubIndex_1F25 24-24;
SG_MUL_VAL_ 1546 Configure_Slaves23_1F25_17 SubIndex_1F25 23-23;
SG_MUL_VAL_ 1546 Configure_Slaves22_1F25_16 SubIndex_1F25 22-22;
SG_MUL_VAL_ 1546 Configure_Slaves21_1F25_15 SubIndex_1F25 21-21;
SG_MUL_VAL_ 1546 Configure_Slaves20_1F25_14 SubIndex_1F25 20-20;
SG_MUL_VAL_ 1546 Configure_Slaves19_1F25_13 SubIndex_1F25 19-19;
SG_MUL_VAL_ 1546 Configure_Slaves18_1F25_12 SubIndex_1F25 18-18;
SG_MUL_VAL_ 1546 Configure_Slaves17_1F25_11 SubIndex_1F25 17-17;
SG_MUL_VAL_ 1546 Configure_Slaves16_1F25_10 SubIndex_1F25 16-16;
SG_MUL_VAL_ 1546 Configure_Slaves15_1F25_0F SubIndex_1F25 15-15;
SG_MUL_VAL_ 1546 Configure_Slaves14_1F25_0E SubIndex_1F25 14-14;
SG_MUL_VAL_ 1546 Configure_Slaves13_1F25_0D SubIndex_1F25 13-13;
SG_MUL_VAL_ 1546 Configure_Slaves12_1F25_0C SubIndex_1F25 12-12;
SG_MUL_VAL_ 1546 Configure_Slaves11_1F25_0B SubIndex_1F25 11-11;
SG_MUL_VAL_ 1546 Configure_Slaves10_1F25_0A SubIndex_1F25 10-10;
SG_MUL_VAL_ 1546 Configure_Slaves9_1F25_09 SubIndex_1F25 9-9;
SG_MUL_VAL_ 1546 Configure_Slaves8_1F25_08 SubIndex_1F25 8-8;
SG_MUL_VAL_ 1546 Configure_Slaves7_1F25_07 SubIndex_1F25 7-7;
SG_MUL_VAL_ 1546 Configure_Slaves6_1F25_06 SubIndex_1F25 6-6;
SG_MUL_VAL_ 1546 Configure_Slaves5_1F25_05 SubIndex_1F25 5-5;
SG_MUL_VAL_ 1546 Configure_Slaves4_1F25_04 SubIndex_1F25 4-4;
SG_MUL_VAL_ 1546 Configure_Slaves3_1F25_03 SubIndex_1F25 3-3;
SG_MUL_VAL_ 1546 Configure_Slaves2_1F25_02 SubIndex_1F25 2-2;
SG_MUL_VAL_ 1546 Configure_Slaves1_1F25_01 SubIndex_1F25 1-1;
SG_MUL_VAL_ 1546 NrOfObjects_1F25_00 SubIndex_1F25 0-0;
SG_MUL_VAL_ 1546 SubIndex_1F25 Index 7973-7973;
SG_MUL_VAL_ 1546 NrOfObjects_1F22_00 SubIndex_1F22 0-0;
SG_MUL_VAL_ 1546 SubIndex_1F22 Index 7970-7970;
SG_MUL_VAL_ 1546 Safety_configuration_checks_0001 SubIndex_13FF 3-3;
SG_MUL_VAL_ 1546 Safety_configuration_checks_0002 SubIndex_13FF 2-2;
SG_MUL_VAL_ 1546 Safety_Checksum_13FF_01 SubIndex_13FF 1-1;
SG_MUL_VAL_ 1546 Safety_checksum_Number_of_e_0006 SubIndex_13FF 0-0;
SG_MUL_VAL_ 1546 SubIndex_13FF Index 5119-5119;
SG_MUL_VAL_ 1546 Configuration_valid_13FE SubIndex_13FE 0-0;
SG_MUL_VAL_ 1546 SubIndex_13FE Index 5118-5118;
SG_MUL_VAL_ 1546 SRDO3_mapping_inv_Byte1_1383_02 SubIndex_1383 2-2;
SG_MUL_VAL_ 1546 SRDO3_mapping_Byte1_1383_01 SubIndex_1383 1-1;
SG_MUL_VAL_ 1546 SRDO3_Number_of_mapped_obje_0000 SubIndex_1383 0-0;
SG_MUL_VAL_ 1546 SubIndex_1383 Index 4995-4995;
SG_MUL_VAL_ 1546 SRDO2_mapping_inv_Byte1_1382_02 SubIndex_1382 2-2;
SG_MUL_VAL_ 1546 SRDO2_mapping_Byte1_1382_01 SubIndex_1382 1-1;
SG_MUL_VAL_ 1546 SRDO2_Number_of_mapped_obje_0000 SubIndex_1382 0-0;
SG_MUL_VAL_ 1546 SubIndex_1382 Index 4994-4994;
SG_MUL_VAL_ 1546 SRDO1_mapping_inv_Byte1_1381_02 SubIndex_1381 2-2;
SG_MUL_VAL_ 1546 SRDO1_mapping_Byte1_1381_01 SubIndex_1381 1-1;
SG_MUL_VAL_ 1546 SRDO1_Number_of_mapped_obje_0006 SubIndex_1381 0-0;
SG_MUL_VAL_ 1546 SubIndex_1381 Index 4993-4993;
SG_MUL_VAL_ 1546 SRDO3_communication_par_COB_0000 SubIndex_1303 6-6;
SG_MUL_VAL_ 1546 SRDO3_communication_par_COB_0001 SubIndex_1303 5-5;
SG_MUL_VAL_ 1546 SRDO3_communication_par_Tra_0000 SubIndex_1303 4-4;
SG_MUL_VAL_ 1546 SRDO3_communication_srvt_ti_0000 SubIndex_1303 3-3;
SG_MUL_VAL_ 1546 SRDO3_communication_par_sct_0000 SubIndex_1303 2-2;
SG_MUL_VAL_ 1546 SRDO3_communication_par_Inf_0000 SubIndex_1303 1-1;
SG_MUL_VAL_ 1546 Highest_sub_index_supported_0031 SubIndex_1303 0-0;
SG_MUL_VAL_ 1546 SubIndex_1303 Index 4867-4867;
SG_MUL_VAL_ 1546 SRDO2_communication_par_COB_0000 SubIndex_1302 6-6;
SG_MUL_VAL_ 1546 SRDO2_communication_par_COB_0001 SubIndex_1302 5-5;
SG_MUL_VAL_ 1546 SRDO2_communication_par_Tra_0000 SubIndex_1302 4-4;
SG_MUL_VAL_ 1546 SRDO2_communication_srvt_ti_0000 SubIndex_1302 3-3;
SG_MUL_VAL_ 1546 SRDO2_communication_par_sct_0000 SubIndex_1302 2-2;
SG_MUL_VAL_ 1546 SRDO2_communication_par_Inf_0000 SubIndex_1302 1-1;
SG_MUL_VAL_ 1546 Highest_sub_index_supported_0032 SubIndex_1302 0-0;
SG_MUL_VAL_ 1546 SubIndex_1302 Index 4866-4866;
SG_MUL_VAL_ 1546 SRDO1_communication_par_COB_0012 SubIndex_1301 6-6;
SG_MUL_VAL_ 1546 SRDO1_communication_par_COB_0013 SubIndex_1301 5-5;
SG_MUL_VAL_ 1546 SRDO1_communication_par_Tra_0006 SubIndex_1301 4-4;
SG_MUL_VAL_ 1546 SRDO1_communication_srvt_ti_0000 SubIndex_1301 3-3;
SG_MUL_VAL_ 1546 SRDO1_communication_par_sct_0000 SubIndex_1301 2-2;
SG_MUL_VAL_ 1546 SRDO1_communication_par_Inf_0006 SubIndex_1301 1-1;
SG_MUL_VAL_ 1546 Highest_sub_index_supported_0033 SubIndex_1301 0-0;
SG_MUL_VAL_ 1546 SubIndex_1301 Index 4865-4865;
SG_MUL_VAL_ 1546 Serial_number_1018_04 SubIndex_1018 4-4;
SG_MUL_VAL_ 1546 Revision_number_1018_03 SubIndex_1018 3-3;
SG_MUL_VAL_ 1546 Product_Code_1018_02 SubIndex_1018 2-2;
SG_MUL_VAL_ 1546 Vendor_Id_1018_01 SubIndex_1018 1-1;
SG_MUL_VAL_ 1546 Highest_sub_index_supported_0034 SubIndex_1018 0-0;
SG_MUL_VAL_ 1546 SubIndex_1018 Index 4120-4120;
SG_MUL_VAL_ 1546 Producer_Heartbeat_Time_1017 SubIndex_1017 0-0;
SG_MUL_VAL_ 1546 SubIndex_1017 Index 4119-4119;
SG_MUL_VAL_ 1546 Consumer_Heartbeat_Time127__0000 SubIndex_1016 127-127;
SG_MUL_VAL_ 1546 Consumer_Heartbeat_Time126__0000 SubIndex_1016 126-126;
SG_MUL_VAL_ 1546 Consumer_Heartbeat_Time125__0000 SubIndex_1016 125-125;
SG_MUL_VAL_ 1546 Consumer_Heartbeat_Time124__0000 SubIndex_1016 124-124;
SG_MUL_VAL_ 1546 Consumer_Heartbeat_Time123__0000 SubIndex_1016 123-123;
SG_MUL_VAL_ 1546 Consumer_Heartbeat_Time122__0000 SubIndex_1016 122-122;
SG_MUL_VAL_ 1546 Consumer_Heartbeat_Time121__0000 SubIndex_1016 121-121;
SG_MUL_VAL_ 1546 Consumer_Heartbeat_Time120__0000 SubIndex_1016 120-120;
SG_MUL_VAL_ 1546 Consumer_Heartbeat_Time119__0000 SubIndex_1016 119-119;
SG_MUL_VAL_ 1546 Consumer_Heartbeat_Time118__0000 SubIndex_1016 118-118;
SG_MUL_VAL_ 1546 Consumer_Heartbeat_Time117__0000 SubIndex_1016 117-117;
SG_MUL_VAL_ 1546 Consumer_Heartbeat_Time116__0000 SubIndex_1016 116-116;
SG_MUL_VAL_ 1546 Consumer_Heartbeat_Time115__0000 SubIndex_1016 115-115;
SG_MUL_VAL_ 1546 Consumer_Heartbeat_Time114__0000 SubIndex_1016 114-114;
SG_MUL_VAL_ 1546 Consumer_Heartbeat_Time113__0000 SubIndex_1016 113-113;
SG_MUL_VAL_ 1546 Consumer_Heartbeat_Time112__0000 SubIndex_1016 112-112;
SG_MUL_VAL_ 1546 Consumer_Heartbeat_Time111__0000 SubIndex_1016 111-111;
SG_MUL_VAL_ 1546 Consumer_Heartbeat_Time110__0000 SubIndex_1016 110-110;
SG_MUL_VAL_ 1546 Consumer_Heartbeat_Time109__0000 SubIndex_1016 109-109;
SG_MUL_VAL_ 1546 Consumer_Heartbeat_Time108__0000 SubIndex_1016 108-108;
SG_MUL_VAL_ 1546 Consumer_Heartbeat_Time107__0000 SubIndex_1016 107-107;
SG_MUL_VAL_ 1546 Consumer_Heartbeat_Time106__0000 SubIndex_1016 106-106;
SG_MUL_VAL_ 1546 Consumer_Heartbeat_Time105__0000 SubIndex_1016 105-105;
SG_MUL_VAL_ 1546 Consumer_Heartbeat_Time104__0000 SubIndex_1016 104-104;
SG_MUL_VAL_ 1546 Consumer_Heartbeat_Time103__0000 SubIndex_1016 103-103;
SG_MUL_VAL_ 1546 Consumer_Heartbeat_Time102__0000 SubIndex_1016 102-102;
SG_MUL_VAL_ 1546 Consumer_Heartbeat_Time101__0000 SubIndex_1016 101-101;
SG_MUL_VAL_ 1546 Consumer_Heartbeat_Time100__0000 SubIndex_1016 100-100;
SG_MUL_VAL_ 1546 Consumer_Heartbeat_Time99_1_0000 SubIndex_1016 99-99;
SG_MUL_VAL_ 1546 Consumer_Heartbeat_Time98_1_0000 SubIndex_1016 98-98;
SG_MUL_VAL_ 1546 Consumer_Heartbeat_Time97_1_0000 SubIndex_1016 97-97;
SG_MUL_VAL_ 1546 Consumer_Heartbeat_Time96_1_0000 SubIndex_1016 96-96;
SG_MUL_VAL_ 1546 Consumer_Heartbeat_Time95_1_0000 SubIndex_1016 95-95;
SG_MUL_VAL_ 1546 Consumer_Heartbeat_Time94_1_0000 SubIndex_1016 94-94;
SG_MUL_VAL_ 1546 Consumer_Heartbeat_Time93_1_0000 SubIndex_1016 93-93;
SG_MUL_VAL_ 1546 Consumer_Heartbeat_Time92_1_0000 SubIndex_1016 92-92;
SG_MUL_VAL_ 1546 Consumer_Heartbeat_Time91_1_0000 SubIndex_1016 91-91;
SG_MUL_VAL_ 1546 Consumer_Heartbeat_Time90_1_0000 SubIndex_1016 90-90;
SG_MUL_VAL_ 1546 Consumer_Heartbeat_Time89_1_0000 SubIndex_1016 89-89;
SG_MUL_VAL_ 1546 Consumer_Heartbeat_Time88_1_0000 SubIndex_1016 88-88;
SG_MUL_VAL_ 1546 Consumer_Heartbeat_Time87_1_0000 SubIndex_1016 87-87;
SG_MUL_VAL_ 1546 Consumer_Heartbeat_Time86_1_0000 SubIndex_1016 86-86;
SG_MUL_VAL_ 1546 Consumer_Heartbeat_Time85_1_0000 SubIndex_1016 85-85;
SG_MUL_VAL_ 1546 Consumer_Heartbeat_Time84_1_0000 SubIndex_1016 84-84;
SG_MUL_VAL_ 1546 Consumer_Heartbeat_Time83_1_0000 SubIndex_1016 83-83;
SG_MUL_VAL_ 1546 Consumer_Heartbeat_Time82_1_0000 SubIndex_1016 82-82;
SG_MUL_VAL_ 1546 Consumer_Heartbeat_Time81_1_0000 SubIndex_1016 81-81;
SG_MUL_VAL_ 1546 Consumer_Heartbeat_Time80_1_0000 SubIndex_1016 80-80;
SG_MUL_VAL_ 1546 Consumer_Heartbeat_Time79_1_0000 SubIndex_1016 79-79;
SG_MUL_VAL_ 1546 Consumer_Heartbeat_Time78_1_0000 SubIndex_1016 78-78;
SG_MUL_VAL_ 1546 Consumer_Heartbeat_Time77_1_0000 SubIndex_1016 77-77;
SG_MUL_VAL_ 1546 Consumer_Heartbeat_Time76_1_0000 SubIndex_1016 76-76;
SG_MUL_VAL_ 1546 Consumer_Heartbeat_Time75_1_0000 SubIndex_1016 75-75;
SG_MUL_VAL_ 1546 Consumer_Heartbeat_Time74_1_0000 SubIndex_1016 74-74;
SG_MUL_VAL_ 1546 Consumer_Heartbeat_Time73_1_0000 SubIndex_1016 73-73;
SG_MUL_VAL_ 1546 Consumer_Heartbeat_Time72_1_0000 SubIndex_1016 72-72;
SG_MUL_VAL_ 1546 Consumer_Heartbeat_Time71_1_0000 SubIndex_1016 71-71;
SG_MUL_VAL_ 1546 Consumer_Heartbeat_Time70_1_0000 SubIndex_1016 70-70;
SG_MUL_VAL_ 1546 Consumer_Heartbeat_Time69_1_0000 SubIndex_1016 69-69;
SG_MUL_VAL_ 1546 Consumer_Heartbeat_Time68_1_0000 SubIndex_1016 68-68;
SG_MUL_VAL_ 1546 Consumer_Heartbeat_Time67_1_0000 SubIndex_1016 67-67;
SG_MUL_VAL_ 1546 Consumer_Heartbeat_Time66_1_0000 SubIndex_1016 66-66;
SG_MUL_VAL_ 1546 Consumer_Heartbeat_Time65_1_0000 SubIndex_1016 65-65;
SG_MUL_VAL_ 1546 Consumer_Heartbeat_Time64_1_0000 SubIndex_1016 64-64;
SG_MUL_VAL_ 1546 Consumer_Heartbeat_Time63_1_0000 SubIndex_1016 63-63;
SG_MUL_VAL_ 1546 Consumer_Heartbeat_Time62_1_0000 SubIndex_1016 62-62;
SG_MUL_VAL_ 1546 Consumer_Heartbeat_Time61_1_0000 SubIndex_1016 61-61;
SG_MUL_VAL_ 1546 Consumer_Heartbeat_Time60_1_0000 SubIndex_1016 60-60;
SG_MUL_VAL_ 1546 Consumer_Heartbeat_Time59_1_0000 SubIndex_1016 59-59;
SG_MUL_VAL_ 1546 Consumer_Heartbeat_Time58_1_0000 SubIndex_1016 58-58;
SG_MUL_VAL_ 1546 Consumer_Heartbeat_Time57_1_0000 SubIndex_1016 57-57;
SG_MUL_VAL_ 1546 Consumer_Heartbeat_Time56_1_0000 SubIndex_1016 56-56;
SG_MUL_VAL_ 1546 Consumer_Heartbeat_Time55_1_0000 SubIndex_1016 55-55;
SG_MUL_VAL_ 1546 Consumer_Heartbeat_Time54_1_0000 SubIndex_1016 54-54;
SG_MUL_VAL_ 1546 Consumer_Heartbeat_Time53_1_0000 SubIndex_1016 53-53;
SG_MUL_VAL_ 1546 Consumer_Heartbeat_Time52_1_0000 SubIndex_1016 52-52;
SG_MUL_VAL_ 1546 Consumer_Heartbeat_Time51_1_0000 SubIndex_1016 51-51;
SG_MUL_VAL_ 1546 Consumer_Heartbeat_Time50_1_0000 SubIndex_1016 50-50;
SG_MUL_VAL_ 1546 Consumer_Heartbeat_Time49_1_0000 SubIndex_1016 49-49;
SG_MUL_VAL_ 1546 Consumer_Heartbeat_Time48_1_0000 SubIndex_1016 48-48;
SG_MUL_VAL_ 1546 Consumer_Heartbeat_Time47_1_0000 SubIndex_1016 47-47;
SG_MUL_VAL_ 1546 Consumer_Heartbeat_Time46_1_0000 SubIndex_1016 46-46;
SG_MUL_VAL_ 1546 Consumer_Heartbeat_Time45_1_0000 SubIndex_1016 45-45;
SG_MUL_VAL_ 1546 Consumer_Heartbeat_Time44_1_0000 SubIndex_1016 44-44;
SG_MUL_VAL_ 1546 Consumer_Heartbeat_Time43_1_0000 SubIndex_1016 43-43;
SG_MUL_VAL_ 1546 Consumer_Heartbeat_Time42_1_0000 SubIndex_1016 42-42;
SG_MUL_VAL_ 1546 Consumer_Heartbeat_Time41_1_0000 SubIndex_1016 41-41;
SG_MUL_VAL_ 1546 Consumer_Heartbeat_Time40_1_0000 SubIndex_1016 40-40;
SG_MUL_VAL_ 1546 Consumer_Heartbeat_Time39_1_0000 SubIndex_1016 39-39;
SG_MUL_VAL_ 1546 Consumer_Heartbeat_Time38_1_0000 SubIndex_1016 38-38;
SG_MUL_VAL_ 1546 Consumer_Heartbeat_Time37_1_0000 SubIndex_1016 37-37;
SG_MUL_VAL_ 1546 Consumer_Heartbeat_Time36_1_0000 SubIndex_1016 36-36;
SG_MUL_VAL_ 1546 Consumer_Heartbeat_Time35_1_0000 SubIndex_1016 35-35;
SG_MUL_VAL_ 1546 Consumer_Heartbeat_Time34_1_0000 SubIndex_1016 34-34;
SG_MUL_VAL_ 1546 Consumer_Heartbeat_Time33_1_0000 SubIndex_1016 33-33;
SG_MUL_VAL_ 1546 Consumer_Heartbeat_Time32_1_0000 SubIndex_1016 32-32;
SG_MUL_VAL_ 1546 Consumer_Heartbeat_Time31_1_0000 SubIndex_1016 31-31;
SG_MUL_VAL_ 1546 Consumer_Heartbeat_Time30_1_0000 SubIndex_1016 30-30;
SG_MUL_VAL_ 1546 Consumer_Heartbeat_Time29_1_0000 SubIndex_1016 29-29;
SG_MUL_VAL_ 1546 Consumer_Heartbeat_Time28_1_0000 SubIndex_1016 28-28;
SG_MUL_VAL_ 1546 Consumer_Heartbeat_Time27_1_0000 SubIndex_1016 27-27;
SG_MUL_VAL_ 1546 Consumer_Heartbeat_Time26_1_0000 SubIndex_1016 26-26;
SG_MUL_VAL_ 1546 Consumer_Heartbeat_Time25_1_0000 SubIndex_1016 25-25;
SG_MUL_VAL_ 1546 Consumer_Heartbeat_Time24_1_0000 SubIndex_1016 24-24;
SG_MUL_VAL_ 1546 Consumer_Heartbeat_Time23_1_0000 SubIndex_1016 23-23;
SG_MUL_VAL_ 1546 Consumer_Heartbeat_Time22_1_0000 SubIndex_1016 22-22;
SG_MUL_VAL_ 1546 Consumer_Heartbeat_Time21_1_0000 SubIndex_1016 21-21;
SG_MUL_VAL_ 1546 Consumer_Heartbeat_Time20_1_0000 SubIndex_1016 20-20;
SG_MUL_VAL_ 1546 Consumer_Heartbeat_Time19_1_0000 SubIndex_1016 19-19;
SG_MUL_VAL_ 1546 Consumer_Heartbeat_Time18_1_0000 SubIndex_1016 18-18;
SG_MUL_VAL_ 1546 Consumer_Heartbeat_Time17_1_0000 SubIndex_1016 17-17;
SG_MUL_VAL_ 1546 Consumer_Heartbeat_Time16_1_0006 SubIndex_1016 16-16;
SG_MUL_VAL_ 1546 Consumer_Heartbeat_Time15_1_0006 SubIndex_1016 15-15;
SG_MUL_VAL_ 1546 Consumer_Heartbeat_Time14_1_0006 SubIndex_1016 14-14;
SG_MUL_VAL_ 1546 Consumer_Heartbeat_Time13_1_0006 SubIndex_1016 13-13;
SG_MUL_VAL_ 1546 Consumer_Heartbeat_Time12_1_0006 SubIndex_1016 12-12;
SG_MUL_VAL_ 1546 Consumer_Heartbeat_Time11_1_0006 SubIndex_1016 11-11;
SG_MUL_VAL_ 1546 Consumer_Heartbeat_Time10_1_0006 SubIndex_1016 10-10;
SG_MUL_VAL_ 1546 Consumer_Heartbeat_Time9_1016_09 SubIndex_1016 9-9;
SG_MUL_VAL_ 1546 Consumer_Heartbeat_Time8_1016_08 SubIndex_1016 8-8;
SG_MUL_VAL_ 1546 Consumer_Heartbeat_Time7_1016_07 SubIndex_1016 7-7;
SG_MUL_VAL_ 1546 Consumer_Heartbeat_Time6_1016_06 SubIndex_1016 6-6;
SG_MUL_VAL_ 1546 Consumer_Heartbeat_Time5_1016_05 SubIndex_1016 5-5;
SG_MUL_VAL_ 1546 Consumer_Heartbeat_Time4_1016_04 SubIndex_1016 4-4;
SG_MUL_VAL_ 1546 Consumer_Heartbeat_Time3_1016_03 SubIndex_1016 3-3;
SG_MUL_VAL_ 1546 Consumer_Heartbeat_Time2_1016_02 SubIndex_1016 2-2;
SG_MUL_VAL_ 1546 Consumer_Heartbeat_Time1_1016_01 SubIndex_1016 1-1;
SG_MUL_VAL_ 1546 NrOfObjects_1016_00 SubIndex_1016 0-0;
SG_MUL_VAL_ 1546 SubIndex_1016 Index 4118-4118;
SG_MUL_VAL_ 1546 Restore_all_Default_Paramet_0006 SubIndex_1011 1-1;
SG_MUL_VAL_ 1546 Highest_sub_index_supported_0035 SubIndex_1011 0-0;
SG_MUL_VAL_ 1546 SubIndex_1011 Index 4113-4113;
SG_MUL_VAL_ 1546 Save_all_Parameters_1010_01 SubIndex_1010 1-1;
SG_MUL_VAL_ 1546 Highest_sub_index_supported_0036 SubIndex_1010 0-0;
SG_MUL_VAL_ 1546 SubIndex_1010 Index 4112-4112;
SG_MUL_VAL_ 1546 Life_Time_Factor_100D SubIndex_100D 0-0;
SG_MUL_VAL_ 1546 SubIndex_100D Index 4109-4109;
SG_MUL_VAL_ 1546 Guard_Time_100C SubIndex_100C 0-0;
SG_MUL_VAL_ 1546 SubIndex_100C Index 4108-4108;
SG_MUL_VAL_ 1546 Sync_Window_Length_1007 SubIndex_1007 0-0;
SG_MUL_VAL_ 1546 SubIndex_1007 Index 4103-4103;
SG_MUL_VAL_ 1546 Communication_Cycle_Period_1006 SubIndex_1006 0-0;
SG_MUL_VAL_ 1546 SubIndex_1006 Index 4102-4102;
SG_MUL_VAL_ 1546 COB_ID_SYNC_1005 SubIndex_1005 0-0;
SG_MUL_VAL_ 1546 SubIndex_1005 Index 4101-4101;
SG_MUL_VAL_ 1546 Standard_error_field_1003_10 SubIndex_1003 16-16;
SG_MUL_VAL_ 1546 Standard_error_field_1003_0F SubIndex_1003 15-15;
SG_MUL_VAL_ 1546 Standard_error_field_1003_0E SubIndex_1003 14-14;
SG_MUL_VAL_ 1546 Standard_error_field_1003_0D SubIndex_1003 13-13;
SG_MUL_VAL_ 1546 Standard_error_field_1003_0C SubIndex_1003 12-12;
SG_MUL_VAL_ 1546 Standard_error_field_1003_0B SubIndex_1003 11-11;
SG_MUL_VAL_ 1546 Standard_error_field_1003_0A SubIndex_1003 10-10;
SG_MUL_VAL_ 1546 Standard_error_field_1003_09 SubIndex_1003 9-9;
SG_MUL_VAL_ 1546 Standard_error_field_1003_08 SubIndex_1003 8-8;
SG_MUL_VAL_ 1546 Standard_error_field_1003_07 SubIndex_1003 7-7;
SG_MUL_VAL_ 1546 Standard_error_field_1003_06 SubIndex_1003 6-6;
SG_MUL_VAL_ 1546 Standard_error_field_1003_05 SubIndex_1003 5-5;
SG_MUL_VAL_ 1546 Standard_error_field_1003_04 SubIndex_1003 4-4;
SG_MUL_VAL_ 1546 Standard_error_field_1003_03 SubIndex_1003 3-3;
SG_MUL_VAL_ 1546 Standard_error_field_1003_02 SubIndex_1003 2-2;
SG_MUL_VAL_ 1546 Standard_error_field_1003_01 SubIndex_1003 1-1;
SG_MUL_VAL_ 1546 Number_of_Errors_1003_00 SubIndex_1003 0-0;
SG_MUL_VAL_ 1546 SubIndex_1003 Index 4099-4099;
SG_MUL_VAL_ 1546 Error_Register_1001 SubIndex_1001 0-0;
SG_MUL_VAL_ 1546 SubIndex_1001 Index 4097-4097;
SG_MUL_VAL_ 1546 Device_Type_1000 SubIndex_1000 0-0;
SG_MUL_VAL_ 1546 SubIndex_1000 Index 4096-4096;
SG_MUL_VAL_ 1546 Index TransferType 1-1;
SG_MUL_VAL_ 1546 TransferType CCS 1-2;
SG_MUL_VAL_ 1546 NotUsedBytes CCS 1-2;
SG_MUL_VAL_ 1546 SizeIndicator CCS 1-2;
